VERSION ""

NS_ :

BS_:

BU_: PPIM HCP SGW IDCM EVCU2 BPCM

BO_ 1579 HYBRID_CHARGING_STATUS: 32 EVCU2
 SG_ HVBatteryVoltage_MinCal : 32|9@0+ (1,0) [0|510] "V"  IDCM,BPCM
 SG_ HVBatteryVoltage_MaxCal : 16|9@0+ (1,0) [0|510] "V"  IDCM,BPCM
 SG_ HVBatteryCurrent_MaxCal : 63|8@0+ (0.25,-32) [-32|31.5] "Amp"  IDCM,BPCM
 SG_ ChargeSystemFaultReason : 55|8@0+ (1,0) [0|254] "-"  IDCM
 SG_ ACCurrent_MaxCal : 0|9@0+ (0.25,-31.5) [-31.5|50] "Amp"  IDCM,BPCM
 SG_ ChargingLevel : 4|4@0+ (1,0) [0|14] "-"  IDCM,SGW,BPCM
 SG_ OBCM_PLUG_STS : 23|2@0+ (1,0) [0|3] ""  IDCM
 SG_ VDCM_UDCChrgr : 71|16@0+ (0.1,0) [0|6553.5] "V"  IDCM
 SG_ VDCM_IDCChrgr : 87|16@0+ (0.1,0) [0|6553.5] "A"  IDCM
 SG_ ChargeSystemSts : 7|3@0+ (1,0) [0|6] "-"  EVCU2,IDCM,BPCM
 SG_ ChargeSystemFault : 17|1@0+ (1,0) [0|1] "-"  IDCM
 SG_ CRC_HYBRID_CHARGING_STATUS : 191|8@0+ (1,0) [0|255] "-"  IDCM
 SG_ MessageCounter_HYBRID_CHARGING_S : 179|4@0+ (1,0) [0|15] "-"  IDCM

BO_ 478 HYBRID_CHARGING_COMMAND: 32 EVCU2
 SG_ LVDC_VoltageSetpoint : 111|8@0+ (0.0625,0) [0|15.875] "V"  BPCM
 SG_ LVDC_SystemVoltageAct : 64|9@0+ (0.04,0) [0|20.04] "V"  BPCM
 SG_ LVDC_CurrentSetpoint : 32|9@0+ (1,-255) [-255|255] "Amp"  BPCM
 SG_ HVInverterVoltage_Rational : 16|9@0+ (1,0) [0|510] "V"  BPCM
 SG_ HVDC_VoltageSetpoint : 48|9@0+ (1,0) [0|510] "V"  BPCM
 SG_ HVDC_CurrentSetpoint : 103|8@0+ (1,-125) [-125|129] "Amp"  BPCM
 SG_ EchargeSOCRange_ePT : 118|7@0+ (1,0) [0|100] "%" Vector__XXX
 SG_ CRC_HYBRID_CHARGING_COMMAND : 191|8@0+ (1,0) [0|255] "-"  IDCM,BPCM
 SG_ VoltageRequest : 4|13@0+ (0.1,0) [0|819.1] "Volts"  IDCM
 SG_ OBC_ModeRequest : 23|3@0+ (1,0) [0|6] "-"  IDCM
 SG_ OBC_ControlMethod : 38|2@0+ (1,0) [0|2] "-"  IDCM
 SG_ MainHV_ContactorCommand : 7|3@0+ (1,0) [0|7] "-"  BPCM
 SG_ J1772_CloseS2 : 51|1@0+ (1,0) [0|1] "-"  IDCM
 SG_ HVInverterVoltage_RationalV : 39|1@0+ (1,0) [0|1] "-"  BPCM
 SG_ HVBatCoolantLevelLow : 50|2@0+ (1,0) [0|2] "-"  BPCM
 SG_ DCDC_OperationModeEnable : 20|4@0+ (1,0) [0|14] "-"  BPCM
 SG_ ClearLegislatedDiagInfo : 52|1@0+ (1,0) [0|1] "-"  BPCM
 SG_ OBC_OperativeModeReq : 87|4@0+ (1,0) [0|14] "-"  IDCM
 SG_ HV_Volt_Min_Thrsh : 138|11@0+ (1,0) [0|2047] "V"  IDCM
 SG_ HV_Volt_Max_Thrsh : 133|11@0+ (1,0) [0|2047] "V"  IDCM
 SG_ DC_Curr_Max_Thrsh : 127|10@0+ (1,-511) [-511|512] "A"  IDCM
 SG_ ChargeEnable : 171|2@0+ (1,0) [0|2] "-"  IDCM
 SG_ AC_Curr_Min_Thrsh : 165|10@0+ (1,-511) [-511|512] "A"  IDCM
 SG_ AC_Curr_Max_Thrsh : 159|10@0+ (1,-511) [-511|512] "A"  IDCM
 SG_ CurrentRequest : 81|10@0+ (0.1,-32) [-32|70.3] "A"  IDCM
 SG_ VDCM_StsWldgReq : 83|1@0+ (1,0) [0|1] "-"  IDCM
 SG_ VDCM_SessnStopReq : 82|1@0+ (1,0) [0|1] "-"  IDCM
 SG_ VDCM_StsSWWldgReq : 55|2@0+ (1,0) [0|3] "-" Vector__XXX
 SG_ MessageCounter_HYBRID_CHARGING_C : 179|4@0+ (1,0) [0|15] "-"  IDCM,BPCM
 SG_ MaxCurrentAllwd : 71|6@0+ (1,0) [0|63] "A"  IDCM

BO_ 1578 HV_CHARGER2: 32 IDCM
 SG_ OBC_IdleTimeSec : 71|16@0+ (3,0) [0|196602] "sec"  EVCU2
 SG_ OBC_IdleTimeMin : 87|16@0+ (1,0) [0|65534] "min"  EVCU2
 SG_ OBC_ChargeTimeSec : 39|16@0+ (3,0) [0|196602] "sec"  EVCU2
 SG_ OBC_ChargeTimeMin : 55|16@0+ (1,0) [0|65534] "min"  EVCU2
 SG_ Charging_WHr : 23|16@0+ (1,0) [0|65534] "WHr"  EVCU2
 SG_ OnboardChargerReady : 116|2@0+ (1,0) [0|2] "-"  EVCU2
 SG_ OnboardChargerMode : 114|4@0+ (1,0) [0|15] "-"  EVCU2
 SG_ OBC_WakeReason : 107|4@0+ (1,0) [0|7] "-"  EVCU2
 SG_ OBC_GenericFailSts : 125|1@0+ (1,0) [0|1] "-"  EVCU2
 SG_ OBC_FaultReason : 102|7@0+ (1,0) [0|126] "-"  EVCU2
 SG_ OBC_EVServiceLampOn : 124|1@0+ (1,0) [0|1] "-"  EVCU2
 SG_ OBC_EVServiceLampFlash : 123|1@0+ (1,0) [0|1] "-"  EVCU2
 SG_ OBC_CurrentFailureSts : 121|1@0+ (1,0) [0|1] "-"  EVCU2
 SG_ OBC_ChargingFaultSts : 110|3@0+ (1,0) [0|7] "-"  EVCU2
 SG_ OBC_ChargeFailure : 120|1@0+ (1,0) [0|1] "-"  EVCU2
 SG_ OBC_CaptureEnvironmentData : 119|1@0+ (1,0) [0|1] "-"  EVCU2
 SG_ ACplug_PwrMax : 7|16@0+ (1,-32767) [-32767|32767] "W"  EVCU2
 SG_ OBC_Prox : 159|8@0+ (0.05,0) [0|12.75] "V"  EVCU2
 SG_ OBC_Pilot : 151|8@0+ (0.05,0) [0|12.75] "V"  EVCU2
 SG_ OBCM_PrechargeSts : 167|2@0+ (1,0) [0|3] "-"  EVCU2
 SG_ ChrgFailSts : 165|3@0+ (1,0) [0|7] ""  EVCU2

BO_ 1372 DUALCHARGER_THERMAL: 32 IDCM
 SG_ OBC_Temp4 : 63|8@0+ (1,-40) [-40|214] "°C"  EVCU2
 SG_ OBC_Temp3 : 55|8@0+ (1,-40) [-40|214] "°C"  EVCU2
 SG_ OBC_Temp2 : 47|8@0+ (1,-40) [-40|214] "°C"  EVCU2
 SG_ OBC_Temp1 : 39|8@0+ (1,-40) [-40|214] "°C"  EVCU2

BO_ 2564682064 DIAGNOSTIC_ROE_IDCM: 8 IDCM
 SG_ N_PDU_18DDF150 : 7|64@0+ (1,0) [0|0] ""  SGW

BO_ 2564682059 DIAGNOSTIC_ROE_HCP: 8 HCP
 SG_ N_PDU_18DDF14B : 7|64@0+ (1,0) [0|0] ""  SGW

BO_ 2564682320 DIAGNOSTIC_ROE_FD_IDCM: 64 IDCM
 SG_ N_PDU_18DDF250 : 7|64@0+ (1,0) [0|0] ""  SGW

BO_ 2564682315 DIAGNOSTIC_ROE_FD_HCP: 64 HCP
 SG_ N_PDU_18DDF24B : 7|64@0+ (1,0) [0|0] ""  SGW

BO_ 2564682308 DIAGNOSTIC_ROE_FD_BPCM: 64 BPCM
 SG_ N_PDU_18DDF244 : 7|64@0+ (1,0) [0|0] ""  SGW,HCP

BO_ 2564682052 DIAGNOSTIC_ROE_BPCM: 8 BPCM
 SG_ N_PDU_18DDF144 : 7|64@0+ (1,0) [0|0] ""  SGW

BO_ 2564485712 DIAGNOSTIC_RESPONSE_FD_IDCM: 64 IDCM
 SG_ N_PDU_18DAF250 : 7|64@0+ (1,0) [0|0] ""  SGW

BO_ 2564485707 DIAGNOSTIC_RESPONSE_FD_HCP: 64 HCP
 SG_ N_PDU_18DAF24B : 7|64@0+ (1,0) [0|0] ""  SGW

BO_ 2564485700 DIAGNOSTIC_RESPONSE_FD_BPCM: 64 BPCM
 SG_ N_PDU_18DAF244 : 7|64@0+ (1,0) [0|0] ""  SGW,HCP

BO_ 2564444402 DIAGNOSTIC_REQUEST_FD_IDCM: 64 SGW
 SG_ N_PDU_18DA50F2 : 7|64@0+ (1,0) [0|0] ""  IDCM

BO_ 2564443122 DIAGNOSTIC_REQUEST_FD_HCP: 64 SGW
 SG_ N_PDU_18DA4BF2 : 7|64@0+ (1,0) [0|0] ""  HCP

BO_ 2564441330 DIAGNOSTIC_REQUEST_FD_BPCM: 64 SGW
 SG_ N_PDU_18DA44F2 : 7|64@0+ (1,0) [0|0] ""  BPCM

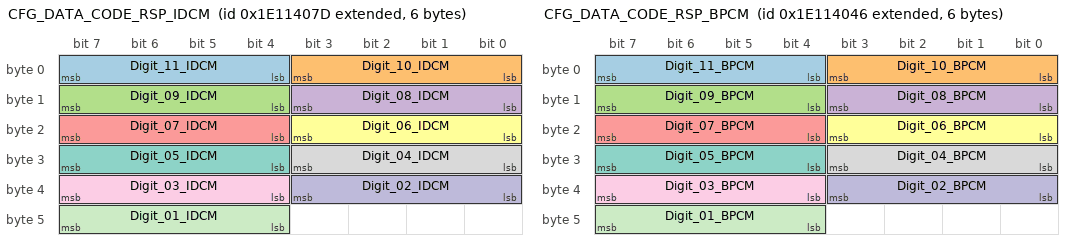
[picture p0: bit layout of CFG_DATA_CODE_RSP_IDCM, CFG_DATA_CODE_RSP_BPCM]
BO_ 2651930749 CFG_DATA_CODE_RSP_IDCM: 6 IDCM
 SG_ Digit_11_IDCM : 7|4@0+ (1,0) [0|15] "-"  EVCU2,SGW
 SG_ Digit_10_IDCM : 3|4@0+ (1,0) [0|15] "-"  EVCU2,SGW
 SG_ Digit_09_IDCM : 15|4@0+ (1,0) [0|15] "-"  EVCU2,SGW
 SG_ Digit_08_IDCM : 11|4@0+ (1,0) [0|15] "-"  EVCU2,SGW
 SG_ Digit_07_IDCM : 23|4@0+ (1,0) [0|15] "-"  EVCU2,SGW
 SG_ Digit_06_IDCM : 19|4@0+ (1,0) [0|15] "-"  EVCU2,SGW
 SG_ Digit_05_IDCM : 31|4@0+ (1,0) [0|15] "-"  EVCU2,SGW
 SG_ Digit_04_IDCM : 27|4@0+ (1,0) [0|15] "-"  EVCU2,SGW
 SG_ Digit_03_IDCM : 39|4@0+ (1,0) [0|15] "-"  EVCU2,SGW
 SG_ Digit_02_IDCM : 35|4@0+ (1,0) [0|15] "-"  EVCU2,SGW
 SG_ Digit_01_IDCM : 47|4@0+ (1,0) [0|15] "-"  EVCU2,SGW

BO_ 2651930694 CFG_DATA_CODE_RSP_BPCM: 6 BPCM
 SG_ Digit_11_BPCM : 7|4@0+ (1,0) [0|15] "-"  EVCU2,HCP
 SG_ Digit_10_BPCM : 3|4@0+ (1,0) [0|15] "-"  EVCU2,HCP
 SG_ Digit_09_BPCM : 15|4@0+ (1,0) [0|15] "-"  EVCU2,HCP
 SG_ Digit_08_BPCM : 11|4@0+ (1,0) [0|15] "-"  EVCU2,HCP
 SG_ Digit_07_BPCM : 23|4@0+ (1,0) [0|15] "-"  EVCU2,HCP
 SG_ Digit_06_BPCM : 19|4@0+ (1,0) [0|15] "-"  EVCU2,HCP
 SG_ Digit_05_BPCM : 31|4@0+ (1,0) [0|15] "-"  EVCU2,HCP
 SG_ Digit_04_BPCM : 27|4@0+ (1,0) [0|15] "-"  EVCU2,HCP
 SG_ Digit_03_BPCM : 39|4@0+ (1,0) [0|15] "-"  EVCU2,HCP
 SG_ Digit_02_BPCM : 35|4@0+ (1,0) [0|15] "-"  EVCU2,HCP
 SG_ Digit_01_BPCM : 47|4@0+ (1,0) [0|15] "-"  EVCU2,HCP

BO_ 2654339170 PDC_INFO_FD_HCP: 12 HCP
 SG_ GenericFailSts_FD03_HCP : 5|1@0+ (1,0) [0|1] ""  SGW
 SG_ EOL_FD03_HCP : 7|1@0+ (1,0) [0|1] "-"  SGW
 SG_ CurrentFailSts_FD03_HCP : 6|1@0+ (1,0) [0|1] ""  SGW
 SG_ WakeupSource_FD03_HCP : 23|8@0+ (1,0) [0|255] ""  SGW
 SG_ PreviousCanNMState_FD03_HCP : 11|4@0+ (1,0) [0|15] ""  SGW
 SG_ DES_FD03_HCP : 4|2@0+ (1,0) [0|3] ""  SGW
 SG_ CurrentCanNMState_FD03_HCP : 15|4@0+ (1,0) [0|15] ""  SGW
 SG_ StayActiveSource_FD03_HCP : 31|64@0+ (1,0) [0|1.84467440737096E+019] ""  SGW

BO_ 1845 HVBATTERY_RM_BATTERYID: 64 BPCM
 SG_ HVBatSerialLength : 199|8@0+ (1,0) [0|254] ""  SGW
 SG_ HVBatSerialNumber : 7|192@0+ (1,0) [0|0] ""  SGW

BO_ 1460 FOTA_MASTER: 32 SGW
 SG_ FOTA_Status : 7|4@0+ (1,0) [0|15] ""  EVCU2,IDCM,BPCM

BO_ 1374 HVBATTERY4: 48 BPCM
 SG_ HVBatPackVoltage_MaxAllowedV : 6|1@0+ (1,0) [0|0] "-"  HCP
 SG_ HVBatCellVoltage_MinAllowedV : 5|1@0+ (1,0) [0|0] "-"  HCP
 SG_ HVBatCellVoltage_MinAllowed : 19|12@0+ (0.001,1.5) [1.5|4.5] "Volts"  HCP
 SG_ HVBatCellVoltage_MaxAllowedV : 4|1@0+ (1,0) [0|0] "-"  HCP
 SG_ HVBatCellVoltage_MaxAllowed : 3|12@0+ (0.001,1.5) [1.5|4.5] "Volts"  HCP
 SG_ HVBatCellVoltage_LowThreshold : 84|13@0+ (0.001,0) [0|5] "Volts"  HCP
 SG_ HVBatCellVoltage_HighThreshold : 68|13@0+ (0.001,0) [0|5] "Volts"  HCP
 SG_ HVBatCapacity_AmpHrV : 22|1@0+ (1,0) [0|0] "-" Vector__XXX
 SG_ HVBatCapacity_AmpHr : 114|11@0+ (0.1,0) [0|200] "Ah" Vector__XXX
 SG_ HVBatRemainingAhCapacity : 186|11@0+ (0.1,0) [0|200] "Ah"  HCP
 SG_ HVBatDischargeAmpHrs : 167|24@0+ (0.1,0) [0|300000] "Ah"  HCP
 SG_ HVBatChargeAmpHrs : 143|24@0+ (0.1,0) [0|300000] "Ah"  HCP
 SG_ BSGPackVoltage_MaxAllowed : 39|7@0+ (1,0) [20|70] "V"  HCP

BO_ 1038 HVBATTERY_STATUS: 32 BPCM
 SG_ Precharge_Closed : 121|1@0+ (1,0) [0|1] ""  HCP
 SG_ Positive_Main_Closed : 122|1@0+ (1,0) [0|1] ""  HCP
 SG_ Negative_Main_Closed : 123|1@0+ (1,0) [0|1] ""  HCP
 SG_ HBCO_TempSensorRationality : 125|1@0+ (1,0) [0|1] ""  HCP
 SG_ HBCO_Sensor_Fault : 126|1@0+ (1,0) [0|1] ""  HCP
 SG_ HBCO_PackUndertemp : 105|1@0+ (1,0) [0|1] ""  HCP
 SG_ HBCO_PackOvertemp : 106|1@0+ (1,0) [0|1] ""  HCP
 SG_ HBCO_OverCurrent : 127|1@0+ (1,0) [0|1] ""  HCP
 SG_ HBCO_Micro_Failure : 112|1@0+ (1,0) [0|1] ""  HCP
 SG_ HBCO_Main_Fuse_Failure : 113|1@0+ (1,0) [0|1] ""  HCP
 SG_ HBCO_Isolation_Fault : 114|1@0+ (1,0) [0|1] ""  HCP
 SG_ HBCO_Internal_CommFault : 117|1@0+ (1,0) [0|1] ""  HCP
 SG_ HBCO_Impact_Detected : 115|1@0+ (1,0) [0|1] ""  HCP
 SG_ HBCO_HVIL_Failure : 116|1@0+ (1,0) [0|1] ""  HCP
 SG_ HBCO_External_CommFault : 118|1@0+ (1,0) [0|1] ""  HCP
 SG_ HBCO_CellUndervoltage : 119|1@0+ (1,0) [0|1] ""  HCP
 SG_ HBCO_CellOvervoltage : 104|1@0+ (1,0) [0|1] ""  HCP
 SG_ HBCO_12V_Low : 107|1@0+ (1,0) [0|1] ""  HCP
 SG_ HBCO_12V_High : 108|1@0+ (1,0) [0|1] ""  HCP
 SG_ HBCNC_TempSensorRationality : 110|1@0+ (1,0) [0|1] ""  HCP
 SG_ HBCNC_SOH_Failure : 111|1@0+ (1,0) [0|1] ""  HCP
 SG_ HBCNC_Sensor_Failure : 96|1@0+ (1,0) [0|1] ""  HCP
 SG_ HBCNC_Precharge_Failure : 97|1@0+ (1,0) [0|1] ""  HCP
 SG_ HBCNC_PackUndervoltage : 98|1@0+ (1,0) [0|1] ""  HCP
 SG_ HBCNC_PackUndertemp : 93|1@0+ (1,0) [0|1] ""  HCP
 SG_ HBCNC_PackOvervoltage : 99|1@0+ (1,0) [0|1] ""  HCP
 SG_ HBCNC_PackOvertemp : 94|1@0+ (1,0) [0|1] ""  HCP
 SG_ HBCNC_Micro_Failure : 100|1@0+ (1,0) [0|1] ""  HCP
 SG_ HBCNC_Main_Fuse_Failure : 101|1@0+ (1,0) [0|1] ""  HCP
 SG_ HBCNC_Isolation_Fault : 102|1@0+ (1,0) [0|1] ""  HCP
 SG_ HBCNC_Internal_CommFault : 89|1@0+ (1,0) [0|1] ""  HCP
 SG_ HBCNC_Impact_Detected : 103|1@0+ (1,0) [0|1] ""  HCP
 SG_ HBCNC_External_CommFault : 90|1@0+ (1,0) [0|1] ""  HCP
 SG_ HBCNC_EEPROM_Fault : 88|1@0+ (1,0) [0|1] ""  HCP
 SG_ HBCNC_Contactors_Welded : 109|1@0+ (1,0) [0|1] ""  HCP
 SG_ HBCNC_CellUndervoltage : 91|1@0+ (1,0) [0|1] ""  HCP
 SG_ HBCNC_CellOvervoltage : 92|1@0+ (1,0) [0|1] ""  HCP
 SG_ HBCNC_12V_Low : 95|1@0+ (1,0) [0|1] ""  HCP
 SG_ HBCNC_12V_High : 38|1@0+ (1,0) [0|1] ""  HCP
 SG_ BPCM_DTC_Status6 : 87|3@0+ (1,0) [0|6] ""  HCP
 SG_ BPCM_DTC_Status5 : 79|3@0+ (1,0) [0|6] ""  HCP
 SG_ BPCM_DTC_Status4 : 71|3@0+ (1,0) [0|6] ""  HCP
 SG_ BPCM_DTC_Status3 : 63|3@0+ (1,0) [0|6] ""  HCP
 SG_ BPCM_DTC_Status2 : 55|3@0+ (1,0) [0|6] ""  HCP
 SG_ BPCM_DTC_Status1 : 47|3@0+ (1,0) [0|6] ""  HCP
 SG_ BPCM_DTC_Index6 : 84|5@0+ (1,0) [0|31] ""  HCP
 SG_ BPCM_DTC_Index5 : 76|5@0+ (1,0) [0|31] ""  HCP
 SG_ BPCM_DTC_Index4 : 68|5@0+ (1,0) [0|31] ""  HCP
 SG_ BPCM_DTC_Index3 : 60|5@0+ (1,0) [0|31] ""  HCP
 SG_ BPCM_DTC_Index2 : 52|5@0+ (1,0) [0|31] ""  HCP
 SG_ BPCM_DTC_Index1 : 44|5@0+ (1,0) [0|31] ""  HCP
 SG_ BPCM_CalibrationVN : 31|8@0+ (1,0) [0|255] ""  HCP
 SG_ BPCM_CalibrationID : 37|6@0+ (1,0) [0|62] ""  HCP
 SG_ BPCM_Odometer : 7|24@0+ (0.1,0) [0|1677720] "km"  HCP

BO_ 1852 HVBATTERY_RM_CELLS8: 64 BPCM
 SG_ HVBatCellVoltage_Cell192 : 36|13@0+ (0.001,0) [0|5] "V" Vector__XXX
 SG_ HVBatCellVoltage_Cell191 : 20|13@0+ (0.001,0) [0|5] "V" Vector__XXX
 SG_ HVBatCellVoltage_Cell190 : 4|13@0+ (0.001,0) [0|5] "V" Vector__XXX
 SG_ HVBatCellVoltage_Cell216 : 420|13@0+ (0.001,0) [0|5] "V"  SGW
 SG_ HVBatCellVoltage_Cell215 : 404|13@0+ (0.001,0) [0|5] "V" Vector__XXX
 SG_ HVBatCellVoltage_Cell214 : 388|13@0+ (0.001,0) [0|5] "V" Vector__XXX
 SG_ HVBatCellVoltage_Cell213 : 372|13@0+ (0.001,0) [0|5] "V" Vector__XXX
 SG_ HVBatCellVoltage_Cell212 : 356|13@0+ (0.001,0) [0|5] "V" Vector__XXX
 SG_ HVBatCellVoltage_Cell211 : 340|13@0+ (0.001,0) [0|5] "V" Vector__XXX
 SG_ HVBatCellVoltage_Cell210 : 324|13@0+ (0.001,0) [0|5] "V" Vector__XXX
 SG_ HVBatCellVoltage_Cell209 : 308|13@0+ (0.001,0) [0|5] "V" Vector__XXX
 SG_ HVBatCellVoltage_Cell208 : 292|13@0+ (0.001,0) [0|5] "V" Vector__XXX
 SG_ HVBatCellVoltage_Cell207 : 276|13@0+ (0.001,0) [0|5] "V" Vector__XXX
 SG_ HVBatCellVoltage_Cell206 : 260|13@0+ (0.001,0) [0|5] "V" Vector__XXX
 SG_ HVBatCellVoltage_Cell205 : 244|13@0+ (0.001,0) [0|5] "V" Vector__XXX
 SG_ HVBatCellVoltage_Cell204 : 228|13@0+ (0.001,0) [0|5] "V" Vector__XXX
 SG_ HVBatCellVoltage_Cell203 : 212|13@0+ (0.001,0) [0|5] "V" Vector__XXX
 SG_ HVBatCellVoltage_Cell202 : 196|13@0+ (0.001,0) [0|5] "V" Vector__XXX
 SG_ HVBatCellVoltage_Cell201 : 180|13@0+ (0.001,0) [0|5] "V" Vector__XXX
 SG_ HVBatCellVoltage_Cell200 : 164|13@0+ (0.001,0) [0|5] "V" Vector__XXX
 SG_ HVBatCellVoltage_Cell198 : 132|13@0+ (0.001,0) [0|5] "V" Vector__XXX
 SG_ HVBatCellVoltage_Cell197 : 116|13@0+ (0.001,0) [0|5] "V" Vector__XXX
 SG_ HVBatCellVoltage_Cell196 : 100|13@0+ (0.001,0) [0|5] "V" Vector__XXX
 SG_ HVBatCellVoltage_Cell195 : 84|13@0+ (0.001,0) [0|5] "V" Vector__XXX
 SG_ HVBatCellVoltage_Cell194 : 68|13@0+ (0.001,0) [0|5] "V" Vector__XXX
 SG_ HVBatCellVoltage_Cell193 : 52|13@0+ (0.001,0) [0|5] "V" Vector__XXX

BO_ 1851 HVBATTERY_RM_CELLS7: 64 BPCM
 SG_ HVBatCellVoltage_Cell189 : 420|13@0+ (0.001,0) [0|5] "V" Vector__XXX
 SG_ HVBatCellVoltage_Cell188 : 404|13@0+ (0.001,0) [0|5] "V" Vector__XXX
 SG_ HVBatCellVoltage_Cell187 : 388|13@0+ (0.001,0) [0|5] "V" Vector__XXX
 SG_ HVBatCellVoltage_Cell186 : 372|13@0+ (0.001,0) [0|5] "V" Vector__XXX
 SG_ HVBatCellVoltage_Cell185 : 356|13@0+ (0.001,0) [0|5] "V" Vector__XXX
 SG_ HVBatCellVoltage_Cell184 : 340|13@0+ (0.001,0) [0|5] "V" Vector__XXX
 SG_ HVBatCellVoltage_Cell183 : 324|13@0+ (0.001,0) [0|5] "V"  SGW
 SG_ HVBatCellVoltage_Cell182 : 308|13@0+ (0.001,0) [0|5] "V"  SGW
 SG_ HVBatCellVoltage_Cell181 : 292|13@0+ (0.001,0) [0|5] "V"  SGW
 SG_ HVBatCellVoltage_Cell180 : 276|13@0+ (0.001,0) [0|5] "V"  SGW
 SG_ HVBatCellVoltage_Cell179 : 260|13@0+ (0.001,0) [0|5] "V"  SGW
 SG_ HVBatCellVoltage_Cell178 : 244|13@0+ (0.001,0) [0|5] "V"  SGW
 SG_ HVBatCellVoltage_Cell177 : 228|13@0+ (0.001,0) [0|5] "V"  SGW
 SG_ HVBatCellVoltage_Cell176 : 212|13@0+ (0.001,0) [0|5] "V"  SGW
 SG_ HVBatCellVoltage_Cell175 : 196|13@0+ (0.001,0) [0|5] "V"  SGW
 SG_ HVBatCellVoltage_Cell174 : 180|13@0+ (0.001,0) [0|5] "V"  SGW
 SG_ HVBatCellVoltage_Cell173 : 164|13@0+ (0.001,0) [0|5] "V"  SGW
 SG_ HVBatCellVoltage_Cell172 : 148|13@0+ (0.001,0) [0|5] "V"  SGW
 SG_ HVBatCellVoltage_Cell171 : 132|13@0+ (0.001,0) [0|5] "V"  SGW
 SG_ HVBatCellVoltage_Cell170 : 116|13@0+ (0.001,0) [0|5] "V"  SGW
 SG_ HVBatCellVoltage_Cell169 : 100|13@0+ (0.001,0) [0|5] "V"  SGW
 SG_ HVBatCellVoltage_Cell168 : 84|13@0+ (0.001,0) [0|5] "V"  SGW
 SG_ HVBatCellVoltage_Cell167 : 68|13@0+ (0.001,0) [0|5] "V"  SGW
 SG_ HVBatCellVoltage_Cell166 : 52|13@0+ (0.001,0) [0|5] "V"  SGW
 SG_ HVBatCellVoltage_Cell165 : 36|13@0+ (0.001,0) [0|5] "V"  SGW
 SG_ HVBatCellVoltage_Cell164 : 20|13@0+ (0.001,0) [0|5] "V"  SGW
 SG_ HVBatCellVoltage_Cell163 : 4|13@0+ (0.001,0) [0|5] "V"  SGW

BO_ 1850 HVBATTERY_RM_CELLS6: 64 BPCM
 SG_ HVBatCellVoltage_Cell162 : 420|13@0+ (0.001,0) [0|5] "V"  SGW
 SG_ HVBatCellVoltage_Cell161 : 404|13@0+ (0.001,0) [0|5] "V"  SGW
 SG_ HVBatCellVoltage_Cell160 : 388|13@0+ (0.001,0) [0|5] "V"  SGW
 SG_ HVBatCellVoltage_Cell159 : 372|13@0+ (0.001,0) [0|5] "V"  SGW
 SG_ HVBatCellVoltage_Cell158 : 356|13@0+ (0.001,0) [0|5] "V"  SGW
 SG_ HVBatCellVoltage_Cell157 : 340|13@0+ (0.001,0) [0|5] "V"  SGW
 SG_ HVBatCellVoltage_Cell156 : 324|13@0+ (0.001,0) [0|5] "V"  SGW
 SG_ HVBatCellVoltage_Cell155 : 308|13@0+ (0.001,0) [0|5] "V"  SGW
 SG_ HVBatCellVoltage_Cell154 : 292|13@0+ (0.001,0) [0|5] "V"  SGW
 SG_ HVBatCellVoltage_Cell153 : 276|13@0+ (0.001,0) [0|5] "V"  SGW
 SG_ HVBatCellVoltage_Cell152 : 260|13@0+ (0.001,0) [0|5] "V"  SGW
 SG_ HVBatCellVoltage_Cell151 : 244|13@0+ (0.001,0) [0|5] "V"  SGW
 SG_ HVBatCellVoltage_Cell150 : 228|13@0+ (0.001,0) [0|5] "V"  SGW
 SG_ HVBatCellVoltage_Cell149 : 212|13@0+ (0.001,0) [0|5] "V"  SGW
 SG_ HVBatCellVoltage_Cell148 : 196|13@0+ (0.001,0) [0|5] "V"  SGW
 SG_ HVBatCellVoltage_Cell147 : 180|13@0+ (0.001,0) [0|5] "V"  SGW
 SG_ HVBatCellVoltage_Cell146 : 164|13@0+ (0.001,0) [0|5] "V"  SGW
 SG_ HVBatCellVoltage_Cell145 : 148|13@0+ (0.001,0) [0|5] "V"  SGW
 SG_ HVBatCellVoltage_Cell144 : 132|13@0+ (0.001,0) [0|5] "V"  SGW
 SG_ HVBatCellVoltage_Cell143 : 116|13@0+ (0.001,0) [0|5] "V"  SGW
 SG_ HVBatCellVoltage_Cell142 : 100|13@0+ (0.001,0) [0|5] "V"  SGW
 SG_ HVBatCellVoltage_Cell141 : 84|13@0+ (0.001,0) [0|5] "V"  SGW
 SG_ HVBatCellVoltage_Cell140 : 68|13@0+ (0.001,0) [0|5] "V"  SGW
 SG_ HVBatCellVoltage_Cell139 : 52|13@0+ (0.001,0) [0|5] "V"  SGW
 SG_ HVBatCellVoltage_Cell138 : 36|13@0+ (0.001,0) [0|5] "V"  SGW
 SG_ HVBatCellVoltage_Cell137 : 20|13@0+ (0.001,0) [0|5] "V"  SGW
 SG_ HVBatCellVoltage_Cell136 : 4|13@0+ (0.001,0) [0|5] "V"  SGW

BO_ 1849 HVBATTERY_RM_CELLS5: 64 BPCM
 SG_ HVBatCellVoltage_Cell135 : 420|13@0+ (0.001,0) [0|5] "V"  SGW
 SG_ HVBatCellVoltage_Cell134 : 404|13@0+ (0.001,0) [0|5] "V"  SGW
 SG_ HVBatCellVoltage_Cell133 : 388|13@0+ (0.001,0) [0|5] "V"  SGW
 SG_ HVBatCellVoltage_Cell132 : 372|13@0+ (0.001,0) [0|5] "V"  SGW
 SG_ HVBatCellVoltage_Cell131 : 356|13@0+ (0.001,0) [0|5] "V"  SGW
 SG_ HVBatCellVoltage_Cell130 : 340|13@0+ (0.001,0) [0|5] "V"  SGW
 SG_ HVBatCellVoltage_Cell129 : 324|13@0+ (0.001,0) [0|5] "V"  SGW
 SG_ HVBatCellVoltage_Cell128 : 308|13@0+ (0.001,0) [0|5] "V"  SGW
 SG_ HVBatCellVoltage_Cell127 : 292|13@0+ (0.001,0) [0|5] "V"  SGW
 SG_ HVBatCellVoltage_Cell126 : 276|13@0+ (0.001,0) [0|5] "V"  SGW
 SG_ HVBatCellVoltage_Cell125 : 260|13@0+ (0.001,0) [0|5] "V"  SGW
 SG_ HVBatCellVoltage_Cell124 : 244|13@0+ (0.001,0) [0|5] "V"  SGW
 SG_ HVBatCellVoltage_Cell123 : 228|13@0+ (0.001,0) [0|5] "V"  SGW
 SG_ HVBatCellVoltage_Cell122 : 212|13@0+ (0.001,0) [0|5] "V"  SGW
 SG_ HVBatCellVoltage_Cell121 : 196|13@0+ (0.001,0) [0|5] "V"  SGW
 SG_ HVBatCellVoltage_Cell120 : 180|13@0+ (0.001,0) [0|5] "V"  SGW
 SG_ HVBatCellVoltage_Cell119 : 164|13@0+ (0.001,0) [0|5] "V"  SGW
 SG_ HVBatCellVoltage_Cell118 : 148|13@0+ (0.001,0) [0|5] "V"  SGW
 SG_ HVBatCellVoltage_Cell117 : 132|13@0+ (0.001,0) [0|5] "V"  SGW
 SG_ HVBatCellVoltage_Cell116 : 116|13@0+ (0.001,0) [0|5] "V"  SGW
 SG_ HVBatCellVoltage_Cell115 : 100|13@0+ (0.001,0) [0|5] "V"  SGW
 SG_ HVBatCellVoltage_Cell114 : 84|13@0+ (0.001,0) [0|5] "V"  SGW
 SG_ HVBatCellVoltage_Cell113 : 68|13@0+ (0.001,0) [0|5] "V"  SGW
 SG_ HVBatCellVoltage_Cell112 : 52|13@0+ (0.001,0) [0|5] "V"  SGW
 SG_ HVBatCellVoltage_Cell111 : 36|13@0+ (0.001,0) [0|5] "V"  SGW
 SG_ HVBatCellVoltage_Cell110 : 20|13@0+ (0.001,0) [0|5] "V"  SGW
 SG_ HVBatCellVoltage_Cell109 : 4|13@0+ (0.001,0) [0|5] "V"  SGW

BO_ 502 VDCM_OBCM: 48 EVCU2
 SG_ VDCM_OBCDischCurrentLim : 265|14@0+ (0.1,-815) [-815|823.3] "A"  IDCM
 SG_ VDCM_BattBulkSOC : 283|10@0+ (0.1,0) [0|100] "%"  IDCM
 SG_ HVCMS_ServiceScope : 87|16@0+ (1,0) [0|65534] ""  IDCM
 SG_ HVCMS_ReadyToChargeState : 271|1@0+ (1,0) [0|1] ""  IDCM
 SG_ HVCMS_Protocol_Entry3 : 39|16@0+ (1,0) [0|65534] ""  IDCM
 SG_ HVCMS_Protocol_Entry2 : 23|16@0+ (1,0) [0|65534] ""  IDCM
 SG_ HVCMS_Protocol_Entry1 : 7|16@0+ (1,0) [0|65534] ""  IDCM
 SG_ HVCMS_EVTargetVoltage : 247|14@0+ (0.1,0) [0|1638.2] "V"  IDCM
 SG_ HVCMS_EVTargetCurrent : 249|10@0+ (1,-500) [-500|522] ""  IDCM
 SG_ HVCMS_EVRESSConditioning : 171|1@0+ (1,0) [0|1] ""  IDCM
 SG_ HVCMS_EVRESS_SOC : 159|12@0+ (0.02442,0) [0|99.97548] "%"  IDCM
 SG_ HVCMS_EVReady : 170|1@0+ (1,0) [0|1] ""  IDCM
 SG_ HVCMS_EVMax_V_Limit : 215|14@0+ (0.1,0) [0|1638.2] "V"  IDCM
 SG_ HVCMS_EVMax_P_Limit : 191|24@0+ (0.1,0) [0|1677721.4] "W"  IDCM
 SG_ HVCMS_EVMax_I_Limit : 169|10@0+ (1,-500) [-500|522] "A"  IDCM
 SG_ HVCMS_EVEnergyCapacity : 217|17@0+ (1,0) [0|131070] "Wh"  IDCM
 SG_ HVCMS_ChargingComplete : 269|1@0+ (1,0) [0|1] ""  IDCM
 SG_ HVCMS_BulkChargingComplete : 270|1@0+ (1,0) [0|1] ""  IDCM
 SG_ VDCM_TypeCNegotiationSts : 378|3@0+ (1,0) [0|7] ""  IDCM
 SG_ VDCM_GenChallenge : 362|16@0+ (1,0) [0|65535] ""  IDCM
 SG_ VDCM_ContractAuthenticationID : 346|16@0+ (1,0) [0|65535] ""  IDCM
 SG_ HVCMS_EVEnergyRequest : 331|17@0+ (1,0) [0|131071] "Wh"  IDCM
 SG_ OBCM_OutVoltageSyncTgt : 289|10@0+ (1,0) [0|1022] "V"  IDCM
 SG_ HVCMS_ServiceCategory : 103|4@0+ (1,0) [0|15] ""  IDCM
 SG_ HVCMS_SelectedServiceId : 135|16@0+ (1,0) [0|65535] ""  IDCM
 SG_ HVCMS_SelectedPaymentOptn : 119|2@0+ (1,0) [0|3] ""  IDCM
 SG_ HVCMS_SelectedEnergyTransferType : 151|4@0+ (1,0) [0|15] ""  IDCM
 SG_ HVCMS_RemaningTimeToFullSOC : 71|16@0+ (1,0) [0|65535] "sec"  IDCM
 SG_ HVCMS_RemaningTimeToBulkSOC : 55|16@0+ (1,0) [0|65534] ""  IDCM
 SG_ HVCMS_EVErrorCode : 163|4@0+ (1,0) [0|15] ""  IDCM

BO_ 242 PIM_F: 64 EVCU2
 SG_ MC_PF1 : 499|4@0+ (1,0) [0|15] "-"  BPCM
 SG_ CRC_PF1 : 511|8@0+ (1,0) [0|255] "-"  BPCM
 SG_ MCPA_DC_Current : 63|15@0+ (0.1,-1638.4) [-1638.4|1638.3] "A"  BPCM

BO_ 498 OBCM_VDCM: 48 IDCM
 SG_ HVCMS_EVSEPresentVoltage : 250|14@0+ (0.1,0) [0|1638.3] "V"  EVCU2
 SG_ HVCMS_EVSEPeakCurrentRipple : 199|10@0+ (1,-500) [-500|523] "A"  EVCU2
 SG_ HVCMS_EVSEMinCurrentLimit : 157|10@0+ (1,-500) [-500|523] "A"  EVCU2
 SG_ HVCMS_EVSEMaxPowerLimit : 205|24@0+ (0.1,0) [0|1677721.5] "W"  EVCU2
 SG_ HVCMS_EVSEMaxCurrentLimit : 151|10@0+ (1,-500) [-500|523] "A"  EVCU2
 SG_ HVCMS_EVSECurrRegulationTol : 244|10@0+ (1,-500) [-500|523] "A"  EVCU2
 SG_ HVCMS_EnergyToBeDelivered : 229|17@0+ (1,0) [0|131071] "Wh"  EVCU2
 SG_ EVSE_IsolationSts : 143|3@0+ (1,0) [0|7] ""  EVCU2
 SG_ EVSE_Accepted_Protocol : 39|16@0+ (1,0) [0|65535] ""  EVCU2
 SG_ DC_TimeOut : 139|1@0+ (1,0) [0|1] ""  EVCU2
 SG_ DC_Isolation_Disable_Cmd : 140|1@0+ (1,0) [0|1] ""  EVCU2
 SG_ OBCM_PLCTypeSts : 337|3@0+ (1,0) [0|6] ""  EVCU2
 SG_ HVCMS_EVSEVoltageLimitAchieved : 286|2@0+ (1,0) [0|3] ""  EVCU2
 SG_ HVCMS_EVSEPowerLimitAchieved : 272|2@0+ (1,0) [0|3] ""  EVCU2
 SG_ HVCMS_EVSEMinimumVoltageLimit : 300|16@0+ (0.1,0) [0|6553.4] "V"  EVCU2
 SG_ HVCMS_EVSEMaximumVoltageLimit : 284|16@0+ (0.1,0) [0|6553.4] "V"  EVCU2
 SG_ HVCMS_EVSECurrentLimitAchieved : 274|2@0+ (1,0) [0|3] ""  EVCU2
 SG_ HVCMS_EVSEPresentCurrent : 350|16@0+ (0.02,0) [0|1310.7] "A"  EVCU2
 SG_ EVSE_OfferedEnergyTransferType : 103|4@0+ (1,0) [0|15] ""  EVCU2
 SG_ HVCMS_TxMessageStat : 7|5@0+ (1,0) [0|31] ""  EVCU2
 SG_ HVCMS_ResponseCode : 23|5@0+ (1,0) [0|31] ""  EVCU2
 SG_ HVCMS_EVSEProcessing : 119|1@0+ (1,0) [0|1] ""  EVCU2
 SG_ EVSE_FreeService : 71|1@0+ (1,0) [0|1] ""  EVCU2
 SG_ TxMessageResponse : 70|5@0+ (1,0) [0|31] ""  EVCU2
 SG_ HVCMS_EVSEStatusCode : 135|4@0+ (1,0) [0|15] ""  EVCU2
 SG_ EVSE_ServiceId : 55|16@0+ (1,0) [0|65535] ""  EVCU2
 SG_ EVSE_OfferedService : 138|3@0+ (1,0) [0|7] ""  EVCU2
 SG_ EVSE_OfferedPaymentOptn : 87|2@0+ (1,0) [0|3] ""  EVCU2
 SG_ MC_OBCM_VDCM : 371|4@0+ (1,0) [0|15] ""  EVCU2
 SG_ EVSE_Supported_ISO1 : 64|1@0+ (1,0) [0|1] ""  EVCU2
 SG_ EVSE_Supported_DIN : 65|1@0+ (1,0) [0|1] "-"  EVCU2
 SG_ CRC_OBCM_VDCM : 383|8@0+ (1,0) [0|255] ""  EVCU2
 SG_ EVSE_Supported_SAE : 31|1@0+ (1,0) [0|1] ""  EVCU2
 SG_ EVSE_Service2_Certificate : 16|1@0+ (1,0) [0|1] "-"  EVCU2
 SG_ EVSE_OfferedPaymentEIM : 18|1@0+ (1,0) [0|1] "-"  EVCU2
 SG_ EVSE_OfferedPaymentContract : 17|1@0+ (1,0) [0|1] "-"  EVCU2
 SG_ EVSE_Notification : 2|2@0+ (1,0) [0|3] ""  EVCU2

BO_ 2564682261 DIAGNOSTIC_ROE_FD_MCPB: 64 EVCU2
 SG_ N_PDU_18DDF215 : 7|64@0+ (1,0) [0|0] ""  SGW

BO_ 2564682260 DIAGNOSTIC_ROE_FD_MCPA: 64 EVCU2
 SG_ N_PDU_18DDF214 : 7|64@0+ (1,0) [0|0] ""  SGW

BO_ 2564485396 DIAGNOSTIC_RESPONSE_MCPA: 8 EVCU2
 SG_ N_PDU_18DAF114 : 7|64@0+ (1,0) [0|0] ""  SGW

BO_ 2564485653 DIAGNOSTIC_RESPONSE_FD_MCPB: 64 EVCU2
 SG_ N_PDU_18DAF215 : 7|64@0+ (1,0) [0|0] ""  SGW

BO_ 2564485652 DIAGNOSTIC_RESPONSE_FD_MCPA: 64 EVCU2
 SG_ N_PDU_18DAF214 : 7|64@0+ (1,0) [0|0] ""  SGW

BO_ 2564429297 DIAGNOSTIC_REQUEST_MCPB: 8 SGW
 SG_ N_PDU_18DA15F1 : 7|64@0+ (1,0) [0|0] ""  EVCU2

BO_ 2564429041 DIAGNOSTIC_REQUEST_MCPA: 8 SGW
 SG_ N_PDU_18DA14F1 : 7|64@0+ (1,0) [0|0] ""  EVCU2

BO_ 2564429298 DIAGNOSTIC_REQUEST_FD_MCPB: 64 SGW
 SG_ N_PDU_18DA15F2 : 7|64@0+ (1,0) [0|0] ""  EVCU2

BO_ 2564429042 DIAGNOSTIC_REQUEST_FD_MCPA: 64 SGW
 SG_ N_PDU_18DA14F2 : 7|64@0+ (1,0) [0|0] ""  EVCU2

BO_ 244 BATTERY_HV: 64 BPCM
 SG_ BMS_HV_InternalVoltage : 278|13@0+ (0.1,90.9) [90.9|910] "V"  SGW
 SG_ BMS_HV_Current : 213|15@0+ (0.1,-1638.4) [-1638.4|1638.2] "A"  SGW
 SG_ BMS_HV_Battery_GFD_Sts : 251|3@0+ (1,0) [0|7] ""  SGW
 SG_ BMS_HV_Temperature_Min : 157|11@0+ (0.1,-40) [-40|164.7] "°C"  SGW
 SG_ BMS_HV_Temperature_Max : 136|11@0+ (0.1,-40) [-40|164.7] "°C"  SGW
 SG_ ImpactHardwireV : 500|1@0+ (1,0) [0|1] ""  EVCU2
 SG_ ImpactHardwire : 501|1@0+ (1,0) [0|1] ""  EVCU2

BO_TX_BU_ 478 : EVCU2,HCP;
CM_ SG_ 1579 HVBatteryVoltage_MinCal "Minimum allowable HV battery voltage";
CM_ SG_ 1579 HVBatteryVoltage_MaxCal "Maximum allowable HV battery voltage";
CM_ SG_ 1579 HVBatteryCurrent_MaxCal "Maximum allowable HV battery current";
CM_ SG_ 1579 ChargeSystemFaultReason "Charge System Fault Reason";
CM_ SG_ 1579 ACCurrent_MaxCal "Maximum allowable AC current";
CM_ SG_ 1579 ChargingLevel "Charging level and type.";
CM_ SG_ 1579 OBCM_PLUG_STS "Plug Status retrieved by the VDCM according to the proximity Sts and pilot Sts and current input available sent by the OBCM";
CM_ SG_ 1579 VDCM_UDCChrgr "For comm with charging station type B";
CM_ SG_ 1579 VDCM_IDCChrgr "For comm with charging station type B";
CM_ SG_ 1579 ChargeSystemSts "Charging System status";
CM_ SG_ 1579 ChargeSystemFault "Charging System Fault status";
CM_ SG_ 1579 CRC_HYBRID_CHARGING_STATUS "CRC according to SAE J1850 standard at each frame transmission.";
CM_ SG_ 1579 MessageCounter_HYBRID_CHARGING_S "This signal is a counter used for safety checks strategies. This counter is incremented of 1 (one) unit at each frame transmission.";
CM_ SG_ 478 LVDC_VoltageSetpoint "Low side voltage Setpoint";
CM_ SG_ 478 LVDC_SystemVoltageAct "System actual voltage";
CM_ SG_ 478 LVDC_CurrentSetpoint "Low side current Setpoint";
CM_ SG_ 478 HVInverterVoltage_Rational "??";
CM_ SG_ 478 HVDC_VoltageSetpoint "High side voltage set point";
CM_ SG_ 478 HVDC_CurrentSetpoint "High  side current Setpoint";
CM_ SG_ 478 EchargeSOCRange_ePT "Target SOC for ECharge";
CM_ SG_ 478 CRC_HYBRID_CHARGING_COMMAND "CRC according to SAE J1850 standard at each frame transmission.";
CM_ SG_ 478 VoltageRequest "High Voltage Battery Voltage";
CM_ SG_ 478 OBC_ModeRequest "Onboard charger mode request";
CM_ SG_ 478 OBC_ControlMethod "Onboard charger commanded control method";
CM_ SG_ 478 MainHV_ContactorCommand "High voltage battery contactor command";
CM_ SG_ 478 J1772_CloseS2 "J 1772 Close command";
CM_ SG_ 478 HVInverterVoltage_RationalV ".";
CM_ SG_ 478 HVBatCoolantLevelLow "Battery coolant level low";
CM_ SG_ 478 DCDC_OperationModeEnable "APM Operation Mode  Enable";
CM_ SG_ 478 ClearLegislatedDiagInfo "Clear Legislated Diagnostic Information";
CM_ SG_ 478 OBC_OperativeModeReq "This signal indicates the Onboard charger mode request";
CM_ SG_ 478 HV_Volt_Min_Thrsh "This signal indicates the Commanded minimum Traction Battery Voltage to On Board Charger.";
CM_ SG_ 478 HV_Volt_Max_Thrsh "This signal indicates the Commanded maximum Traction Battery Voltage to On Board Charger.";
CM_ SG_ 478 DC_Curr_Max_Thrsh "Maximum Threshold for charging DC current.";
CM_ SG_ 478 ChargeEnable "Charge Enable";
CM_ SG_ 478 AC_Curr_Min_Thrsh "Commanded AC current min threshold to On Board Charge";
CM_ SG_ 478 AC_Curr_Max_Thrsh "Commanded AC current max threshold to On Board Charge";
CM_ SG_ 478 CurrentRequest "HCP current request to the on board charger";
CM_ SG_ 478 VDCM_StsWldgReq "This signal indicates the welding check request from VDCM";
CM_ SG_ 478 VDCM_SessnStopReq "This signal indicates the session stop request from VDCM";
CM_ SG_ 478 VDCM_StsSWWldgReq "Software welding check request from VDCM";
CM_ SG_ 478 MessageCounter_HYBRID_CHARGING_C "This signal is a counter used for safety checks strategies. This counter is incremented of 1 (one) unit at each frame transmission.";
CM_ SG_ 478 MaxCurrentAllwd "Charge Enable";
CM_ SG_ 1578 OBC_IdleTimeSec "On board charger idle time";
CM_ SG_ 1578 OBC_IdleTimeMin "On board charger idle time - long";
CM_ SG_ 1578 OBC_ChargeTimeSec "On board charge time";
CM_ SG_ 1578 OBC_ChargeTimeMin "On board charge time - long";
CM_ SG_ 1578 Charging_WHr "Watt-hours of charge";
CM_ SG_ 1578 OnboardChargerReady "OBCM Ready status";
CM_ SG_ 1578 OnboardChargerMode "OBCM operative mode";
CM_ SG_ 1578 OBC_WakeReason "OBCM wakeup status";
CM_ SG_ 1578 OBC_GenericFailSts ".";
CM_ SG_ 1578 OBC_FaultReason "OBCM Fault Reason";
CM_ SG_ 1578 OBC_EVServiceLampOn "Ev service On request from OBCM";
CM_ SG_ 1578 OBC_EVServiceLampFlash "Ev service LIGHT flash from OBCM";
CM_ SG_ 1578 OBC_CurrentFailureSts ".";
CM_ SG_ 1578 OBC_ChargingFaultSts "OBCM charging fault status";
CM_ SG_ 1578 OBC_ChargeFailure "0 = Open, 1 = Off/SNA";
CM_ SG_ 1578 OBC_CaptureEnvironmentData "Capture Environmental Data";
CM_ SG_ 1578 ACplug_PwrMax "Maximum  AC power limit";
CM_ SG_ 1578 OBCM_PrechargeSts "OBCM precharge status feedback";
CM_ SG_ 1578 ChrgFailSts "TxMessageResponse from EVSE.";
CM_ SG_ 1372 OBC_Temp4 "OBCM temperature sensor 3";
CM_ SG_ 1372 OBC_Temp3 "OBCM temperature sensor 4";
CM_ SG_ 1372 OBC_Temp2 "OBCM temperature sensor 2";
CM_ SG_ 1372 OBC_Temp1 "OBCM temperature sensor 1";
CM_ SG_ 2564682064 N_PDU_18DDF150 "This signal is used for diagnostic purposes";
CM_ SG_ 2564682059 N_PDU_18DDF14B "This signal is used for diagnostic purposes";
CM_ SG_ 2564682320 N_PDU_18DDF250 "This signal is used for diagnostic purposes";
CM_ SG_ 2564682315 N_PDU_18DDF24B "This signal is used for diagnostic purposes";
CM_ SG_ 2564682308 N_PDU_18DDF244 "This signal is used for diagnostic purposes";
CM_ SG_ 2564682052 N_PDU_18DDF144 "This signal is used for diagnostic purposes";
CM_ SG_ 2564485712 N_PDU_18DAF250 "This signal is used for diagnostic purposes";
CM_ SG_ 2564485707 N_PDU_18DAF24B "This signal is used for diagnostic purposes";
CM_ SG_ 2564485700 N_PDU_18DAF244 "This signal is used for diagnostic purposes";
CM_ SG_ 2564444402 N_PDU_18DA50F2 "This signal is used for diagnostic purposes";
CM_ SG_ 2564443122 N_PDU_18DA4BF2 "This signal is used for diagnostic purposes";
CM_ SG_ 2564441330 N_PDU_18DA44F2 "This signal is used for diagnostic purposes";
CM_ SG_ 2654339170 GenericFailSts_FD03_HCP "Indicates the presence/absent of at least one DTC in the System Memory";
CM_ SG_ 2654339170 EOL_FD03_HCP "Indicates if the ECU requires configuration data at the assembly plant End Of Line";
CM_ SG_ 2654339170 CurrentFailSts_FD03_HCP "Indicates the presence/absence of at least one DTC with DTCStatus = present in the System Memory";
CM_ SG_ 2654339170 WakeupSource_FD03_HCP "Indicates the reason the ECU was most recently awakened";
CM_ SG_ 2654339170 PreviousCanNMState_FD03_HCP "Indicates the last CanNM state that the ECU existed in";
CM_ SG_ 2654339170 DES_FD03_HCP "Indicates whether the ECU?s CAN cell is in either ErrorActive, or ErrorPassive state OR has just now recovered from a BusOff condition";
CM_ SG_ 2654339170 CurrentCanNMState_FD03_HCP "Indicates that CanNM state the ECU is currently executing";
CM_ SG_ 2654339170 StayActiveSource_FD03_HCP "Indicates the source that requests the ECU to stay active";
CM_ SG_ 1845 HVBatSerialLength "Length of the High Voltage Battery pack's serial number (number of ASCII characters)";
CM_ SG_ 1845 HVBatSerialNumber "High Voltage Battery pack serial number, ASCII 8-bit encoded.";
CM_ SG_ 1460 FOTA_Status "FOTA_Status";
CM_ SG_ 1374 HVBatPackVoltage_MaxAllowedV "Maximum pack voltage allowed valid; Invalid = [1]";
CM_ SG_ 1374 HVBatCellVoltage_MinAllowedV "Minimum cell voltage allowed valid; Invalid = [1]";
CM_ SG_ 1374 HVBatCellVoltage_MinAllowed "Minimum cell voltage allowed";
CM_ SG_ 1374 HVBatCellVoltage_MaxAllowedV "Maximum cell voltage allowed valid; Invalid = [1]";
CM_ SG_ 1374 HVBatCellVoltage_MaxAllowed "Maximum cell voltage allowed";
CM_ SG_ 1374 HVBatCellVoltage_LowThreshold "Cell voltage low threshold";
CM_ SG_ 1374 HVBatCellVoltage_HighThreshold "Cell voltage high threshold";
CM_ SG_ 1374 HVBatCapacity_AmpHrV "Total HV battery amp hour capacity validity; Invalid = [1]";
CM_ SG_ 1374 HVBatCapacity_AmpHr "Total HV Battery Amp Hour Capacity";
CM_ SG_ 1374 HVBatRemainingAhCapacity "High voltage battery pack remaining amp hour capacity.";
CM_ SG_ 1374 HVBatDischargeAmpHrs "High voltage battery pack Amp Hours of discharge.";
CM_ SG_ 1374 HVBatChargeAmpHrs "High voltage battery pack Amp Hours of charge.";
CM_ SG_ 1374 BSGPackVoltage_MaxAllowed "Maximum pack voltage allowed";
CM_ SG_ 1038 Precharge_Closed "Precharge contactor is closed.";
CM_ SG_ 1038 Positive_Main_Closed "Positive main contactor is closed.";
CM_ SG_ 1038 Negative_Main_Closed "Negative main contactor is closed.";
CM_ SG_ 1038 HBCO_TempSensorRationality "Temperature sensor rationality.";
CM_ SG_ 1038 HBCO_Sensor_Fault "Sensor failure detected.";
CM_ SG_ 1038 HBCO_PackUndertemp "Battery undertemperature.";
CM_ SG_ 1038 HBCO_PackOvertemp "Battery overtemperature.";
CM_ SG_ 1038 HBCO_OverCurrent "Overcurrent condition detected.";
CM_ SG_ 1038 HBCO_Micro_Failure "Internal micro failures detected.";
CM_ SG_ 1038 HBCO_Main_Fuse_Failure "Main fuse (SD) is blown.";
CM_ SG_ 1038 HBCO_Isolation_Fault "Loss of isolation detected.";
CM_ SG_ 1038 HBCO_Internal_CommFault "Loss of Comm on the BPCM internal CAN bus.";
CM_ SG_ 1038 HBCO_Impact_Detected "Crash detection.";
CM_ SG_ 1038 HBCO_HVIL_Failure "HVIL Failure.";
CM_ SG_ 1038 HBCO_External_CommFault "Loss of Comm on the vehicle CAN bus.";
CM_ SG_ 1038 HBCO_CellUndervoltage "Cell voltage too low.";
CM_ SG_ 1038 HBCO_CellOvervoltage "Cell voltage too high.";
CM_ SG_ 1038 HBCO_12V_Low "12V too low.";
CM_ SG_ 1038 HBCO_12V_High "12V too high.";
CM_ SG_ 1038 HBCNC_TempSensorRationality "Temperature sensor rationality.";
CM_ SG_ 1038 HBCNC_SOH_Failure "State of Health failure.";
CM_ SG_ 1038 HBCNC_Sensor_Failure "Sensor failure detected.";
CM_ SG_ 1038 HBCNC_Precharge_Failure "Precharge failed.";
CM_ SG_ 1038 HBCNC_PackUndervoltage "Pack voltage too low.";
CM_ SG_ 1038 HBCNC_PackUndertemp "Battery undertemperature.";
CM_ SG_ 1038 HBCNC_PackOvervoltage "Pack voltage too high.";
CM_ SG_ 1038 HBCNC_PackOvertemp "Battery overtemperature.";
CM_ SG_ 1038 HBCNC_Micro_Failure "Internal micro failures detected.";
CM_ SG_ 1038 HBCNC_Main_Fuse_Failure "Main fuse (SD) is blown.";
CM_ SG_ 1038 HBCNC_Isolation_Fault "Loss of isolation detected.";
CM_ SG_ 1038 HBCNC_Internal_CommFault "Loss of Comm on the BPCM internal CAN bus.";
CM_ SG_ 1038 HBCNC_Impact_Detected "Crash detection.";
CM_ SG_ 1038 HBCNC_External_CommFault "Loss of Comm on the vehicle CAN bus.";
CM_ SG_ 1038 HBCNC_EEPROM_Fault "EEPROM fault or invalid signals detected.";
CM_ SG_ 1038 HBCNC_Contactors_Welded "Contactors welded.";
CM_ SG_ 1038 HBCNC_CellUndervoltage "Cell voltage too low.";
CM_ SG_ 1038 HBCNC_CellOvervoltage "Cell voltage too high.";
CM_ SG_ 1038 HBCNC_12V_Low "12V too low.";
CM_ SG_ 1038 HBCNC_12V_High "12V too high.";
CM_ SG_ 1038 BPCM_DTC_Status6 "Diagnostic Trouble Code status 6";
CM_ SG_ 1038 BPCM_DTC_Status5 "Diagnostic Trouble Code status 5";
CM_ SG_ 1038 BPCM_DTC_Status4 "Diagnostic Trouble Code status 4";
CM_ SG_ 1038 BPCM_DTC_Status3 "Diagnostic Trouble Code status 3";
CM_ SG_ 1038 BPCM_DTC_Status2 "Diagnostic Trouble Code status 2";
CM_ SG_ 1038 BPCM_DTC_Status1 "Diagnostic Trouble Code status 1";
CM_ SG_ 1038 BPCM_DTC_Index6 "Battery Pack DTC Index 6";
CM_ SG_ 1038 BPCM_DTC_Index5 "Battery Pack DTC Index 5";
CM_ SG_ 1038 BPCM_DTC_Index4 "Battery Pack DTC Index 4";
CM_ SG_ 1038 BPCM_DTC_Index3 "Battery Pack DTC Index 3";
CM_ SG_ 1038 BPCM_DTC_Index2 "Battery Pack DTC Index 2";
CM_ SG_ 1038 BPCM_DTC_Index1 "Battery Pack DTC Index 1";
CM_ SG_ 1038 BPCM_CalibrationVN "Battery Pack calibration verification number.";
CM_ SG_ 1038 BPCM_CalibrationID "Battery Pack calibration ID index.";
CM_ SG_ 1038 BPCM_Odometer "Battery Pack odometer (kilometers driven).";
CM_ SG_ 1852 HVBatCellVoltage_Cell192 "High voltage battery cell voltage for Cell 192";
CM_ SG_ 1852 HVBatCellVoltage_Cell191 "High voltage battery cell voltage for Cell 191";
CM_ SG_ 1852 HVBatCellVoltage_Cell190 "High voltage battery cell voltage for Cell 190";
CM_ SG_ 1852 HVBatCellVoltage_Cell216 "High voltage battery cell voltage for Cell 216";
CM_ SG_ 1852 HVBatCellVoltage_Cell215 "High voltage battery cell voltage for Cell 215";
CM_ SG_ 1852 HVBatCellVoltage_Cell214 "High voltage battery cell voltage for Cell 214";
CM_ SG_ 1852 HVBatCellVoltage_Cell213 "High voltage battery cell voltage for Cell 213";
CM_ SG_ 1852 HVBatCellVoltage_Cell212 "High voltage battery cell voltage for Cell 212";
CM_ SG_ 1852 HVBatCellVoltage_Cell211 "High voltage battery cell voltage for Cell 211";
CM_ SG_ 1852 HVBatCellVoltage_Cell210 "High voltage battery cell voltage for Cell 210";
CM_ SG_ 1852 HVBatCellVoltage_Cell209 "High voltage battery cell voltage for Cell 209";
CM_ SG_ 1852 HVBatCellVoltage_Cell208 "High voltage battery cell voltage for Cell 208";
CM_ SG_ 1852 HVBatCellVoltage_Cell207 "High voltage battery cell voltage for Cell 207";
CM_ SG_ 1852 HVBatCellVoltage_Cell206 "High voltage battery cell voltage for Cell 206";
CM_ SG_ 1852 HVBatCellVoltage_Cell205 "High voltage battery cell voltage for Cell 205";
CM_ SG_ 1852 HVBatCellVoltage_Cell204 "High voltage battery cell voltage for Cell 204";
CM_ SG_ 1852 HVBatCellVoltage_Cell203 "High voltage battery cell voltage for Cell 203";
CM_ SG_ 1852 HVBatCellVoltage_Cell202 "High voltage battery cell voltage for Cell 202";
CM_ SG_ 1852 HVBatCellVoltage_Cell201 "High voltage battery cell voltage for Cell 201";
CM_ SG_ 1852 HVBatCellVoltage_Cell200 "High voltage battery cell voltage for Cell 200";
CM_ SG_ 1852 HVBatCellVoltage_Cell198 "High voltage battery cell voltage for Cell 198";
CM_ SG_ 1852 HVBatCellVoltage_Cell197 "High voltage battery cell voltage for Cell 197";
CM_ SG_ 1852 HVBatCellVoltage_Cell196 "High voltage battery cell voltage for Cell 196";
CM_ SG_ 1852 HVBatCellVoltage_Cell195 "High voltage battery cell voltage for Cell 195";
CM_ SG_ 1852 HVBatCellVoltage_Cell194 "High voltage battery cell voltage for Cell 194";
CM_ SG_ 1852 HVBatCellVoltage_Cell193 "High voltage battery cell voltage for Cell 193";
CM_ SG_ 1851 HVBatCellVoltage_Cell189 "High voltage battery cell voltage for Cell 189";
CM_ SG_ 1851 HVBatCellVoltage_Cell188 "High voltage battery cell voltage for Cell 188";
CM_ SG_ 1851 HVBatCellVoltage_Cell187 "High voltage battery cell voltage for Cell 187";
CM_ SG_ 1851 HVBatCellVoltage_Cell186 "High voltage battery cell voltage for Cell 186";
CM_ SG_ 1851 HVBatCellVoltage_Cell185 "High voltage battery cell voltage for Cell 185";
CM_ SG_ 1851 HVBatCellVoltage_Cell184 "High voltage battery cell voltage for Cell 184";
CM_ SG_ 1851 HVBatCellVoltage_Cell183 "High voltage battery cell voltage for Cell 183";
CM_ SG_ 1851 HVBatCellVoltage_Cell182 "High voltage battery cell voltage for Cell 182";
CM_ SG_ 1851 HVBatCellVoltage_Cell181 "High voltage battery cell voltage for Cell 181";
CM_ SG_ 1851 HVBatCellVoltage_Cell180 "High voltage battery cell voltage for Cell 180";
CM_ SG_ 1851 HVBatCellVoltage_Cell179 "High voltage battery cell voltage for Cell 179";
CM_ SG_ 1851 HVBatCellVoltage_Cell178 "High voltage battery cell voltage for Cell 178";
CM_ SG_ 1851 HVBatCellVoltage_Cell177 "High voltage battery cell voltage for Cell 177";
CM_ SG_ 1851 HVBatCellVoltage_Cell176 "High voltage battery cell voltage for Cell 176";
CM_ SG_ 1851 HVBatCellVoltage_Cell175 "High voltage battery cell voltage for Cell 175";
CM_ SG_ 1851 HVBatCellVoltage_Cell174 "High voltage battery cell voltage for Cell 174";
CM_ SG_ 1851 HVBatCellVoltage_Cell173 "High voltage battery cell voltage for Cell 173";
CM_ SG_ 1851 HVBatCellVoltage_Cell172 "High voltage battery cell voltage for Cell 172";
CM_ SG_ 1851 HVBatCellVoltage_Cell171 "High voltage battery cell voltage for Cell 171";
CM_ SG_ 1851 HVBatCellVoltage_Cell170 "High voltage battery cell voltage for Cell 170";
CM_ SG_ 1851 HVBatCellVoltage_Cell169 "High voltage battery cell voltage for Cell 169";
CM_ SG_ 1851 HVBatCellVoltage_Cell168 "High voltage battery cell voltage for Cell 168";
CM_ SG_ 1851 HVBatCellVoltage_Cell167 "High voltage battery cell voltage for Cell 167";
CM_ SG_ 1851 HVBatCellVoltage_Cell166 "High voltage battery cell voltage for Cell 166";
CM_ SG_ 1851 HVBatCellVoltage_Cell165 "High voltage battery cell voltage for Cell 165";
CM_ SG_ 1851 HVBatCellVoltage_Cell164 "High voltage battery cell voltage for Cell 164";
CM_ SG_ 1851 HVBatCellVoltage_Cell163 "High voltage battery cell voltage for Cell 163";
CM_ SG_ 1850 HVBatCellVoltage_Cell162 "High voltage battery cell voltage for Cell 162";
CM_ SG_ 1850 HVBatCellVoltage_Cell161 "High voltage battery cell voltage for Cell 161";
CM_ SG_ 1850 HVBatCellVoltage_Cell160 "High voltage battery cell voltage for Cell 160";
CM_ SG_ 1850 HVBatCellVoltage_Cell159 "High voltage battery cell voltage for Cell 159";
CM_ SG_ 1850 HVBatCellVoltage_Cell158 "High voltage battery cell voltage for Cell 158";
CM_ SG_ 1850 HVBatCellVoltage_Cell157 "High voltage battery cell voltage for Cell 157";
CM_ SG_ 1850 HVBatCellVoltage_Cell156 "High voltage battery cell voltage for Cell 156";
CM_ SG_ 1850 HVBatCellVoltage_Cell155 "High voltage battery cell voltage for Cell 155";
CM_ SG_ 1850 HVBatCellVoltage_Cell154 "High voltage battery cell voltage for Cell 154";
CM_ SG_ 1850 HVBatCellVoltage_Cell153 "High voltage battery cell voltage for Cell 153";
CM_ SG_ 1850 HVBatCellVoltage_Cell152 "High voltage battery cell voltage for Cell 152";
CM_ SG_ 1850 HVBatCellVoltage_Cell151 "High voltage battery cell voltage for Cell 151";
CM_ SG_ 1850 HVBatCellVoltage_Cell150 "High voltage battery cell voltage for Cell 150";
CM_ SG_ 1850 HVBatCellVoltage_Cell149 "High voltage battery cell voltage for Cell 149";
CM_ SG_ 1850 HVBatCellVoltage_Cell148 "High voltage battery cell voltage for Cell 148";
CM_ SG_ 1850 HVBatCellVoltage_Cell147 "High voltage battery cell voltage for Cell 147";
CM_ SG_ 1850 HVBatCellVoltage_Cell146 "High voltage battery cell voltage for Cell 146";
CM_ SG_ 1850 HVBatCellVoltage_Cell145 "High voltage battery cell voltage for Cell 145";
CM_ SG_ 1850 HVBatCellVoltage_Cell144 "High voltage battery cell voltage for Cell 144";
CM_ SG_ 1850 HVBatCellVoltage_Cell143 "High voltage battery cell voltage for Cell 143";
CM_ SG_ 1850 HVBatCellVoltage_Cell142 "High voltage battery cell voltage for Cell 142";
CM_ SG_ 1850 HVBatCellVoltage_Cell141 "High voltage battery cell voltage for Cell 141";
CM_ SG_ 1850 HVBatCellVoltage_Cell140 "High voltage battery cell voltage for Cell 140";
CM_ SG_ 1850 HVBatCellVoltage_Cell139 "High voltage battery cell voltage for Cell 139";
CM_ SG_ 1850 HVBatCellVoltage_Cell138 "High voltage battery cell voltage for Cell 138";
CM_ SG_ 1850 HVBatCellVoltage_Cell137 "High voltage battery cell voltage for Cell 137";
CM_ SG_ 1850 HVBatCellVoltage_Cell136 "High voltage battery cell voltage for Cell 136";
CM_ SG_ 1849 HVBatCellVoltage_Cell135 "High voltage battery cell voltage for Cell 135";
CM_ SG_ 1849 HVBatCellVoltage_Cell134 "High voltage battery cell voltage for Cell 134";
CM_ SG_ 1849 HVBatCellVoltage_Cell133 "High voltage battery cell voltage for Cell 133";
CM_ SG_ 1849 HVBatCellVoltage_Cell132 "High voltage battery cell voltage for Cell 132";
CM_ SG_ 1849 HVBatCellVoltage_Cell131 "High voltage battery cell voltage for Cell 131";
CM_ SG_ 1849 HVBatCellVoltage_Cell130 "High voltage battery cell voltage for Cell 130";
CM_ SG_ 1849 HVBatCellVoltage_Cell129 "High voltage battery cell voltage for Cell 129";
CM_ SG_ 1849 HVBatCellVoltage_Cell128 "High voltage battery cell voltage for Cell 128";
CM_ SG_ 1849 HVBatCellVoltage_Cell127 "High voltage battery cell voltage for Cell 127";
CM_ SG_ 1849 HVBatCellVoltage_Cell126 "High voltage battery cell voltage for Cell 126";
CM_ SG_ 1849 HVBatCellVoltage_Cell125 "High voltage battery cell voltage for Cell 125";
CM_ SG_ 1849 HVBatCellVoltage_Cell124 "High voltage battery cell voltage for Cell 124";
CM_ SG_ 1849 HVBatCellVoltage_Cell123 "High voltage battery cell voltage for Cell 123";
CM_ SG_ 1849 HVBatCellVoltage_Cell122 "High voltage battery cell voltage for Cell 122";
CM_ SG_ 1849 HVBatCellVoltage_Cell121 "High voltage battery cell voltage for Cell 121";
CM_ SG_ 1849 HVBatCellVoltage_Cell120 "High voltage battery cell voltage for Cell 120";
CM_ SG_ 1849 HVBatCellVoltage_Cell119 "High voltage battery cell voltage for Cell 119";
CM_ SG_ 1849 HVBatCellVoltage_Cell118 "High voltage battery cell voltage for Cell 118";
CM_ SG_ 1849 HVBatCellVoltage_Cell117 "High voltage battery cell voltage for Cell 117";
CM_ SG_ 1849 HVBatCellVoltage_Cell116 "High voltage battery cell voltage for Cell 116";
CM_ SG_ 1849 HVBatCellVoltage_Cell115 "High voltage battery cell voltage for Cell 115";
CM_ SG_ 1849 HVBatCellVoltage_Cell114 "High voltage battery cell voltage for Cell 114";
CM_ SG_ 1849 HVBatCellVoltage_Cell113 "High voltage battery cell voltage for Cell 113";
CM_ SG_ 1849 HVBatCellVoltage_Cell112 "High voltage battery cell voltage for Cell 112";
CM_ SG_ 1849 HVBatCellVoltage_Cell111 "High voltage battery cell voltage for Cell 111";
CM_ SG_ 1849 HVBatCellVoltage_Cell110 "High voltage battery cell voltage for Cell 110";
CM_ SG_ 1849 HVBatCellVoltage_Cell109 "High voltage battery cell voltage for Cell 109";
CM_ SG_ 502 VDCM_OBCDischCurrentLim "This signal indicates the Limit of discharge current.";
CM_ SG_ 502 VDCM_BattBulkSOC "This signal indicates the SOC at which the battery is considered as full.";
CM_ SG_ 502 HVCMS_ServiceScope "This signal indicates the HVCMS Service Scope.";
CM_ SG_ 502 HVCMS_ReadyToChargeState "This signal indicates the HVCMS_ReadyToChargeState.";
CM_ SG_ 502 HVCMS_Protocol_Entry3 "HVCMS Protocol";
CM_ SG_ 502 HVCMS_Protocol_Entry2 "HVCMS Protocol";
CM_ SG_ 502 HVCMS_Protocol_Entry1 "HVCMS Protocol";
CM_ SG_ 502 HVCMS_EVTargetVoltage "This signal indicates the HVCMS EV Target Voltage.";
CM_ SG_ 502 HVCMS_EVTargetCurrent "This signal indicates the HVCMS_EVTargetCurrent.";
CM_ SG_ 502 HVCMS_EVRESSConditioning "This signal indicates the HVCMS EV RESS Conditioning.";
CM_ SG_ 502 HVCMS_EVRESS_SOC "This signal indicates the HVCMS EV RESS State Of Charge.";
CM_ SG_ 502 HVCMS_EVReady "This signal indicates the HVCMS EV Ready.";
CM_ SG_ 502 HVCMS_EVMax_V_Limit "This signal indicates the HVCMS EV Max Voltage Limit.";
CM_ SG_ 502 HVCMS_EVMax_P_Limit "This signal indicates the HVCMS EV Max Power Limit.";
CM_ SG_ 502 HVCMS_EVMax_I_Limit "This signal indicates the HVCMS EV Max Current Limit.";
CM_ SG_ 502 HVCMS_EVEnergyCapacity "This signal indicates the HVCMS EV Energy Capacity.";
CM_ SG_ 502 HVCMS_ChargingComplete "This signal indicates the HVCMS Charging Complete.";
CM_ SG_ 502 HVCMS_BulkChargingComplete "This signal indicates the HVCMS Bulk Charging Complete.";
CM_ SG_ 502 VDCM_TypeCNegotiationSts "This signal indicates the Status of Negotiation in case of Type C EVSE";
CM_ SG_ 502 VDCM_GenChallenge "This signal indicates the Contract Authentication request gen challenge.";
CM_ SG_ 502 VDCM_ContractAuthenticationID "This signal indicates the Contract Authentication ID.";
CM_ SG_ 502 HVCMS_EVEnergyRequest "This signal indicates the HVCMS EV Energy Request.";
CM_ SG_ 502 OBCM_OutVoltageSyncTgt "This signal indicates the OBCM Precharge Voltage Level";
CM_ SG_ 502 HVCMS_ServiceCategory "This signal indicates the HVCMS Service Category.";
CM_ SG_ 502 HVCMS_SelectedServiceId "This signal indicates the HVCMS Selected Service Identifier.";
CM_ SG_ 502 HVCMS_SelectedPaymentOptn "This signal indicates the HVCMS Selected Payment Option.";
CM_ SG_ 502 HVCMS_SelectedEnergyTransferType "This signal indicates the HVCMS Selected Energy Transfer Type.";
CM_ SG_ 502 HVCMS_RemaningTimeToFullSOC "This signal indicates the HVCM Remaning Time To Full SOC.";
CM_ SG_ 502 HVCMS_RemaningTimeToBulkSOC "This signal indicates the HVCM Remaning Time To Bulk SOC.";
CM_ SG_ 502 HVCMS_EVErrorCode "This signal indicates the HVCMS EV Error Code.";
CM_ SG_ 242 MC_PF1 "Message counter according to SAE J1850 standard that has to be calculated from bit 63 to bit 8 at each frame transmission.";
CM_ SG_ 242 CRC_PF1 "CRC according to SAE J1850 standard that has to be calculated from bit 63 to bit 8 at each frame transmission.";
CM_ SG_ 242 MCPA_DC_Current "Motor A DC Current";
CM_ SG_ 498 HVCMS_EVSEPeakCurrentRipple "Peak-to-peak magnitude of the current ripple of the EVSE.";
CM_ SG_ 498 HVCMS_EVSEMaxPowerLimit "Maximum power the EVSE can deliver.";
CM_ SG_ 498 HVCMS_EVSECurrRegulationTol "Absolute magnitude of the regulation tolerance of the EVSE.";
CM_ SG_ 498 HVCMS_EnergyToBeDelivered "Amount of energy to be delivered by the EVSE.";
CM_ SG_ 498 DC_TimeOut "DC Charging session time out";
CM_ SG_ 498 DC_Isolation_Disable_Cmd "Isolation Disabling command for DC charging";
CM_ SG_ 498 OBCM_PLCTypeSts "Power Line communication";
CM_ SG_ 498 HVCMS_EVSEMinimumVoltageLimit "For communication with charging station type A,B,C";
CM_ SG_ 498 HVCMS_EVSEMaximumVoltageLimit "For communication with charging station type A,B,C";
CM_ SG_ 498 HVCMS_TxMessageStat "Response code from the Charging Station";
CM_ SG_ 498 HVCMS_ResponseCode "Response code from the Charging Station";
CM_ SG_ 498 TxMessageResponse "This signal indicates the HVCMS Service Category.";
CM_ SG_ 498 EVSE_ServiceId "EVSE Service ID";
CM_ SG_ 498 EVSE_OfferedPaymentOptn "List of payment options offered.";
CM_ SG_ 498 EVSE_Supported_ISO1 "Used to report if ISO15118_2 protocol is offered or not.";
CM_ SG_ 498 EVSE_Supported_DIN "Used to report if DIN protocol is offered or not.";
CM_ SG_ 498 EVSE_Supported_SAE "Used to report if SAE protocol is offered or not.";
CM_ SG_ 498 EVSE_Service2_Certificate "Used to report the availability of Contract Certificate services.";
CM_ SG_ 498 EVSE_OfferedPaymentEIM "Used to report if EIM is offered as a method of paymet by EVSE.";
CM_ SG_ 498 EVSE_OfferedPaymentContract "Used to report if Contract is offered as a method of paymet by EVSE.";
CM_ SG_ 498 EVSE_Notification "This signal contains an action that the SECC wants the EVCC to perform.";
CM_ SG_ 2564682261 N_PDU_18DDF215 "This signal is used for diagnostic purposes";
CM_ SG_ 2564682260 N_PDU_18DDF214 "This signal is used for diagnostic purposes";
CM_ SG_ 2564485396 N_PDU_18DAF114 "This signal is used for diagnostic purposes";
CM_ SG_ 2564485653 N_PDU_18DAF215 "This signal is used for diagnostic purposes";
CM_ SG_ 2564485652 N_PDU_18DAF214 "This signal is used for diagnostic purposes";
CM_ SG_ 2564429297 N_PDU_18DA15F1 "This signal is used for diagnostic purposes";
CM_ SG_ 2564429041 N_PDU_18DA14F1 "This signal is used for diagnostic purposes";
CM_ SG_ 2564429298 N_PDU_18DA15F2 "This signal is used for diagnostic purposes";
CM_ SG_ 2564429042 N_PDU_18DA14F2 "This signal is used for diagnostic purposes";
CM_ SG_ 244 BMS_HV_InternalVoltage "Battery internal voltage";
CM_ SG_ 244 BMS_HV_Current "Battery Current";
CM_ SG_ 244 BMS_HV_Battery_GFD_Sts "HV Battery ground fault detection(Isolation)";
CM_ SG_ 244 BMS_HV_Temperature_Min "Battery Minimum Temperature";
CM_ SG_ 244 BMS_HV_Temperature_Max "Battery Maximum Temperature";
CM_ SG_ 244 ImpactHardwireV "This signal is used to indicate a Valid serial line comunication";
CM_ SG_ 244 ImpactHardwire "This signal is used to indicate that a crash happened";
BA_DEF_ SG_  "GenSigTimeoutTime_HCP" INT 0 65535;
BA_DEF_ SG_  "GenSigTimeoutTime_PPIM" INT 0 65535;
BA_DEF_ SG_  "GenSigStartValue" INT 0 2147483647;
BA_DEF_ SG_  "GenSigInactiveValue" INT 0 2147483647;
BA_DEF_ SG_  "GenSigSendType" ENUM  "NotUsed","OnWrite","OnWriteWithRepetition","OnChange","OnChangeWithRepetition","IfActive","IfActiveWithRepetition","NoSigSendType";
BA_DEF_ SG_  "GenSigTimeoutTime_BPCM" INT 0 65535;
BA_DEF_ SG_  "GenSigTimeoutTime_EVCU2" INT 0 65535;
BA_DEF_ SG_  "GenSigTimeoutTime_IDCM" INT 0 65535;
BA_DEF_ SG_  "GenSigTimeoutTime_SGW" INT 0 65535;
BA_DEF_ BO_  "DiagRequest" ENUM  "No","Yes";
BA_DEF_ BO_  "Type" ENUM  "P","C","PE","COC","PE_Cntrl","E","E_Cntrl","OC","S","BAF","DC","EM","MM","ISO-TP","-";
BA_DEF_ BO_  "DiagResponse" ENUM  "No","Yes";
BA_DEF_ BO_  "NmMessage" ENUM  "No","Yes";
BA_DEF_ BO_  "GenMsgSendType" ENUM  "Cyclic","NotUsed","NotUsed","NotUsed","NotUsed","NotUsed","NotUsed","NotUsed","NoMsgSendType";
BA_DEF_ BO_  "GenMsgNrOfRepetition" INT 0 255;
BA_DEF_ BO_  "GenMsgILSupport" ENUM  "No","Yes";
BA_DEF_ BO_  "GenMsgStartDelayTime" INT 0 65535;
BA_DEF_ BO_  "GenMsgCycleTimeFast" INT 0 65535;
BA_DEF_ BO_  "GenMsgCycleTime" INT 0 65535;
BA_DEF_ BO_  "GenMsgDelayTime" INT 0 65535;
BA_DEF_ BO_  "NmAsrMessage" ENUM  "No","Yes";
BA_DEF_ BO_  "DiagState" ENUM  "No","Yes";
BA_DEF_ BO_  "DiagConnection" HEX 0 65535;
BA_DEF_ BO_  "CanTpFcFrameId" HEX 0 2147483647;
BA_DEF_ BO_  "VFrameFormat" ENUM  "StandardCAN","ExtendedCAN","reserved","reserved","reserved","reserved","reserved","reserved","reserved","reserved","reserved","reserved","reserved","reserved","StandardCAN_FD","ExtendedCAN_FD";
BA_DEF_ BO_  "CANFD_BRS" ENUM  "0","1";
BA_DEF_ SG_  "SystemSignalLongSymbol" STRING ;
BA_DEF_DEF_  "GenSigTimeoutTime_HCP" 2500;
BA_DEF_DEF_  "GenSigTimeoutTime_PPIM" 2500;
BA_DEF_DEF_  "GenSigStartValue" 0;
BA_DEF_DEF_  "GenSigInactiveValue" 0;
BA_DEF_DEF_  "GenSigSendType" "NoSigSendType";
BA_DEF_DEF_  "GenSigTimeoutTime_BPCM" 2500;
BA_DEF_DEF_  "GenSigTimeoutTime_EVCU2" 2500;
BA_DEF_DEF_  "GenSigTimeoutTime_IDCM" 2500;
BA_DEF_DEF_  "GenSigTimeoutTime_SGW" 2500;
BA_DEF_DEF_  "DiagRequest" "No";
BA_DEF_DEF_  "Type" "-";
BA_DEF_DEF_  "DiagResponse" "No";
BA_DEF_DEF_  "NmMessage" "No";
BA_DEF_DEF_  "GenMsgSendType" "NoMsgSendType";
BA_DEF_DEF_  "GenMsgNrOfRepetition" 0;
BA_DEF_DEF_  "GenMsgILSupport" "No";
BA_DEF_DEF_  "GenMsgStartDelayTime" 0;
BA_DEF_DEF_  "GenMsgCycleTimeFast" 0;
BA_DEF_DEF_  "GenMsgCycleTime" 0;
BA_DEF_DEF_  "GenMsgDelayTime" 0;
BA_DEF_DEF_  "NmAsrMessage" "No";
BA_DEF_DEF_  "DiagState" "No";
BA_DEF_DEF_  "DiagConnection" 0;
BA_DEF_DEF_  "CanTpFcFrameId" 2147483647;
BA_DEF_DEF_  "VFrameFormat" "StandardCAN_FD";
BA_DEF_DEF_  "CANFD_BRS" "0";
BA_DEF_DEF_  "SystemSignalLongSymbol" "";
BA_ "CANFD_BRS" BO_ 1579 1;
BA_ "GenMsgCycleTime" BO_ 1579 500;
BA_ "GenMsgILSupport" BO_ 1579 1;
BA_ "GenMsgSendType" BO_ 1579 0;
BA_ "Type" BO_ 1579 1;
BA_ "CANFD_BRS" BO_ 478 1;
BA_ "GenMsgCycleTime" BO_ 478 20;
BA_ "GenMsgILSupport" BO_ 478 1;
BA_ "GenMsgSendType" BO_ 478 0;
BA_ "Type" BO_ 478 1;
BA_ "CANFD_BRS" BO_ 1578 1;
BA_ "GenMsgCycleTime" BO_ 1578 500;
BA_ "GenMsgCycleTimeFast" BO_ 1578 10;
BA_ "GenMsgILSupport" BO_ 1578 1;
BA_ "GenMsgNrOfRepetition" BO_ 1578 3;
BA_ "GenMsgSendType" BO_ 1578 0;
BA_ "Type" BO_ 1578 3;
BA_ "CANFD_BRS" BO_ 1372 1;
BA_ "GenMsgCycleTime" BO_ 1372 250;
BA_ "GenMsgILSupport" BO_ 1372 1;
BA_ "GenMsgSendType" BO_ 1372 0;
BA_ "Type" BO_ 1372 1;
BA_ "VFrameFormat" BO_ 2564682064 1;
BA_ "DiagConnection" BO_ 2564682064 61776;
BA_ "DiagResponse" BO_ 2564682064 1;
BA_ "Type" BO_ 2564682064 8;
BA_ "VFrameFormat" BO_ 2564682059 1;
BA_ "DiagConnection" BO_ 2564682059 61771;
BA_ "DiagResponse" BO_ 2564682059 1;
BA_ "Type" BO_ 2564682059 8;
BA_ "CANFD_BRS" BO_ 2564682320 1;
BA_ "DiagConnection" BO_ 2564682320 62032;
BA_ "DiagResponse" BO_ 2564682320 1;
BA_ "Type" BO_ 2564682320 8;
BA_ "VFrameFormat" BO_ 2564682320 15;
BA_ "CANFD_BRS" BO_ 2564682315 1;
BA_ "DiagConnection" BO_ 2564682315 62027;
BA_ "DiagResponse" BO_ 2564682315 1;
BA_ "Type" BO_ 2564682315 8;
BA_ "VFrameFormat" BO_ 2564682315 15;
BA_ "CANFD_BRS" BO_ 2564682308 1;
BA_ "DiagConnection" BO_ 2564682308 62020;
BA_ "DiagResponse" BO_ 2564682308 1;
BA_ "Type" BO_ 2564682308 8;
BA_ "VFrameFormat" BO_ 2564682308 15;
BA_ "VFrameFormat" BO_ 2564682052 1;
BA_ "DiagConnection" BO_ 2564682052 61764;
BA_ "DiagResponse" BO_ 2564682052 1;
BA_ "Type" BO_ 2564682052 8;
BA_ "CANFD_BRS" BO_ 2564485712 1;
BA_ "DiagConnection" BO_ 2564485712 62032;
BA_ "DiagResponse" BO_ 2564485712 1;
BA_ "Type" BO_ 2564485712 8;
BA_ "VFrameFormat" BO_ 2564485712 15;
BA_ "CANFD_BRS" BO_ 2564485707 1;
BA_ "DiagConnection" BO_ 2564485707 62027;
BA_ "DiagResponse" BO_ 2564485707 1;
BA_ "Type" BO_ 2564485707 8;
BA_ "VFrameFormat" BO_ 2564485707 15;
BA_ "CANFD_BRS" BO_ 2564485700 1;
BA_ "DiagConnection" BO_ 2564485700 62020;
BA_ "DiagResponse" BO_ 2564485700 1;
BA_ "Type" BO_ 2564485700 8;
BA_ "VFrameFormat" BO_ 2564485700 15;
BA_ "CANFD_BRS" BO_ 2564444402 1;
BA_ "DiagConnection" BO_ 2564444402 62032;
BA_ "Type" BO_ 2564444402 8;
BA_ "DiagRequest" BO_ 2564444402 1;
BA_ "VFrameFormat" BO_ 2564444402 15;
BA_ "CANFD_BRS" BO_ 2564443122 1;
BA_ "DiagConnection" BO_ 2564443122 62027;
BA_ "Type" BO_ 2564443122 8;
BA_ "DiagRequest" BO_ 2564443122 1;
BA_ "VFrameFormat" BO_ 2564443122 15;
BA_ "CANFD_BRS" BO_ 2564441330 1;
BA_ "DiagConnection" BO_ 2564441330 62020;
BA_ "Type" BO_ 2564441330 8;
BA_ "DiagRequest" BO_ 2564441330 1;
BA_ "VFrameFormat" BO_ 2564441330 15;
BA_ "CANFD_BRS" BO_ 2651930749 1;
BA_ "GenMsgILSupport" BO_ 2651930749 1;
BA_ "Type" BO_ 2651930749 11;
BA_ "VFrameFormat" BO_ 2651930749 15;
BA_ "CANFD_BRS" BO_ 2651930694 1;
BA_ "GenMsgILSupport" BO_ 2651930694 1;
BA_ "Type" BO_ 2651930694 11;
BA_ "VFrameFormat" BO_ 2651930694 15;
BA_ "CANFD_BRS" BO_ 2654339170 1;
BA_ "GenMsgCycleTime" BO_ 2654339170 1000;
BA_ "GenMsgILSupport" BO_ 2654339170 1;
BA_ "GenMsgSendType" BO_ 2654339170 0;
BA_ "Type" BO_ 2654339170 1;
BA_ "VFrameFormat" BO_ 2654339170 15;
BA_ "CANFD_BRS" BO_ 1845 1;
BA_ "GenMsgCycleTime" BO_ 1845 1000;
BA_ "GenMsgILSupport" BO_ 1845 1;
BA_ "GenMsgSendType" BO_ 1845 0;
BA_ "Type" BO_ 1845 1;
BA_ "CANFD_BRS" BO_ 1460 1;
BA_ "GenMsgDelayTime" BO_ 1460 20;
BA_ "GenMsgCycleTime" BO_ 1460 1000;
BA_ "GenMsgILSupport" BO_ 1460 1;
BA_ "GenMsgSendType" BO_ 1460 0;
BA_ "Type" BO_ 1460 3;
BA_ "CANFD_BRS" BO_ 1374 1;
BA_ "GenMsgCycleTime" BO_ 1374 250;
BA_ "GenMsgILSupport" BO_ 1374 1;
BA_ "GenMsgSendType" BO_ 1374 0;
BA_ "Type" BO_ 1374 1;
BA_ "CANFD_BRS" BO_ 1038 1;
BA_ "GenMsgCycleTime" BO_ 1038 100;
BA_ "GenMsgILSupport" BO_ 1038 1;
BA_ "GenMsgSendType" BO_ 1038 0;
BA_ "Type" BO_ 1038 1;
BA_ "CANFD_BRS" BO_ 1852 1;
BA_ "GenMsgCycleTime" BO_ 1852 1000;
BA_ "GenMsgILSupport" BO_ 1852 1;
BA_ "GenMsgSendType" BO_ 1852 0;
BA_ "Type" BO_ 1852 1;
BA_ "CANFD_BRS" BO_ 1851 1;
BA_ "GenMsgCycleTime" BO_ 1851 1000;
BA_ "GenMsgILSupport" BO_ 1851 1;
BA_ "GenMsgSendType" BO_ 1851 0;
BA_ "Type" BO_ 1851 1;
BA_ "CANFD_BRS" BO_ 1850 1;
BA_ "GenMsgCycleTime" BO_ 1850 1000;
BA_ "GenMsgILSupport" BO_ 1850 1;
BA_ "GenMsgSendType" BO_ 1850 0;
BA_ "Type" BO_ 1850 1;
BA_ "CANFD_BRS" BO_ 1849 1;
BA_ "GenMsgCycleTime" BO_ 1849 1000;
BA_ "GenMsgILSupport" BO_ 1849 1;
BA_ "GenMsgSendType" BO_ 1849 0;
BA_ "Type" BO_ 1849 1;
BA_ "CANFD_BRS" BO_ 502 1;
BA_ "GenMsgCycleTime" BO_ 502 20;
BA_ "GenMsgILSupport" BO_ 502 1;
BA_ "GenMsgSendType" BO_ 502 0;
BA_ "Type" BO_ 502 1;
BA_ "CANFD_BRS" BO_ 242 1;
BA_ "GenMsgCycleTime" BO_ 242 10;
BA_ "GenMsgILSupport" BO_ 242 1;
BA_ "GenMsgSendType" BO_ 242 0;
BA_ "Type" BO_ 242 1;
BA_ "CANFD_BRS" BO_ 498 1;
BA_ "GenMsgCycleTime" BO_ 498 20;
BA_ "GenMsgILSupport" BO_ 498 1;
BA_ "GenMsgSendType" BO_ 498 0;
BA_ "Type" BO_ 498 1;
BA_ "CANFD_BRS" BO_ 2564682261 1;
BA_ "DiagConnection" BO_ 2564682261 61973;
BA_ "DiagResponse" BO_ 2564682261 1;
BA_ "Type" BO_ 2564682261 8;
BA_ "VFrameFormat" BO_ 2564682261 15;
BA_ "CANFD_BRS" BO_ 2564682260 1;
BA_ "DiagConnection" BO_ 2564682260 61972;
BA_ "DiagResponse" BO_ 2564682260 1;
BA_ "Type" BO_ 2564682260 8;
BA_ "VFrameFormat" BO_ 2564682260 15;
BA_ "VFrameFormat" BO_ 2564485396 1;
BA_ "DiagConnection" BO_ 2564485396 61716;
BA_ "DiagResponse" BO_ 2564485396 1;
BA_ "Type" BO_ 2564485396 8;
BA_ "CANFD_BRS" BO_ 2564485653 1;
BA_ "DiagConnection" BO_ 2564485653 61973;
BA_ "DiagResponse" BO_ 2564485653 1;
BA_ "Type" BO_ 2564485653 8;
BA_ "VFrameFormat" BO_ 2564485653 15;
BA_ "CANFD_BRS" BO_ 2564485652 1;
BA_ "DiagConnection" BO_ 2564485652 61972;
BA_ "DiagResponse" BO_ 2564485652 1;
BA_ "Type" BO_ 2564485652 8;
BA_ "VFrameFormat" BO_ 2564485652 15;
BA_ "VFrameFormat" BO_ 2564429297 1;
BA_ "DiagConnection" BO_ 2564429297 61717;
BA_ "Type" BO_ 2564429297 8;
BA_ "DiagRequest" BO_ 2564429297 1;
BA_ "VFrameFormat" BO_ 2564429041 1;
BA_ "DiagConnection" BO_ 2564429041 61716;
BA_ "Type" BO_ 2564429041 8;
BA_ "DiagRequest" BO_ 2564429041 1;
BA_ "CANFD_BRS" BO_ 2564429298 1;
BA_ "DiagConnection" BO_ 2564429298 61973;
BA_ "Type" BO_ 2564429298 8;
BA_ "DiagRequest" BO_ 2564429298 1;
BA_ "VFrameFormat" BO_ 2564429298 15;
BA_ "CANFD_BRS" BO_ 2564429042 1;
BA_ "DiagConnection" BO_ 2564429042 61972;
BA_ "Type" BO_ 2564429042 8;
BA_ "DiagRequest" BO_ 2564429042 1;
BA_ "VFrameFormat" BO_ 2564429042 15;
BA_ "CANFD_BRS" BO_ 244 1;
BA_ "GenMsgCycleTime" BO_ 244 10;
BA_ "GenMsgILSupport" BO_ 244 1;
BA_ "GenMsgSendType" BO_ 244 0;
BA_ "Type" BO_ 244 1;
BA_ "GenSigTimeoutTime_SGW" SG_ 1579 HVBatteryVoltage_MinCal 0;
BA_ "GenSigTimeoutTime_EVCU2" SG_ 1579 HVBatteryVoltage_MinCal 0;
BA_ "GenSigTimeoutTime_PPIM" SG_ 1579 HVBatteryVoltage_MinCal 0;
BA_ "GenSigTimeoutTime_HCP" SG_ 1579 HVBatteryVoltage_MinCal 0;
BA_ "GenSigTimeoutTime_SGW" SG_ 1579 HVBatteryVoltage_MaxCal 0;
BA_ "GenSigTimeoutTime_EVCU2" SG_ 1579 HVBatteryVoltage_MaxCal 0;
BA_ "GenSigTimeoutTime_PPIM" SG_ 1579 HVBatteryVoltage_MaxCal 0;
BA_ "GenSigTimeoutTime_HCP" SG_ 1579 HVBatteryVoltage_MaxCal 0;
BA_ "GenSigTimeoutTime_SGW" SG_ 1579 HVBatteryCurrent_MaxCal 0;
BA_ "GenSigTimeoutTime_EVCU2" SG_ 1579 HVBatteryCurrent_MaxCal 0;
BA_ "GenSigTimeoutTime_PPIM" SG_ 1579 HVBatteryCurrent_MaxCal 0;
BA_ "GenSigTimeoutTime_HCP" SG_ 1579 HVBatteryCurrent_MaxCal 0;
BA_ "GenSigTimeoutTime_SGW" SG_ 1579 ChargeSystemFaultReason 0;
BA_ "GenSigTimeoutTime_EVCU2" SG_ 1579 ChargeSystemFaultReason 0;
BA_ "GenSigTimeoutTime_BPCM" SG_ 1579 ChargeSystemFaultReason 0;
BA_ "GenSigTimeoutTime_PPIM" SG_ 1579 ChargeSystemFaultReason 0;
BA_ "GenSigTimeoutTime_HCP" SG_ 1579 ChargeSystemFaultReason 0;
BA_ "GenSigTimeoutTime_SGW" SG_ 1579 ACCurrent_MaxCal 0;
BA_ "GenSigTimeoutTime_EVCU2" SG_ 1579 ACCurrent_MaxCal 0;
BA_ "GenSigTimeoutTime_PPIM" SG_ 1579 ACCurrent_MaxCal 0;
BA_ "GenSigTimeoutTime_HCP" SG_ 1579 ACCurrent_MaxCal 0;
BA_ "GenSigTimeoutTime_SGW" SG_ 1579 ChargingLevel 0;
BA_ "GenSigTimeoutTime_EVCU2" SG_ 1579 ChargingLevel 0;
BA_ "GenSigTimeoutTime_PPIM" SG_ 1579 ChargingLevel 0;
BA_ "GenSigTimeoutTime_HCP" SG_ 1579 ChargingLevel 0;
BA_ "GenSigTimeoutTime_SGW" SG_ 1579 OBCM_PLUG_STS 0;
BA_ "GenSigTimeoutTime_EVCU2" SG_ 1579 OBCM_PLUG_STS 0;
BA_ "GenSigTimeoutTime_BPCM" SG_ 1579 OBCM_PLUG_STS 0;
BA_ "GenSigTimeoutTime_PPIM" SG_ 1579 OBCM_PLUG_STS 0;
BA_ "GenSigTimeoutTime_HCP" SG_ 1579 OBCM_PLUG_STS 0;
BA_ "GenSigTimeoutTime_SGW" SG_ 1579 VDCM_UDCChrgr 0;
BA_ "GenSigTimeoutTime_EVCU2" SG_ 1579 VDCM_UDCChrgr 0;
BA_ "GenSigTimeoutTime_BPCM" SG_ 1579 VDCM_UDCChrgr 0;
BA_ "GenSigTimeoutTime_PPIM" SG_ 1579 VDCM_UDCChrgr 0;
BA_ "GenSigTimeoutTime_HCP" SG_ 1579 VDCM_UDCChrgr 0;
BA_ "GenSigTimeoutTime_SGW" SG_ 1579 VDCM_IDCChrgr 0;
BA_ "GenSigTimeoutTime_EVCU2" SG_ 1579 VDCM_IDCChrgr 0;
BA_ "GenSigTimeoutTime_BPCM" SG_ 1579 VDCM_IDCChrgr 0;
BA_ "GenSigTimeoutTime_PPIM" SG_ 1579 VDCM_IDCChrgr 0;
BA_ "GenSigTimeoutTime_HCP" SG_ 1579 VDCM_IDCChrgr 0;
BA_ "GenSigTimeoutTime_SGW" SG_ 1579 ChargeSystemSts 0;
BA_ "GenSigTimeoutTime_EVCU2" SG_ 1579 ChargeSystemSts 0;
BA_ "GenSigTimeoutTime_PPIM" SG_ 1579 ChargeSystemSts 0;
BA_ "GenSigTimeoutTime_HCP" SG_ 1579 ChargeSystemSts 0;
BA_ "GenSigTimeoutTime_SGW" SG_ 1579 ChargeSystemFault 0;
BA_ "GenSigTimeoutTime_EVCU2" SG_ 1579 ChargeSystemFault 0;
BA_ "GenSigTimeoutTime_BPCM" SG_ 1579 ChargeSystemFault 0;
BA_ "GenSigTimeoutTime_PPIM" SG_ 1579 ChargeSystemFault 0;
BA_ "GenSigTimeoutTime_HCP" SG_ 1579 ChargeSystemFault 0;
BA_ "GenSigTimeoutTime_SGW" SG_ 1579 CRC_HYBRID_CHARGING_STATUS 0;
BA_ "GenSigTimeoutTime_EVCU2" SG_ 1579 CRC_HYBRID_CHARGING_STATUS 0;
BA_ "GenSigTimeoutTime_BPCM" SG_ 1579 CRC_HYBRID_CHARGING_STATUS 0;
BA_ "GenSigTimeoutTime_PPIM" SG_ 1579 CRC_HYBRID_CHARGING_STATUS 0;
BA_ "GenSigTimeoutTime_HCP" SG_ 1579 CRC_HYBRID_CHARGING_STATUS 0;
BA_ "GenSigTimeoutTime_SGW" SG_ 1579 MessageCounter_HYBRID_CHARGING_S 0;
BA_ "GenSigTimeoutTime_EVCU2" SG_ 1579 MessageCounter_HYBRID_CHARGING_S 0;
BA_ "GenSigTimeoutTime_BPCM" SG_ 1579 MessageCounter_HYBRID_CHARGING_S 0;
BA_ "GenSigTimeoutTime_PPIM" SG_ 1579 MessageCounter_HYBRID_CHARGING_S 0;
BA_ "GenSigTimeoutTime_HCP" SG_ 1579 MessageCounter_HYBRID_CHARGING_S 0;
BA_ "SystemSignalLongSymbol" SG_ 1579 MessageCounter_HYBRID_CHARGING_S "MessageCounter_HYBRID_CHARGING_STATUS";
BA_ "GenSigTimeoutTime_SGW" SG_ 478 LVDC_VoltageSetpoint 0;
BA_ "GenSigTimeoutTime_IDCM" SG_ 478 LVDC_VoltageSetpoint 0;
BA_ "GenSigTimeoutTime_EVCU2" SG_ 478 LVDC_VoltageSetpoint 0;
BA_ "GenSigStartValue" SG_ 478 LVDC_VoltageSetpoint 221;
BA_ "GenSigTimeoutTime_PPIM" SG_ 478 LVDC_VoltageSetpoint 0;
BA_ "GenSigTimeoutTime_HCP" SG_ 478 LVDC_VoltageSetpoint 0;
BA_ "GenSigTimeoutTime_SGW" SG_ 478 LVDC_SystemVoltageAct 0;
BA_ "GenSigTimeoutTime_IDCM" SG_ 478 LVDC_SystemVoltageAct 0;
BA_ "GenSigTimeoutTime_EVCU2" SG_ 478 LVDC_SystemVoltageAct 0;
BA_ "GenSigTimeoutTime_PPIM" SG_ 478 LVDC_SystemVoltageAct 0;
BA_ "GenSigTimeoutTime_HCP" SG_ 478 LVDC_SystemVoltageAct 0;
BA_ "GenSigTimeoutTime_SGW" SG_ 478 LVDC_CurrentSetpoint 0;
BA_ "GenSigTimeoutTime_IDCM" SG_ 478 LVDC_CurrentSetpoint 0;
BA_ "GenSigTimeoutTime_EVCU2" SG_ 478 LVDC_CurrentSetpoint 0;
BA_ "GenSigStartValue" SG_ 478 LVDC_CurrentSetpoint 255;
BA_ "GenSigTimeoutTime_PPIM" SG_ 478 LVDC_CurrentSetpoint 0;
BA_ "GenSigTimeoutTime_HCP" SG_ 478 LVDC_CurrentSetpoint 0;
BA_ "GenSigTimeoutTime_SGW" SG_ 478 HVInverterVoltage_Rational 0;
BA_ "GenSigTimeoutTime_IDCM" SG_ 478 HVInverterVoltage_Rational 0;
BA_ "GenSigTimeoutTime_EVCU2" SG_ 478 HVInverterVoltage_Rational 0;
BA_ "GenSigTimeoutTime_PPIM" SG_ 478 HVInverterVoltage_Rational 0;
BA_ "GenSigTimeoutTime_HCP" SG_ 478 HVInverterVoltage_Rational 0;
BA_ "GenSigTimeoutTime_SGW" SG_ 478 HVDC_VoltageSetpoint 0;
BA_ "GenSigTimeoutTime_IDCM" SG_ 478 HVDC_VoltageSetpoint 0;
BA_ "GenSigTimeoutTime_EVCU2" SG_ 478 HVDC_VoltageSetpoint 0;
BA_ "GenSigTimeoutTime_PPIM" SG_ 478 HVDC_VoltageSetpoint 0;
BA_ "GenSigTimeoutTime_HCP" SG_ 478 HVDC_VoltageSetpoint 0;
BA_ "GenSigTimeoutTime_SGW" SG_ 478 HVDC_CurrentSetpoint 0;
BA_ "GenSigTimeoutTime_IDCM" SG_ 478 HVDC_CurrentSetpoint 0;
BA_ "GenSigTimeoutTime_EVCU2" SG_ 478 HVDC_CurrentSetpoint 0;
BA_ "GenSigStartValue" SG_ 478 HVDC_CurrentSetpoint 229;
BA_ "GenSigTimeoutTime_PPIM" SG_ 478 HVDC_CurrentSetpoint 0;
BA_ "GenSigTimeoutTime_HCP" SG_ 478 HVDC_CurrentSetpoint 0;
BA_ "GenSigTimeoutTime_PPIM" SG_ 478 EchargeSOCRange_ePT 0;
BA_ "GenSigTimeoutTime_HCP" SG_ 478 EchargeSOCRange_ePT 0;
BA_ "GenSigTimeoutTime_SGW" SG_ 478 EchargeSOCRange_ePT 0;
BA_ "GenSigTimeoutTime_IDCM" SG_ 478 EchargeSOCRange_ePT 0;
BA_ "GenSigTimeoutTime_EVCU2" SG_ 478 EchargeSOCRange_ePT 0;
BA_ "GenSigTimeoutTime_BPCM" SG_ 478 EchargeSOCRange_ePT 0;
BA_ "GenSigTimeoutTime_PPIM" SG_ 478 CRC_HYBRID_CHARGING_COMMAND 0;
BA_ "GenSigTimeoutTime_HCP" SG_ 478 CRC_HYBRID_CHARGING_COMMAND 0;
BA_ "GenSigTimeoutTime_SGW" SG_ 478 CRC_HYBRID_CHARGING_COMMAND 0;
BA_ "GenSigTimeoutTime_EVCU2" SG_ 478 CRC_HYBRID_CHARGING_COMMAND 0;
BA_ "GenSigTimeoutTime_BPCM" SG_ 478 CRC_HYBRID_CHARGING_COMMAND 0;
BA_ "GenSigTimeoutTime_PPIM" SG_ 478 VoltageRequest 0;
BA_ "GenSigTimeoutTime_HCP" SG_ 478 VoltageRequest 0;
BA_ "GenSigTimeoutTime_SGW" SG_ 478 VoltageRequest 0;
BA_ "GenSigTimeoutTime_EVCU2" SG_ 478 VoltageRequest 0;
BA_ "GenSigTimeoutTime_BPCM" SG_ 478 VoltageRequest 0;
BA_ "GenSigTimeoutTime_PPIM" SG_ 478 OBC_ModeRequest 0;
BA_ "GenSigTimeoutTime_HCP" SG_ 478 OBC_ModeRequest 0;
BA_ "GenSigTimeoutTime_SGW" SG_ 478 OBC_ModeRequest 0;
BA_ "GenSigTimeoutTime_EVCU2" SG_ 478 OBC_ModeRequest 0;
BA_ "GenSigTimeoutTime_BPCM" SG_ 478 OBC_ModeRequest 0;
BA_ "GenSigStartValue" SG_ 478 OBC_ModeRequest 7;
BA_ "GenSigTimeoutTime_PPIM" SG_ 478 OBC_ControlMethod 0;
BA_ "GenSigTimeoutTime_HCP" SG_ 478 OBC_ControlMethod 0;
BA_ "GenSigTimeoutTime_SGW" SG_ 478 OBC_ControlMethod 0;
BA_ "GenSigTimeoutTime_EVCU2" SG_ 478 OBC_ControlMethod 0;
BA_ "GenSigTimeoutTime_BPCM" SG_ 478 OBC_ControlMethod 0;
BA_ "GenSigTimeoutTime_SGW" SG_ 478 MainHV_ContactorCommand 0;
BA_ "GenSigTimeoutTime_IDCM" SG_ 478 MainHV_ContactorCommand 0;
BA_ "GenSigTimeoutTime_EVCU2" SG_ 478 MainHV_ContactorCommand 0;
BA_ "GenSigTimeoutTime_PPIM" SG_ 478 MainHV_ContactorCommand 0;
BA_ "GenSigTimeoutTime_HCP" SG_ 478 MainHV_ContactorCommand 0;
BA_ "GenSigTimeoutTime_SGW" SG_ 478 J1772_CloseS2 0;
BA_ "GenSigTimeoutTime_EVCU2" SG_ 478 J1772_CloseS2 0;
BA_ "GenSigTimeoutTime_BPCM" SG_ 478 J1772_CloseS2 0;
BA_ "GenSigTimeoutTime_PPIM" SG_ 478 J1772_CloseS2 0;
BA_ "GenSigTimeoutTime_HCP" SG_ 478 J1772_CloseS2 0;
BA_ "GenSigTimeoutTime_SGW" SG_ 478 HVInverterVoltage_RationalV 0;
BA_ "GenSigTimeoutTime_IDCM" SG_ 478 HVInverterVoltage_RationalV 0;
BA_ "GenSigTimeoutTime_EVCU2" SG_ 478 HVInverterVoltage_RationalV 0;
BA_ "GenSigTimeoutTime_PPIM" SG_ 478 HVInverterVoltage_RationalV 0;
BA_ "GenSigTimeoutTime_HCP" SG_ 478 HVInverterVoltage_RationalV 0;
BA_ "GenSigTimeoutTime_SGW" SG_ 478 HVBatCoolantLevelLow 0;
BA_ "GenSigTimeoutTime_IDCM" SG_ 478 HVBatCoolantLevelLow 0;
BA_ "GenSigTimeoutTime_EVCU2" SG_ 478 HVBatCoolantLevelLow 0;
BA_ "GenSigStartValue" SG_ 478 HVBatCoolantLevelLow 3;
BA_ "GenSigTimeoutTime_SGW" SG_ 478 DCDC_OperationModeEnable 0;
BA_ "GenSigTimeoutTime_IDCM" SG_ 478 DCDC_OperationModeEnable 0;
BA_ "GenSigTimeoutTime_EVCU2" SG_ 478 DCDC_OperationModeEnable 0;
BA_ "GenSigTimeoutTime_PPIM" SG_ 478 DCDC_OperationModeEnable 0;
BA_ "GenSigTimeoutTime_HCP" SG_ 478 DCDC_OperationModeEnable 0;
BA_ "GenSigTimeoutTime_SGW" SG_ 478 ClearLegislatedDiagInfo 0;
BA_ "GenSigTimeoutTime_IDCM" SG_ 478 ClearLegislatedDiagInfo 0;
BA_ "GenSigTimeoutTime_EVCU2" SG_ 478 ClearLegislatedDiagInfo 0;
BA_ "GenSigTimeoutTime_PPIM" SG_ 478 ClearLegislatedDiagInfo 0;
BA_ "GenSigTimeoutTime_HCP" SG_ 478 ClearLegislatedDiagInfo 0;
BA_ "GenSigTimeoutTime_SGW" SG_ 478 OBC_OperativeModeReq 0;
BA_ "GenSigTimeoutTime_EVCU2" SG_ 478 OBC_OperativeModeReq 0;
BA_ "GenSigTimeoutTime_BPCM" SG_ 478 OBC_OperativeModeReq 0;
BA_ "GenSigStartValue" SG_ 478 OBC_OperativeModeReq 15;
BA_ "GenSigTimeoutTime_PPIM" SG_ 478 OBC_OperativeModeReq 0;
BA_ "GenSigTimeoutTime_HCP" SG_ 478 OBC_OperativeModeReq 0;
BA_ "GenSigTimeoutTime_SGW" SG_ 478 HV_Volt_Min_Thrsh 0;
BA_ "GenSigTimeoutTime_EVCU2" SG_ 478 HV_Volt_Min_Thrsh 0;
BA_ "GenSigTimeoutTime_BPCM" SG_ 478 HV_Volt_Min_Thrsh 0;
BA_ "GenSigTimeoutTime_PPIM" SG_ 478 HV_Volt_Min_Thrsh 0;
BA_ "GenSigTimeoutTime_HCP" SG_ 478 HV_Volt_Min_Thrsh 0;
BA_ "GenSigTimeoutTime_SGW" SG_ 478 HV_Volt_Max_Thrsh 0;
BA_ "GenSigTimeoutTime_EVCU2" SG_ 478 HV_Volt_Max_Thrsh 0;
BA_ "GenSigTimeoutTime_BPCM" SG_ 478 HV_Volt_Max_Thrsh 0;
BA_ "GenSigTimeoutTime_PPIM" SG_ 478 HV_Volt_Max_Thrsh 0;
BA_ "GenSigTimeoutTime_HCP" SG_ 478 HV_Volt_Max_Thrsh 0;
BA_ "GenSigTimeoutTime_SGW" SG_ 478 DC_Curr_Max_Thrsh 0;
BA_ "GenSigTimeoutTime_EVCU2" SG_ 478 DC_Curr_Max_Thrsh 0;
BA_ "GenSigTimeoutTime_BPCM" SG_ 478 DC_Curr_Max_Thrsh 0;
BA_ "GenSigStartValue" SG_ 478 DC_Curr_Max_Thrsh 511;
BA_ "GenSigTimeoutTime_PPIM" SG_ 478 DC_Curr_Max_Thrsh 0;
BA_ "GenSigTimeoutTime_HCP" SG_ 478 DC_Curr_Max_Thrsh 0;
BA_ "GenSigTimeoutTime_SGW" SG_ 478 ChargeEnable 0;
BA_ "GenSigTimeoutTime_EVCU2" SG_ 478 ChargeEnable 0;
BA_ "GenSigTimeoutTime_BPCM" SG_ 478 ChargeEnable 0;
BA_ "GenSigTimeoutTime_PPIM" SG_ 478 ChargeEnable 0;
BA_ "GenSigTimeoutTime_HCP" SG_ 478 ChargeEnable 0;
BA_ "GenSigTimeoutTime_BPCM" SG_ 478 AC_Curr_Min_Thrsh 0;
BA_ "GenSigTimeoutTime_PPIM" SG_ 478 AC_Curr_Min_Thrsh 0;
BA_ "GenSigTimeoutTime_HCP" SG_ 478 AC_Curr_Min_Thrsh 0;
BA_ "GenSigTimeoutTime_SGW" SG_ 478 AC_Curr_Min_Thrsh 0;
BA_ "GenSigTimeoutTime_EVCU2" SG_ 478 AC_Curr_Min_Thrsh 0;
BA_ "GenSigTimeoutTime_SGW" SG_ 478 AC_Curr_Max_Thrsh 0;
BA_ "GenSigTimeoutTime_EVCU2" SG_ 478 AC_Curr_Max_Thrsh 0;
BA_ "GenSigTimeoutTime_BPCM" SG_ 478 AC_Curr_Max_Thrsh 0;
BA_ "GenSigTimeoutTime_PPIM" SG_ 478 AC_Curr_Max_Thrsh 0;
BA_ "GenSigTimeoutTime_HCP" SG_ 478 AC_Curr_Max_Thrsh 0;
BA_ "GenSigTimeoutTime_SGW" SG_ 478 CurrentRequest 0;
BA_ "GenSigTimeoutTime_EVCU2" SG_ 478 CurrentRequest 0;
BA_ "GenSigTimeoutTime_BPCM" SG_ 478 CurrentRequest 0;
BA_ "GenSigTimeoutTime_PPIM" SG_ 478 CurrentRequest 0;
BA_ "GenSigTimeoutTime_HCP" SG_ 478 CurrentRequest 0;
BA_ "GenSigTimeoutTime_SGW" SG_ 478 VDCM_StsWldgReq 0;
BA_ "GenSigTimeoutTime_EVCU2" SG_ 478 VDCM_StsWldgReq 0;
BA_ "GenSigTimeoutTime_BPCM" SG_ 478 VDCM_StsWldgReq 0;
BA_ "GenSigTimeoutTime_PPIM" SG_ 478 VDCM_StsWldgReq 0;
BA_ "GenSigTimeoutTime_HCP" SG_ 478 VDCM_StsWldgReq 0;
BA_ "GenSigTimeoutTime_PPIM" SG_ 478 VDCM_SessnStopReq 0;
BA_ "GenSigTimeoutTime_HCP" SG_ 478 VDCM_SessnStopReq 0;
BA_ "GenSigTimeoutTime_SGW" SG_ 478 VDCM_SessnStopReq 0;
BA_ "GenSigTimeoutTime_EVCU2" SG_ 478 VDCM_SessnStopReq 0;
BA_ "GenSigTimeoutTime_BPCM" SG_ 478 VDCM_SessnStopReq 0;
BA_ "GenSigTimeoutTime_SGW" SG_ 478 VDCM_StsSWWldgReq 0;
BA_ "GenSigTimeoutTime_IDCM" SG_ 478 VDCM_StsSWWldgReq 0;
BA_ "GenSigTimeoutTime_EVCU2" SG_ 478 VDCM_StsSWWldgReq 0;
BA_ "GenSigTimeoutTime_BPCM" SG_ 478 VDCM_StsSWWldgReq 0;
BA_ "GenSigTimeoutTime_PPIM" SG_ 478 VDCM_StsSWWldgReq 0;
BA_ "GenSigTimeoutTime_HCP" SG_ 478 VDCM_StsSWWldgReq 0;
BA_ "GenSigTimeoutTime_SGW" SG_ 478 MessageCounter_HYBRID_CHARGING_C 0;
BA_ "GenSigTimeoutTime_EVCU2" SG_ 478 MessageCounter_HYBRID_CHARGING_C 0;
BA_ "GenSigTimeoutTime_BPCM" SG_ 478 MessageCounter_HYBRID_CHARGING_C 0;
BA_ "GenSigTimeoutTime_PPIM" SG_ 478 MessageCounter_HYBRID_CHARGING_C 0;
BA_ "GenSigTimeoutTime_HCP" SG_ 478 MessageCounter_HYBRID_CHARGING_C 0;
BA_ "SystemSignalLongSymbol" SG_ 478 MessageCounter_HYBRID_CHARGING_C "MessageCounter_HYBRID_CHARGING_COMMAND";
BA_ "GenSigTimeoutTime_SGW" SG_ 478 MaxCurrentAllwd 0;
BA_ "GenSigTimeoutTime_EVCU2" SG_ 478 MaxCurrentAllwd 0;
BA_ "GenSigTimeoutTime_BPCM" SG_ 478 MaxCurrentAllwd 0;
BA_ "GenSigTimeoutTime_PPIM" SG_ 478 MaxCurrentAllwd 0;
BA_ "GenSigTimeoutTime_HCP" SG_ 478 MaxCurrentAllwd 0;
BA_ "GenSigTimeoutTime_SGW" SG_ 1578 OBC_IdleTimeSec 0;
BA_ "GenSigTimeoutTime_IDCM" SG_ 1578 OBC_IdleTimeSec 0;
BA_ "GenSigTimeoutTime_BPCM" SG_ 1578 OBC_IdleTimeSec 0;
BA_ "GenSigTimeoutTime_PPIM" SG_ 1578 OBC_IdleTimeSec 0;
BA_ "GenSigTimeoutTime_HCP" SG_ 1578 OBC_IdleTimeSec 0;
BA_ "GenSigTimeoutTime_SGW" SG_ 1578 OBC_IdleTimeMin 0;
BA_ "GenSigTimeoutTime_IDCM" SG_ 1578 OBC_IdleTimeMin 0;
BA_ "GenSigTimeoutTime_BPCM" SG_ 1578 OBC_IdleTimeMin 0;
BA_ "GenSigTimeoutTime_PPIM" SG_ 1578 OBC_IdleTimeMin 0;
BA_ "GenSigTimeoutTime_HCP" SG_ 1578 OBC_IdleTimeMin 0;
BA_ "GenSigTimeoutTime_SGW" SG_ 1578 OBC_ChargeTimeSec 0;
BA_ "GenSigTimeoutTime_IDCM" SG_ 1578 OBC_ChargeTimeSec 0;
BA_ "GenSigTimeoutTime_BPCM" SG_ 1578 OBC_ChargeTimeSec 0;
BA_ "GenSigTimeoutTime_PPIM" SG_ 1578 OBC_ChargeTimeSec 0;
BA_ "GenSigTimeoutTime_HCP" SG_ 1578 OBC_ChargeTimeSec 0;
BA_ "GenSigTimeoutTime_SGW" SG_ 1578 OBC_ChargeTimeMin 0;
BA_ "GenSigTimeoutTime_IDCM" SG_ 1578 OBC_ChargeTimeMin 0;
BA_ "GenSigTimeoutTime_BPCM" SG_ 1578 OBC_ChargeTimeMin 0;
BA_ "GenSigTimeoutTime_PPIM" SG_ 1578 OBC_ChargeTimeMin 0;
BA_ "GenSigTimeoutTime_HCP" SG_ 1578 OBC_ChargeTimeMin 0;
BA_ "GenSigTimeoutTime_SGW" SG_ 1578 Charging_WHr 0;
BA_ "GenSigTimeoutTime_IDCM" SG_ 1578 Charging_WHr 0;
BA_ "GenSigTimeoutTime_BPCM" SG_ 1578 Charging_WHr 0;
BA_ "GenSigTimeoutTime_PPIM" SG_ 1578 Charging_WHr 0;
BA_ "GenSigTimeoutTime_HCP" SG_ 1578 Charging_WHr 0;
BA_ "GenSigTimeoutTime_SGW" SG_ 1578 OnboardChargerReady 0;
BA_ "GenSigTimeoutTime_IDCM" SG_ 1578 OnboardChargerReady 0;
BA_ "GenSigTimeoutTime_BPCM" SG_ 1578 OnboardChargerReady 0;
BA_ "GenSigStartValue" SG_ 1578 OnboardChargerReady 1;
BA_ "GenSigTimeoutTime_PPIM" SG_ 1578 OnboardChargerReady 0;
BA_ "GenSigTimeoutTime_HCP" SG_ 1578 OnboardChargerReady 0;
BA_ "GenSigTimeoutTime_SGW" SG_ 1578 OnboardChargerMode 0;
BA_ "GenSigTimeoutTime_IDCM" SG_ 1578 OnboardChargerMode 0;
BA_ "GenSigTimeoutTime_BPCM" SG_ 1578 OnboardChargerMode 0;
BA_ "GenSigSendType" SG_ 1578 OnboardChargerMode 4;
BA_ "GenSigTimeoutTime_PPIM" SG_ 1578 OnboardChargerMode 0;
BA_ "GenSigTimeoutTime_HCP" SG_ 1578 OnboardChargerMode 0;
BA_ "GenSigTimeoutTime_SGW" SG_ 1578 OBC_WakeReason 0;
BA_ "GenSigTimeoutTime_IDCM" SG_ 1578 OBC_WakeReason 0;
BA_ "GenSigTimeoutTime_BPCM" SG_ 1578 OBC_WakeReason 0;
BA_ "GenSigTimeoutTime_PPIM" SG_ 1578 OBC_WakeReason 0;
BA_ "GenSigTimeoutTime_HCP" SG_ 1578 OBC_WakeReason 0;
BA_ "GenSigTimeoutTime_SGW" SG_ 1578 OBC_GenericFailSts 0;
BA_ "GenSigTimeoutTime_IDCM" SG_ 1578 OBC_GenericFailSts 0;
BA_ "GenSigTimeoutTime_BPCM" SG_ 1578 OBC_GenericFailSts 0;
BA_ "GenSigTimeoutTime_PPIM" SG_ 1578 OBC_GenericFailSts 0;
BA_ "GenSigTimeoutTime_HCP" SG_ 1578 OBC_GenericFailSts 0;
BA_ "GenSigTimeoutTime_SGW" SG_ 1578 OBC_FaultReason 0;
BA_ "GenSigTimeoutTime_IDCM" SG_ 1578 OBC_FaultReason 0;
BA_ "GenSigTimeoutTime_BPCM" SG_ 1578 OBC_FaultReason 0;
BA_ "GenSigTimeoutTime_PPIM" SG_ 1578 OBC_FaultReason 0;
BA_ "GenSigTimeoutTime_HCP" SG_ 1578 OBC_FaultReason 0;
BA_ "GenSigTimeoutTime_SGW" SG_ 1578 OBC_EVServiceLampOn 0;
BA_ "GenSigTimeoutTime_IDCM" SG_ 1578 OBC_EVServiceLampOn 0;
BA_ "GenSigTimeoutTime_BPCM" SG_ 1578 OBC_EVServiceLampOn 0;
BA_ "GenSigTimeoutTime_PPIM" SG_ 1578 OBC_EVServiceLampOn 0;
BA_ "GenSigTimeoutTime_HCP" SG_ 1578 OBC_EVServiceLampOn 0;
BA_ "GenSigTimeoutTime_SGW" SG_ 1578 OBC_EVServiceLampFlash 0;
BA_ "GenSigTimeoutTime_IDCM" SG_ 1578 OBC_EVServiceLampFlash 0;
BA_ "GenSigTimeoutTime_BPCM" SG_ 1578 OBC_EVServiceLampFlash 0;
BA_ "GenSigTimeoutTime_PPIM" SG_ 1578 OBC_EVServiceLampFlash 0;
BA_ "GenSigTimeoutTime_HCP" SG_ 1578 OBC_EVServiceLampFlash 0;
BA_ "GenSigTimeoutTime_SGW" SG_ 1578 OBC_CurrentFailureSts 0;
BA_ "GenSigTimeoutTime_IDCM" SG_ 1578 OBC_CurrentFailureSts 0;
BA_ "GenSigTimeoutTime_BPCM" SG_ 1578 OBC_CurrentFailureSts 0;
BA_ "GenSigTimeoutTime_PPIM" SG_ 1578 OBC_CurrentFailureSts 0;
BA_ "GenSigTimeoutTime_HCP" SG_ 1578 OBC_CurrentFailureSts 0;
BA_ "GenSigTimeoutTime_SGW" SG_ 1578 OBC_ChargingFaultSts 0;
BA_ "GenSigTimeoutTime_IDCM" SG_ 1578 OBC_ChargingFaultSts 0;
BA_ "GenSigTimeoutTime_BPCM" SG_ 1578 OBC_ChargingFaultSts 0;
BA_ "GenSigTimeoutTime_PPIM" SG_ 1578 OBC_ChargingFaultSts 0;
BA_ "GenSigTimeoutTime_HCP" SG_ 1578 OBC_ChargingFaultSts 0;
BA_ "GenSigTimeoutTime_SGW" SG_ 1578 OBC_ChargeFailure 0;
BA_ "GenSigTimeoutTime_IDCM" SG_ 1578 OBC_ChargeFailure 0;
BA_ "GenSigTimeoutTime_BPCM" SG_ 1578 OBC_ChargeFailure 0;
BA_ "GenSigTimeoutTime_PPIM" SG_ 1578 OBC_ChargeFailure 0;
BA_ "GenSigTimeoutTime_HCP" SG_ 1578 OBC_ChargeFailure 0;
BA_ "GenSigTimeoutTime_SGW" SG_ 1578 OBC_CaptureEnvironmentData 0;
BA_ "GenSigTimeoutTime_IDCM" SG_ 1578 OBC_CaptureEnvironmentData 0;
BA_ "GenSigTimeoutTime_BPCM" SG_ 1578 OBC_CaptureEnvironmentData 0;
BA_ "GenSigTimeoutTime_PPIM" SG_ 1578 OBC_CaptureEnvironmentData 0;
BA_ "GenSigTimeoutTime_HCP" SG_ 1578 OBC_CaptureEnvironmentData 0;
BA_ "GenSigTimeoutTime_SGW" SG_ 1578 ACplug_PwrMax 0;
BA_ "GenSigTimeoutTime_IDCM" SG_ 1578 ACplug_PwrMax 0;
BA_ "GenSigTimeoutTime_BPCM" SG_ 1578 ACplug_PwrMax 0;
BA_ "GenSigTimeoutTime_PPIM" SG_ 1578 ACplug_PwrMax 0;
BA_ "GenSigTimeoutTime_HCP" SG_ 1578 ACplug_PwrMax 0;
BA_ "GenSigTimeoutTime_SGW" SG_ 1578 OBC_Prox 0;
BA_ "GenSigTimeoutTime_IDCM" SG_ 1578 OBC_Prox 0;
BA_ "GenSigTimeoutTime_BPCM" SG_ 1578 OBC_Prox 0;
BA_ "GenSigTimeoutTime_PPIM" SG_ 1578 OBC_Prox 0;
BA_ "GenSigTimeoutTime_HCP" SG_ 1578 OBC_Prox 0;
BA_ "GenSigTimeoutTime_SGW" SG_ 1578 OBC_Pilot 0;
BA_ "GenSigTimeoutTime_IDCM" SG_ 1578 OBC_Pilot 0;
BA_ "GenSigTimeoutTime_BPCM" SG_ 1578 OBC_Pilot 0;
BA_ "GenSigTimeoutTime_PPIM" SG_ 1578 OBC_Pilot 0;
BA_ "GenSigTimeoutTime_HCP" SG_ 1578 OBC_Pilot 0;
BA_ "GenSigTimeoutTime_SGW" SG_ 1578 OBCM_PrechargeSts 0;
BA_ "GenSigTimeoutTime_IDCM" SG_ 1578 OBCM_PrechargeSts 0;
BA_ "GenSigTimeoutTime_BPCM" SG_ 1578 OBCM_PrechargeSts 0;
BA_ "GenSigTimeoutTime_PPIM" SG_ 1578 OBCM_PrechargeSts 0;
BA_ "GenSigTimeoutTime_HCP" SG_ 1578 OBCM_PrechargeSts 0;
BA_ "GenSigTimeoutTime_SGW" SG_ 1578 ChrgFailSts 0;
BA_ "GenSigTimeoutTime_IDCM" SG_ 1578 ChrgFailSts 0;
BA_ "GenSigTimeoutTime_BPCM" SG_ 1578 ChrgFailSts 0;
BA_ "GenSigTimeoutTime_PPIM" SG_ 1578 ChrgFailSts 0;
BA_ "GenSigTimeoutTime_HCP" SG_ 1578 ChrgFailSts 0;
BA_ "GenSigTimeoutTime_SGW" SG_ 1372 OBC_Temp4 0;
BA_ "GenSigTimeoutTime_IDCM" SG_ 1372 OBC_Temp4 0;
BA_ "GenSigTimeoutTime_BPCM" SG_ 1372 OBC_Temp4 0;
BA_ "GenSigTimeoutTime_PPIM" SG_ 1372 OBC_Temp4 0;
BA_ "GenSigTimeoutTime_HCP" SG_ 1372 OBC_Temp4 0;
BA_ "GenSigTimeoutTime_HCP" SG_ 1372 OBC_Temp3 0;
BA_ "GenSigTimeoutTime_SGW" SG_ 1372 OBC_Temp3 0;
BA_ "GenSigTimeoutTime_IDCM" SG_ 1372 OBC_Temp3 0;
BA_ "GenSigTimeoutTime_BPCM" SG_ 1372 OBC_Temp3 0;
BA_ "GenSigTimeoutTime_PPIM" SG_ 1372 OBC_Temp3 0;
BA_ "GenSigTimeoutTime_PPIM" SG_ 1372 OBC_Temp2 0;
BA_ "GenSigTimeoutTime_HCP" SG_ 1372 OBC_Temp2 0;
BA_ "GenSigTimeoutTime_SGW" SG_ 1372 OBC_Temp2 0;
BA_ "GenSigTimeoutTime_IDCM" SG_ 1372 OBC_Temp2 0;
BA_ "GenSigTimeoutTime_BPCM" SG_ 1372 OBC_Temp2 0;
BA_ "GenSigTimeoutTime_PPIM" SG_ 1372 OBC_Temp1 0;
BA_ "GenSigTimeoutTime_HCP" SG_ 1372 OBC_Temp1 0;
BA_ "GenSigTimeoutTime_SGW" SG_ 1372 OBC_Temp1 0;
BA_ "GenSigTimeoutTime_IDCM" SG_ 1372 OBC_Temp1 0;
BA_ "GenSigTimeoutTime_BPCM" SG_ 1372 OBC_Temp1 0;
BA_ "GenSigTimeoutTime_SGW" SG_ 2564682064 N_PDU_18DDF150 0;
BA_ "GenSigTimeoutTime_IDCM" SG_ 2564682064 N_PDU_18DDF150 0;
BA_ "GenSigTimeoutTime_EVCU2" SG_ 2564682064 N_PDU_18DDF150 0;
BA_ "GenSigTimeoutTime_BPCM" SG_ 2564682064 N_PDU_18DDF150 0;
BA_ "GenSigTimeoutTime_PPIM" SG_ 2564682064 N_PDU_18DDF150 0;
BA_ "GenSigTimeoutTime_HCP" SG_ 2564682064 N_PDU_18DDF150 0;
BA_ "GenSigTimeoutTime_SGW" SG_ 2564682059 N_PDU_18DDF14B 0;
BA_ "GenSigTimeoutTime_IDCM" SG_ 2564682059 N_PDU_18DDF14B 0;
BA_ "GenSigTimeoutTime_EVCU2" SG_ 2564682059 N_PDU_18DDF14B 0;
BA_ "GenSigTimeoutTime_BPCM" SG_ 2564682059 N_PDU_18DDF14B 0;
BA_ "GenSigTimeoutTime_PPIM" SG_ 2564682059 N_PDU_18DDF14B 0;
BA_ "GenSigTimeoutTime_HCP" SG_ 2564682059 N_PDU_18DDF14B 0;
BA_ "GenSigTimeoutTime_SGW" SG_ 2564682320 N_PDU_18DDF250 0;
BA_ "GenSigTimeoutTime_IDCM" SG_ 2564682320 N_PDU_18DDF250 0;
BA_ "GenSigTimeoutTime_EVCU2" SG_ 2564682320 N_PDU_18DDF250 0;
BA_ "GenSigTimeoutTime_BPCM" SG_ 2564682320 N_PDU_18DDF250 0;
BA_ "GenSigTimeoutTime_PPIM" SG_ 2564682320 N_PDU_18DDF250 0;
BA_ "GenSigTimeoutTime_HCP" SG_ 2564682320 N_PDU_18DDF250 0;
BA_ "GenSigTimeoutTime_SGW" SG_ 2564682315 N_PDU_18DDF24B 0;
BA_ "GenSigTimeoutTime_IDCM" SG_ 2564682315 N_PDU_18DDF24B 0;
BA_ "GenSigTimeoutTime_EVCU2" SG_ 2564682315 N_PDU_18DDF24B 0;
BA_ "GenSigTimeoutTime_BPCM" SG_ 2564682315 N_PDU_18DDF24B 0;
BA_ "GenSigTimeoutTime_PPIM" SG_ 2564682315 N_PDU_18DDF24B 0;
BA_ "GenSigTimeoutTime_HCP" SG_ 2564682315 N_PDU_18DDF24B 0;
BA_ "GenSigTimeoutTime_SGW" SG_ 2564682308 N_PDU_18DDF244 0;
BA_ "GenSigTimeoutTime_IDCM" SG_ 2564682308 N_PDU_18DDF244 0;
BA_ "GenSigTimeoutTime_EVCU2" SG_ 2564682308 N_PDU_18DDF244 0;
BA_ "GenSigTimeoutTime_BPCM" SG_ 2564682308 N_PDU_18DDF244 0;
BA_ "GenSigTimeoutTime_PPIM" SG_ 2564682308 N_PDU_18DDF244 0;
BA_ "GenSigTimeoutTime_HCP" SG_ 2564682308 N_PDU_18DDF244 0;
BA_ "GenSigTimeoutTime_SGW" SG_ 2564682052 N_PDU_18DDF144 0;
BA_ "GenSigTimeoutTime_IDCM" SG_ 2564682052 N_PDU_18DDF144 0;
BA_ "GenSigTimeoutTime_EVCU2" SG_ 2564682052 N_PDU_18DDF144 0;
BA_ "GenSigTimeoutTime_BPCM" SG_ 2564682052 N_PDU_18DDF144 0;
BA_ "GenSigTimeoutTime_PPIM" SG_ 2564682052 N_PDU_18DDF144 0;
BA_ "GenSigTimeoutTime_HCP" SG_ 2564682052 N_PDU_18DDF144 0;
BA_ "GenSigTimeoutTime_SGW" SG_ 2564485712 N_PDU_18DAF250 0;
BA_ "GenSigTimeoutTime_IDCM" SG_ 2564485712 N_PDU_18DAF250 0;
BA_ "GenSigTimeoutTime_EVCU2" SG_ 2564485712 N_PDU_18DAF250 0;
BA_ "GenSigTimeoutTime_BPCM" SG_ 2564485712 N_PDU_18DAF250 0;
BA_ "GenSigTimeoutTime_PPIM" SG_ 2564485712 N_PDU_18DAF250 0;
BA_ "GenSigTimeoutTime_HCP" SG_ 2564485712 N_PDU_18DAF250 0;
BA_ "GenSigTimeoutTime_SGW" SG_ 2564485707 N_PDU_18DAF24B 0;
BA_ "GenSigTimeoutTime_IDCM" SG_ 2564485707 N_PDU_18DAF24B 0;
BA_ "GenSigTimeoutTime_EVCU2" SG_ 2564485707 N_PDU_18DAF24B 0;
BA_ "GenSigTimeoutTime_BPCM" SG_ 2564485707 N_PDU_18DAF24B 0;
BA_ "GenSigTimeoutTime_PPIM" SG_ 2564485707 N_PDU_18DAF24B 0;
BA_ "GenSigTimeoutTime_HCP" SG_ 2564485707 N_PDU_18DAF24B 0;
BA_ "GenSigTimeoutTime_SGW" SG_ 2564485700 N_PDU_18DAF244 0;
BA_ "GenSigTimeoutTime_IDCM" SG_ 2564485700 N_PDU_18DAF244 0;
BA_ "GenSigTimeoutTime_EVCU2" SG_ 2564485700 N_PDU_18DAF244 0;
BA_ "GenSigTimeoutTime_BPCM" SG_ 2564485700 N_PDU_18DAF244 0;
BA_ "GenSigTimeoutTime_PPIM" SG_ 2564485700 N_PDU_18DAF244 0;
BA_ "GenSigTimeoutTime_HCP" SG_ 2564485700 N_PDU_18DAF244 0;
BA_ "GenSigTimeoutTime_SGW" SG_ 2564444402 N_PDU_18DA50F2 0;
BA_ "GenSigTimeoutTime_IDCM" SG_ 2564444402 N_PDU_18DA50F2 0;
BA_ "GenSigTimeoutTime_EVCU2" SG_ 2564444402 N_PDU_18DA50F2 0;
BA_ "GenSigTimeoutTime_BPCM" SG_ 2564444402 N_PDU_18DA50F2 0;
BA_ "GenSigTimeoutTime_PPIM" SG_ 2564444402 N_PDU_18DA50F2 0;
BA_ "GenSigTimeoutTime_HCP" SG_ 2564444402 N_PDU_18DA50F2 0;
BA_ "GenSigTimeoutTime_SGW" SG_ 2564443122 N_PDU_18DA4BF2 0;
BA_ "GenSigTimeoutTime_IDCM" SG_ 2564443122 N_PDU_18DA4BF2 0;
BA_ "GenSigTimeoutTime_EVCU2" SG_ 2564443122 N_PDU_18DA4BF2 0;
BA_ "GenSigTimeoutTime_BPCM" SG_ 2564443122 N_PDU_18DA4BF2 0;
BA_ "GenSigTimeoutTime_PPIM" SG_ 2564443122 N_PDU_18DA4BF2 0;
BA_ "GenSigTimeoutTime_HCP" SG_ 2564443122 N_PDU_18DA4BF2 0;
BA_ "GenSigTimeoutTime_SGW" SG_ 2564441330 N_PDU_18DA44F2 0;
BA_ "GenSigTimeoutTime_IDCM" SG_ 2564441330 N_PDU_18DA44F2 0;
BA_ "GenSigTimeoutTime_EVCU2" SG_ 2564441330 N_PDU_18DA44F2 0;
BA_ "GenSigTimeoutTime_BPCM" SG_ 2564441330 N_PDU_18DA44F2 0;
BA_ "GenSigTimeoutTime_PPIM" SG_ 2564441330 N_PDU_18DA44F2 0;
BA_ "GenSigTimeoutTime_HCP" SG_ 2564441330 N_PDU_18DA44F2 0;
BA_ "GenSigTimeoutTime_SGW" SG_ 2651930749 Digit_11_IDCM 0;
BA_ "GenSigTimeoutTime_IDCM" SG_ 2651930749 Digit_11_IDCM 0;
BA_ "GenSigTimeoutTime_BPCM" SG_ 2651930749 Digit_11_IDCM 0;
BA_ "GenSigTimeoutTime_EVCU2" SG_ 2651930749 Digit_11_IDCM 0;
BA_ "GenSigTimeoutTime_PPIM" SG_ 2651930749 Digit_11_IDCM 0;
BA_ "GenSigTimeoutTime_HCP" SG_ 2651930749 Digit_11_IDCM 0;
BA_ "GenSigTimeoutTime_SGW" SG_ 2651930749 Digit_10_IDCM 0;
BA_ "GenSigTimeoutTime_IDCM" SG_ 2651930749 Digit_10_IDCM 0;
BA_ "GenSigTimeoutTime_BPCM" SG_ 2651930749 Digit_10_IDCM 0;
BA_ "GenSigTimeoutTime_EVCU2" SG_ 2651930749 Digit_10_IDCM 0;
BA_ "GenSigTimeoutTime_PPIM" SG_ 2651930749 Digit_10_IDCM 0;
BA_ "GenSigTimeoutTime_HCP" SG_ 2651930749 Digit_10_IDCM 0;
BA_ "GenSigTimeoutTime_SGW" SG_ 2651930749 Digit_09_IDCM 0;
BA_ "GenSigTimeoutTime_IDCM" SG_ 2651930749 Digit_09_IDCM 0;
BA_ "GenSigTimeoutTime_BPCM" SG_ 2651930749 Digit_09_IDCM 0;
BA_ "GenSigTimeoutTime_EVCU2" SG_ 2651930749 Digit_09_IDCM 0;
BA_ "GenSigTimeoutTime_PPIM" SG_ 2651930749 Digit_09_IDCM 0;
BA_ "GenSigTimeoutTime_HCP" SG_ 2651930749 Digit_09_IDCM 0;
BA_ "GenSigTimeoutTime_SGW" SG_ 2651930749 Digit_08_IDCM 0;
BA_ "GenSigTimeoutTime_IDCM" SG_ 2651930749 Digit_08_IDCM 0;
BA_ "GenSigTimeoutTime_BPCM" SG_ 2651930749 Digit_08_IDCM 0;
BA_ "GenSigTimeoutTime_EVCU2" SG_ 2651930749 Digit_08_IDCM 0;
BA_ "GenSigTimeoutTime_PPIM" SG_ 2651930749 Digit_08_IDCM 0;
BA_ "GenSigTimeoutTime_HCP" SG_ 2651930749 Digit_08_IDCM 0;
BA_ "GenSigTimeoutTime_SGW" SG_ 2651930749 Digit_07_IDCM 0;
BA_ "GenSigTimeoutTime_IDCM" SG_ 2651930749 Digit_07_IDCM 0;
BA_ "GenSigTimeoutTime_BPCM" SG_ 2651930749 Digit_07_IDCM 0;
BA_ "GenSigTimeoutTime_EVCU2" SG_ 2651930749 Digit_07_IDCM 0;
BA_ "GenSigTimeoutTime_PPIM" SG_ 2651930749 Digit_07_IDCM 0;
BA_ "GenSigTimeoutTime_HCP" SG_ 2651930749 Digit_07_IDCM 0;
BA_ "GenSigTimeoutTime_SGW" SG_ 2651930749 Digit_06_IDCM 0;
BA_ "GenSigTimeoutTime_IDCM" SG_ 2651930749 Digit_06_IDCM 0;
BA_ "GenSigTimeoutTime_BPCM" SG_ 2651930749 Digit_06_IDCM 0;
BA_ "GenSigTimeoutTime_EVCU2" SG_ 2651930749 Digit_06_IDCM 0;
BA_ "GenSigTimeoutTime_PPIM" SG_ 2651930749 Digit_06_IDCM 0;
BA_ "GenSigTimeoutTime_HCP" SG_ 2651930749 Digit_06_IDCM 0;
BA_ "GenSigTimeoutTime_SGW" SG_ 2651930749 Digit_05_IDCM 0;
BA_ "GenSigTimeoutTime_IDCM" SG_ 2651930749 Digit_05_IDCM 0;
BA_ "GenSigTimeoutTime_BPCM" SG_ 2651930749 Digit_05_IDCM 0;
BA_ "GenSigTimeoutTime_EVCU2" SG_ 2651930749 Digit_05_IDCM 0;
BA_ "GenSigTimeoutTime_PPIM" SG_ 2651930749 Digit_05_IDCM 0;
BA_ "GenSigTimeoutTime_HCP" SG_ 2651930749 Digit_05_IDCM 0;
BA_ "GenSigTimeoutTime_SGW" SG_ 2651930749 Digit_04_IDCM 0;
BA_ "GenSigTimeoutTime_IDCM" SG_ 2651930749 Digit_04_IDCM 0;
BA_ "GenSigTimeoutTime_BPCM" SG_ 2651930749 Digit_04_IDCM 0;
BA_ "GenSigTimeoutTime_EVCU2" SG_ 2651930749 Digit_04_IDCM 0;
BA_ "GenSigTimeoutTime_PPIM" SG_ 2651930749 Digit_04_IDCM 0;
BA_ "GenSigTimeoutTime_HCP" SG_ 2651930749 Digit_04_IDCM 0;
BA_ "GenSigTimeoutTime_SGW" SG_ 2651930749 Digit_03_IDCM 0;
BA_ "GenSigTimeoutTime_IDCM" SG_ 2651930749 Digit_03_IDCM 0;
BA_ "GenSigTimeoutTime_BPCM" SG_ 2651930749 Digit_03_IDCM 0;
BA_ "GenSigTimeoutTime_EVCU2" SG_ 2651930749 Digit_03_IDCM 0;
BA_ "GenSigTimeoutTime_PPIM" SG_ 2651930749 Digit_03_IDCM 0;
BA_ "GenSigTimeoutTime_HCP" SG_ 2651930749 Digit_03_IDCM 0;
BA_ "GenSigTimeoutTime_SGW" SG_ 2651930749 Digit_02_IDCM 0;
BA_ "GenSigTimeoutTime_IDCM" SG_ 2651930749 Digit_02_IDCM 0;
BA_ "GenSigTimeoutTime_BPCM" SG_ 2651930749 Digit_02_IDCM 0;
BA_ "GenSigTimeoutTime_EVCU2" SG_ 2651930749 Digit_02_IDCM 0;
BA_ "GenSigTimeoutTime_PPIM" SG_ 2651930749 Digit_02_IDCM 0;
BA_ "GenSigTimeoutTime_HCP" SG_ 2651930749 Digit_02_IDCM 0;
BA_ "GenSigTimeoutTime_SGW" SG_ 2651930749 Digit_01_IDCM 0;
BA_ "GenSigTimeoutTime_IDCM" SG_ 2651930749 Digit_01_IDCM 0;
BA_ "GenSigTimeoutTime_BPCM" SG_ 2651930749 Digit_01_IDCM 0;
BA_ "GenSigSendType" SG_ 2651930749 Digit_01_IDCM 1;
BA_ "GenSigTimeoutTime_EVCU2" SG_ 2651930749 Digit_01_IDCM 0;
BA_ "GenSigTimeoutTime_PPIM" SG_ 2651930749 Digit_01_IDCM 0;
BA_ "GenSigTimeoutTime_HCP" SG_ 2651930749 Digit_01_IDCM 0;
BA_ "GenSigTimeoutTime_SGW" SG_ 2651930694 Digit_11_BPCM 0;
BA_ "GenSigTimeoutTime_IDCM" SG_ 2651930694 Digit_11_BPCM 0;
BA_ "GenSigTimeoutTime_BPCM" SG_ 2651930694 Digit_11_BPCM 0;
BA_ "GenSigTimeoutTime_PPIM" SG_ 2651930694 Digit_11_BPCM 0;
BA_ "GenSigTimeoutTime_SGW" SG_ 2651930694 Digit_10_BPCM 0;
BA_ "GenSigTimeoutTime_IDCM" SG_ 2651930694 Digit_10_BPCM 0;
BA_ "GenSigTimeoutTime_BPCM" SG_ 2651930694 Digit_10_BPCM 0;
BA_ "GenSigTimeoutTime_PPIM" SG_ 2651930694 Digit_10_BPCM 0;
BA_ "GenSigTimeoutTime_SGW" SG_ 2651930694 Digit_09_BPCM 0;
BA_ "GenSigTimeoutTime_IDCM" SG_ 2651930694 Digit_09_BPCM 0;
BA_ "GenSigTimeoutTime_BPCM" SG_ 2651930694 Digit_09_BPCM 0;
BA_ "GenSigTimeoutTime_PPIM" SG_ 2651930694 Digit_09_BPCM 0;
BA_ "GenSigTimeoutTime_SGW" SG_ 2651930694 Digit_08_BPCM 0;
BA_ "GenSigTimeoutTime_IDCM" SG_ 2651930694 Digit_08_BPCM 0;
BA_ "GenSigTimeoutTime_BPCM" SG_ 2651930694 Digit_08_BPCM 0;
BA_ "GenSigTimeoutTime_PPIM" SG_ 2651930694 Digit_08_BPCM 0;
BA_ "GenSigTimeoutTime_SGW" SG_ 2651930694 Digit_07_BPCM 0;
BA_ "GenSigTimeoutTime_IDCM" SG_ 2651930694 Digit_07_BPCM 0;
BA_ "GenSigTimeoutTime_BPCM" SG_ 2651930694 Digit_07_BPCM 0;
BA_ "GenSigTimeoutTime_PPIM" SG_ 2651930694 Digit_07_BPCM 0;
BA_ "GenSigTimeoutTime_SGW" SG_ 2651930694 Digit_06_BPCM 0;
BA_ "GenSigTimeoutTime_IDCM" SG_ 2651930694 Digit_06_BPCM 0;
BA_ "GenSigTimeoutTime_BPCM" SG_ 2651930694 Digit_06_BPCM 0;
BA_ "GenSigTimeoutTime_PPIM" SG_ 2651930694 Digit_06_BPCM 0;
BA_ "GenSigTimeoutTime_SGW" SG_ 2651930694 Digit_05_BPCM 0;
BA_ "GenSigTimeoutTime_IDCM" SG_ 2651930694 Digit_05_BPCM 0;
BA_ "GenSigTimeoutTime_BPCM" SG_ 2651930694 Digit_05_BPCM 0;
BA_ "GenSigTimeoutTime_PPIM" SG_ 2651930694 Digit_05_BPCM 0;
BA_ "GenSigTimeoutTime_SGW" SG_ 2651930694 Digit_04_BPCM 0;
BA_ "GenSigTimeoutTime_IDCM" SG_ 2651930694 Digit_04_BPCM 0;
BA_ "GenSigTimeoutTime_BPCM" SG_ 2651930694 Digit_04_BPCM 0;
BA_ "GenSigTimeoutTime_PPIM" SG_ 2651930694 Digit_04_BPCM 0;
BA_ "GenSigTimeoutTime_SGW" SG_ 2651930694 Digit_03_BPCM 0;
BA_ "GenSigTimeoutTime_IDCM" SG_ 2651930694 Digit_03_BPCM 0;
BA_ "GenSigTimeoutTime_BPCM" SG_ 2651930694 Digit_03_BPCM 0;
BA_ "GenSigTimeoutTime_PPIM" SG_ 2651930694 Digit_03_BPCM 0;
BA_ "GenSigTimeoutTime_PPIM" SG_ 2651930694 Digit_02_BPCM 0;
BA_ "GenSigTimeoutTime_SGW" SG_ 2651930694 Digit_02_BPCM 0;
BA_ "GenSigTimeoutTime_IDCM" SG_ 2651930694 Digit_02_BPCM 0;
BA_ "GenSigTimeoutTime_BPCM" SG_ 2651930694 Digit_02_BPCM 0;
BA_ "GenSigTimeoutTime_PPIM" SG_ 2651930694 Digit_01_BPCM 0;
BA_ "GenSigTimeoutTime_SGW" SG_ 2651930694 Digit_01_BPCM 0;
BA_ "GenSigTimeoutTime_IDCM" SG_ 2651930694 Digit_01_BPCM 0;
BA_ "GenSigTimeoutTime_BPCM" SG_ 2651930694 Digit_01_BPCM 0;
BA_ "GenSigSendType" SG_ 2651930694 Digit_01_BPCM 1;
BA_ "GenSigTimeoutTime_IDCM" SG_ 2654339170 GenericFailSts_FD03_HCP 0;
BA_ "GenSigTimeoutTime_EVCU2" SG_ 2654339170 GenericFailSts_FD03_HCP 0;
BA_ "GenSigTimeoutTime_BPCM" SG_ 2654339170 GenericFailSts_FD03_HCP 0;
BA_ "GenSigTimeoutTime_PPIM" SG_ 2654339170 GenericFailSts_FD03_HCP 0;
BA_ "GenSigTimeoutTime_HCP" SG_ 2654339170 GenericFailSts_FD03_HCP 0;
BA_ "GenSigTimeoutTime_IDCM" SG_ 2654339170 EOL_FD03_HCP 0;
BA_ "GenSigTimeoutTime_EVCU2" SG_ 2654339170 EOL_FD03_HCP 0;
BA_ "GenSigTimeoutTime_BPCM" SG_ 2654339170 EOL_FD03_HCP 0;
BA_ "GenSigTimeoutTime_PPIM" SG_ 2654339170 EOL_FD03_HCP 0;
BA_ "GenSigTimeoutTime_HCP" SG_ 2654339170 EOL_FD03_HCP 0;
BA_ "GenSigTimeoutTime_IDCM" SG_ 2654339170 CurrentFailSts_FD03_HCP 0;
BA_ "GenSigTimeoutTime_EVCU2" SG_ 2654339170 CurrentFailSts_FD03_HCP 0;
BA_ "GenSigTimeoutTime_BPCM" SG_ 2654339170 CurrentFailSts_FD03_HCP 0;
BA_ "GenSigTimeoutTime_PPIM" SG_ 2654339170 CurrentFailSts_FD03_HCP 0;
BA_ "GenSigTimeoutTime_HCP" SG_ 2654339170 CurrentFailSts_FD03_HCP 0;
BA_ "GenSigTimeoutTime_IDCM" SG_ 2654339170 WakeupSource_FD03_HCP 0;
BA_ "GenSigTimeoutTime_EVCU2" SG_ 2654339170 WakeupSource_FD03_HCP 0;
BA_ "GenSigTimeoutTime_BPCM" SG_ 2654339170 WakeupSource_FD03_HCP 0;
BA_ "GenSigTimeoutTime_PPIM" SG_ 2654339170 WakeupSource_FD03_HCP 0;
BA_ "GenSigTimeoutTime_HCP" SG_ 2654339170 WakeupSource_FD03_HCP 0;
BA_ "GenSigTimeoutTime_IDCM" SG_ 2654339170 PreviousCanNMState_FD03_HCP 0;
BA_ "GenSigTimeoutTime_EVCU2" SG_ 2654339170 PreviousCanNMState_FD03_HCP 0;
BA_ "GenSigTimeoutTime_BPCM" SG_ 2654339170 PreviousCanNMState_FD03_HCP 0;
BA_ "GenSigTimeoutTime_PPIM" SG_ 2654339170 PreviousCanNMState_FD03_HCP 0;
BA_ "GenSigTimeoutTime_HCP" SG_ 2654339170 PreviousCanNMState_FD03_HCP 0;
BA_ "GenSigTimeoutTime_IDCM" SG_ 2654339170 DES_FD03_HCP 0;
BA_ "GenSigTimeoutTime_EVCU2" SG_ 2654339170 DES_FD03_HCP 0;
BA_ "GenSigTimeoutTime_BPCM" SG_ 2654339170 DES_FD03_HCP 0;
BA_ "GenSigTimeoutTime_PPIM" SG_ 2654339170 DES_FD03_HCP 0;
BA_ "GenSigTimeoutTime_HCP" SG_ 2654339170 DES_FD03_HCP 0;
BA_ "GenSigTimeoutTime_IDCM" SG_ 2654339170 CurrentCanNMState_FD03_HCP 0;
BA_ "GenSigTimeoutTime_EVCU2" SG_ 2654339170 CurrentCanNMState_FD03_HCP 0;
BA_ "GenSigTimeoutTime_BPCM" SG_ 2654339170 CurrentCanNMState_FD03_HCP 0;
BA_ "GenSigTimeoutTime_PPIM" SG_ 2654339170 CurrentCanNMState_FD03_HCP 0;
BA_ "GenSigTimeoutTime_HCP" SG_ 2654339170 CurrentCanNMState_FD03_HCP 0;
BA_ "GenSigTimeoutTime_IDCM" SG_ 2654339170 StayActiveSource_FD03_HCP 0;
BA_ "GenSigTimeoutTime_EVCU2" SG_ 2654339170 StayActiveSource_FD03_HCP 0;
BA_ "GenSigTimeoutTime_BPCM" SG_ 2654339170 StayActiveSource_FD03_HCP 0;
BA_ "GenSigTimeoutTime_PPIM" SG_ 2654339170 StayActiveSource_FD03_HCP 0;
BA_ "GenSigTimeoutTime_HCP" SG_ 2654339170 StayActiveSource_FD03_HCP 0;
BA_ "GenSigTimeoutTime_IDCM" SG_ 1845 HVBatSerialLength 0;
BA_ "GenSigTimeoutTime_EVCU2" SG_ 1845 HVBatSerialLength 0;
BA_ "GenSigTimeoutTime_BPCM" SG_ 1845 HVBatSerialLength 0;
BA_ "GenSigTimeoutTime_IDCM" SG_ 1845 HVBatSerialNumber 0;
BA_ "GenSigTimeoutTime_EVCU2" SG_ 1845 HVBatSerialNumber 0;
BA_ "GenSigTimeoutTime_BPCM" SG_ 1845 HVBatSerialNumber 0;
BA_ "GenSigTimeoutTime_SGW" SG_ 1460 FOTA_Status 0;
BA_ "GenSigSendType" SG_ 1460 FOTA_Status 3;
BA_ "GenSigTimeoutTime_PPIM" SG_ 1460 FOTA_Status 0;
BA_ "GenSigTimeoutTime_HCP" SG_ 1460 FOTA_Status 0;
BA_ "GenSigTimeoutTime_SGW" SG_ 1374 HVBatPackVoltage_MaxAllowedV 0;
BA_ "GenSigTimeoutTime_IDCM" SG_ 1374 HVBatPackVoltage_MaxAllowedV 0;
BA_ "GenSigTimeoutTime_EVCU2" SG_ 1374 HVBatPackVoltage_MaxAllowedV 0;
BA_ "GenSigTimeoutTime_BPCM" SG_ 1374 HVBatPackVoltage_MaxAllowedV 0;
BA_ "GenSigTimeoutTime_PPIM" SG_ 1374 HVBatPackVoltage_MaxAllowedV 0;
BA_ "GenSigTimeoutTime_SGW" SG_ 1374 HVBatCellVoltage_MinAllowedV 0;
BA_ "GenSigTimeoutTime_IDCM" SG_ 1374 HVBatCellVoltage_MinAllowedV 0;
BA_ "GenSigTimeoutTime_EVCU2" SG_ 1374 HVBatCellVoltage_MinAllowedV 0;
BA_ "GenSigTimeoutTime_BPCM" SG_ 1374 HVBatCellVoltage_MinAllowedV 0;
BA_ "GenSigTimeoutTime_PPIM" SG_ 1374 HVBatCellVoltage_MinAllowedV 0;
BA_ "GenSigTimeoutTime_SGW" SG_ 1374 HVBatCellVoltage_MinAllowed 0;
BA_ "GenSigTimeoutTime_IDCM" SG_ 1374 HVBatCellVoltage_MinAllowed 0;
BA_ "GenSigTimeoutTime_EVCU2" SG_ 1374 HVBatCellVoltage_MinAllowed 0;
BA_ "GenSigTimeoutTime_BPCM" SG_ 1374 HVBatCellVoltage_MinAllowed 0;
BA_ "GenSigTimeoutTime_PPIM" SG_ 1374 HVBatCellVoltage_MinAllowed 0;
BA_ "GenSigTimeoutTime_SGW" SG_ 1374 HVBatCellVoltage_MaxAllowedV 0;
BA_ "GenSigTimeoutTime_IDCM" SG_ 1374 HVBatCellVoltage_MaxAllowedV 0;
BA_ "GenSigTimeoutTime_EVCU2" SG_ 1374 HVBatCellVoltage_MaxAllowedV 0;
BA_ "GenSigTimeoutTime_BPCM" SG_ 1374 HVBatCellVoltage_MaxAllowedV 0;
BA_ "GenSigTimeoutTime_PPIM" SG_ 1374 HVBatCellVoltage_MaxAllowedV 0;
BA_ "GenSigTimeoutTime_SGW" SG_ 1374 HVBatCellVoltage_MaxAllowed 0;
BA_ "GenSigTimeoutTime_IDCM" SG_ 1374 HVBatCellVoltage_MaxAllowed 0;
BA_ "GenSigTimeoutTime_EVCU2" SG_ 1374 HVBatCellVoltage_MaxAllowed 0;
BA_ "GenSigTimeoutTime_BPCM" SG_ 1374 HVBatCellVoltage_MaxAllowed 0;
BA_ "GenSigTimeoutTime_PPIM" SG_ 1374 HVBatCellVoltage_MaxAllowed 0;
BA_ "GenSigTimeoutTime_SGW" SG_ 1374 HVBatCellVoltage_LowThreshold 0;
BA_ "GenSigTimeoutTime_IDCM" SG_ 1374 HVBatCellVoltage_LowThreshold 0;
BA_ "GenSigTimeoutTime_EVCU2" SG_ 1374 HVBatCellVoltage_LowThreshold 0;
BA_ "GenSigTimeoutTime_BPCM" SG_ 1374 HVBatCellVoltage_LowThreshold 0;
BA_ "GenSigTimeoutTime_PPIM" SG_ 1374 HVBatCellVoltage_LowThreshold 0;
BA_ "GenSigTimeoutTime_SGW" SG_ 1374 HVBatCellVoltage_HighThreshold 0;
BA_ "GenSigTimeoutTime_IDCM" SG_ 1374 HVBatCellVoltage_HighThreshold 0;
BA_ "GenSigTimeoutTime_EVCU2" SG_ 1374 HVBatCellVoltage_HighThreshold 0;
BA_ "GenSigTimeoutTime_BPCM" SG_ 1374 HVBatCellVoltage_HighThreshold 0;
BA_ "GenSigTimeoutTime_PPIM" SG_ 1374 HVBatCellVoltage_HighThreshold 0;
BA_ "GenSigTimeoutTime_SGW" SG_ 1374 HVBatCapacity_AmpHrV 0;
BA_ "GenSigTimeoutTime_IDCM" SG_ 1374 HVBatCapacity_AmpHrV 0;
BA_ "GenSigTimeoutTime_EVCU2" SG_ 1374 HVBatCapacity_AmpHrV 0;
BA_ "GenSigTimeoutTime_BPCM" SG_ 1374 HVBatCapacity_AmpHrV 0;
BA_ "GenSigTimeoutTime_PPIM" SG_ 1374 HVBatCapacity_AmpHrV 0;
BA_ "GenSigTimeoutTime_HCP" SG_ 1374 HVBatCapacity_AmpHrV 0;
BA_ "GenSigTimeoutTime_SGW" SG_ 1374 HVBatCapacity_AmpHr 0;
BA_ "GenSigTimeoutTime_IDCM" SG_ 1374 HVBatCapacity_AmpHr 0;
BA_ "GenSigTimeoutTime_EVCU2" SG_ 1374 HVBatCapacity_AmpHr 0;
BA_ "GenSigTimeoutTime_BPCM" SG_ 1374 HVBatCapacity_AmpHr 0;
BA_ "GenSigTimeoutTime_PPIM" SG_ 1374 HVBatCapacity_AmpHr 0;
BA_ "GenSigTimeoutTime_HCP" SG_ 1374 HVBatCapacity_AmpHr 0;
BA_ "GenSigTimeoutTime_SGW" SG_ 1374 HVBatRemainingAhCapacity 0;
BA_ "GenSigTimeoutTime_IDCM" SG_ 1374 HVBatRemainingAhCapacity 0;
BA_ "GenSigTimeoutTime_EVCU2" SG_ 1374 HVBatRemainingAhCapacity 0;
BA_ "GenSigTimeoutTime_BPCM" SG_ 1374 HVBatRemainingAhCapacity 0;
BA_ "GenSigTimeoutTime_PPIM" SG_ 1374 HVBatRemainingAhCapacity 0;
BA_ "GenSigTimeoutTime_SGW" SG_ 1374 HVBatDischargeAmpHrs 0;
BA_ "GenSigTimeoutTime_IDCM" SG_ 1374 HVBatDischargeAmpHrs 0;
BA_ "GenSigTimeoutTime_EVCU2" SG_ 1374 HVBatDischargeAmpHrs 0;
BA_ "GenSigTimeoutTime_BPCM" SG_ 1374 HVBatDischargeAmpHrs 0;
BA_ "GenSigTimeoutTime_PPIM" SG_ 1374 HVBatDischargeAmpHrs 0;
BA_ "GenSigTimeoutTime_SGW" SG_ 1374 HVBatChargeAmpHrs 0;
BA_ "GenSigTimeoutTime_IDCM" SG_ 1374 HVBatChargeAmpHrs 0;
BA_ "GenSigTimeoutTime_EVCU2" SG_ 1374 HVBatChargeAmpHrs 0;
BA_ "GenSigTimeoutTime_BPCM" SG_ 1374 HVBatChargeAmpHrs 0;
BA_ "GenSigTimeoutTime_PPIM" SG_ 1374 HVBatChargeAmpHrs 0;
BA_ "GenSigTimeoutTime_SGW" SG_ 1374 BSGPackVoltage_MaxAllowed 0;
BA_ "GenSigTimeoutTime_IDCM" SG_ 1374 BSGPackVoltage_MaxAllowed 0;
BA_ "GenSigTimeoutTime_EVCU2" SG_ 1374 BSGPackVoltage_MaxAllowed 0;
BA_ "GenSigTimeoutTime_BPCM" SG_ 1374 BSGPackVoltage_MaxAllowed 0;
BA_ "GenSigStartValue" SG_ 1374 BSGPackVoltage_MaxAllowed 36;
BA_ "GenSigTimeoutTime_PPIM" SG_ 1374 BSGPackVoltage_MaxAllowed 0;
BA_ "GenSigTimeoutTime_SGW" SG_ 1038 Precharge_Closed 0;
BA_ "GenSigTimeoutTime_IDCM" SG_ 1038 Precharge_Closed 0;
BA_ "GenSigTimeoutTime_EVCU2" SG_ 1038 Precharge_Closed 0;
BA_ "GenSigTimeoutTime_BPCM" SG_ 1038 Precharge_Closed 0;
BA_ "GenSigTimeoutTime_PPIM" SG_ 1038 Precharge_Closed 0;
BA_ "GenSigTimeoutTime_SGW" SG_ 1038 Positive_Main_Closed 0;
BA_ "GenSigTimeoutTime_IDCM" SG_ 1038 Positive_Main_Closed 0;
BA_ "GenSigTimeoutTime_EVCU2" SG_ 1038 Positive_Main_Closed 0;
BA_ "GenSigTimeoutTime_BPCM" SG_ 1038 Positive_Main_Closed 0;
BA_ "GenSigTimeoutTime_PPIM" SG_ 1038 Positive_Main_Closed 0;
BA_ "GenSigTimeoutTime_SGW" SG_ 1038 Negative_Main_Closed 0;
BA_ "GenSigTimeoutTime_IDCM" SG_ 1038 Negative_Main_Closed 0;
BA_ "GenSigTimeoutTime_EVCU2" SG_ 1038 Negative_Main_Closed 0;
BA_ "GenSigTimeoutTime_BPCM" SG_ 1038 Negative_Main_Closed 0;
BA_ "GenSigTimeoutTime_PPIM" SG_ 1038 Negative_Main_Closed 0;
BA_ "GenSigTimeoutTime_PPIM" SG_ 1038 HBCO_TempSensorRationality 0;
BA_ "GenSigTimeoutTime_SGW" SG_ 1038 HBCO_TempSensorRationality 0;
BA_ "GenSigTimeoutTime_IDCM" SG_ 1038 HBCO_TempSensorRationality 0;
BA_ "GenSigTimeoutTime_EVCU2" SG_ 1038 HBCO_TempSensorRationality 0;
BA_ "GenSigTimeoutTime_BPCM" SG_ 1038 HBCO_TempSensorRationality 0;
BA_ "GenSigTimeoutTime_SGW" SG_ 1038 HBCO_Sensor_Fault 0;
BA_ "GenSigTimeoutTime_IDCM" SG_ 1038 HBCO_Sensor_Fault 0;
BA_ "GenSigTimeoutTime_EVCU2" SG_ 1038 HBCO_Sensor_Fault 0;
BA_ "GenSigTimeoutTime_BPCM" SG_ 1038 HBCO_Sensor_Fault 0;
BA_ "GenSigTimeoutTime_PPIM" SG_ 1038 HBCO_Sensor_Fault 0;
BA_ "GenSigTimeoutTime_SGW" SG_ 1038 HBCO_PackUndertemp 0;
BA_ "GenSigTimeoutTime_IDCM" SG_ 1038 HBCO_PackUndertemp 0;
BA_ "GenSigTimeoutTime_EVCU2" SG_ 1038 HBCO_PackUndertemp 0;
BA_ "GenSigTimeoutTime_BPCM" SG_ 1038 HBCO_PackUndertemp 0;
BA_ "GenSigTimeoutTime_PPIM" SG_ 1038 HBCO_PackUndertemp 0;
BA_ "GenSigTimeoutTime_SGW" SG_ 1038 HBCO_PackOvertemp 0;
BA_ "GenSigTimeoutTime_IDCM" SG_ 1038 HBCO_PackOvertemp 0;
BA_ "GenSigTimeoutTime_EVCU2" SG_ 1038 HBCO_PackOvertemp 0;
BA_ "GenSigTimeoutTime_BPCM" SG_ 1038 HBCO_PackOvertemp 0;
BA_ "GenSigTimeoutTime_PPIM" SG_ 1038 HBCO_PackOvertemp 0;
BA_ "GenSigTimeoutTime_SGW" SG_ 1038 HBCO_OverCurrent 0;
BA_ "GenSigTimeoutTime_IDCM" SG_ 1038 HBCO_OverCurrent 0;
BA_ "GenSigTimeoutTime_EVCU2" SG_ 1038 HBCO_OverCurrent 0;
BA_ "GenSigTimeoutTime_BPCM" SG_ 1038 HBCO_OverCurrent 0;
BA_ "GenSigTimeoutTime_PPIM" SG_ 1038 HBCO_OverCurrent 0;
BA_ "GenSigTimeoutTime_SGW" SG_ 1038 HBCO_Micro_Failure 0;
BA_ "GenSigTimeoutTime_IDCM" SG_ 1038 HBCO_Micro_Failure 0;
BA_ "GenSigTimeoutTime_EVCU2" SG_ 1038 HBCO_Micro_Failure 0;
BA_ "GenSigTimeoutTime_BPCM" SG_ 1038 HBCO_Micro_Failure 0;
BA_ "GenSigTimeoutTime_PPIM" SG_ 1038 HBCO_Micro_Failure 0;
BA_ "GenSigTimeoutTime_SGW" SG_ 1038 HBCO_Main_Fuse_Failure 0;
BA_ "GenSigTimeoutTime_IDCM" SG_ 1038 HBCO_Main_Fuse_Failure 0;
BA_ "GenSigTimeoutTime_EVCU2" SG_ 1038 HBCO_Main_Fuse_Failure 0;
BA_ "GenSigTimeoutTime_BPCM" SG_ 1038 HBCO_Main_Fuse_Failure 0;
BA_ "GenSigTimeoutTime_PPIM" SG_ 1038 HBCO_Main_Fuse_Failure 0;
BA_ "GenSigTimeoutTime_SGW" SG_ 1038 HBCO_Isolation_Fault 0;
BA_ "GenSigTimeoutTime_IDCM" SG_ 1038 HBCO_Isolation_Fault 0;
BA_ "GenSigTimeoutTime_EVCU2" SG_ 1038 HBCO_Isolation_Fault 0;
BA_ "GenSigTimeoutTime_BPCM" SG_ 1038 HBCO_Isolation_Fault 0;
BA_ "GenSigTimeoutTime_PPIM" SG_ 1038 HBCO_Isolation_Fault 0;
BA_ "GenSigTimeoutTime_SGW" SG_ 1038 HBCO_Internal_CommFault 0;
BA_ "GenSigTimeoutTime_IDCM" SG_ 1038 HBCO_Internal_CommFault 0;
BA_ "GenSigTimeoutTime_EVCU2" SG_ 1038 HBCO_Internal_CommFault 0;
BA_ "GenSigTimeoutTime_BPCM" SG_ 1038 HBCO_Internal_CommFault 0;
BA_ "GenSigTimeoutTime_PPIM" SG_ 1038 HBCO_Internal_CommFault 0;
BA_ "GenSigTimeoutTime_SGW" SG_ 1038 HBCO_Impact_Detected 0;
BA_ "GenSigTimeoutTime_IDCM" SG_ 1038 HBCO_Impact_Detected 0;
BA_ "GenSigTimeoutTime_EVCU2" SG_ 1038 HBCO_Impact_Detected 0;
BA_ "GenSigTimeoutTime_BPCM" SG_ 1038 HBCO_Impact_Detected 0;
BA_ "GenSigTimeoutTime_PPIM" SG_ 1038 HBCO_Impact_Detected 0;
BA_ "GenSigTimeoutTime_SGW" SG_ 1038 HBCO_HVIL_Failure 0;
BA_ "GenSigTimeoutTime_IDCM" SG_ 1038 HBCO_HVIL_Failure 0;
BA_ "GenSigTimeoutTime_EVCU2" SG_ 1038 HBCO_HVIL_Failure 0;
BA_ "GenSigTimeoutTime_BPCM" SG_ 1038 HBCO_HVIL_Failure 0;
BA_ "GenSigTimeoutTime_PPIM" SG_ 1038 HBCO_HVIL_Failure 0;
BA_ "GenSigTimeoutTime_SGW" SG_ 1038 HBCO_External_CommFault 0;
BA_ "GenSigTimeoutTime_IDCM" SG_ 1038 HBCO_External_CommFault 0;
BA_ "GenSigTimeoutTime_EVCU2" SG_ 1038 HBCO_External_CommFault 0;
BA_ "GenSigTimeoutTime_BPCM" SG_ 1038 HBCO_External_CommFault 0;
BA_ "GenSigTimeoutTime_PPIM" SG_ 1038 HBCO_External_CommFault 0;
BA_ "GenSigTimeoutTime_SGW" SG_ 1038 HBCO_CellUndervoltage 0;
BA_ "GenSigTimeoutTime_IDCM" SG_ 1038 HBCO_CellUndervoltage 0;
BA_ "GenSigTimeoutTime_EVCU2" SG_ 1038 HBCO_CellUndervoltage 0;
BA_ "GenSigTimeoutTime_BPCM" SG_ 1038 HBCO_CellUndervoltage 0;
BA_ "GenSigTimeoutTime_PPIM" SG_ 1038 HBCO_CellUndervoltage 0;
BA_ "GenSigTimeoutTime_SGW" SG_ 1038 HBCO_CellOvervoltage 0;
BA_ "GenSigTimeoutTime_IDCM" SG_ 1038 HBCO_CellOvervoltage 0;
BA_ "GenSigTimeoutTime_EVCU2" SG_ 1038 HBCO_CellOvervoltage 0;
BA_ "GenSigTimeoutTime_BPCM" SG_ 1038 HBCO_CellOvervoltage 0;
BA_ "GenSigTimeoutTime_PPIM" SG_ 1038 HBCO_CellOvervoltage 0;
BA_ "GenSigTimeoutTime_SGW" SG_ 1038 HBCO_12V_Low 0;
BA_ "GenSigTimeoutTime_IDCM" SG_ 1038 HBCO_12V_Low 0;
BA_ "GenSigTimeoutTime_EVCU2" SG_ 1038 HBCO_12V_Low 0;
BA_ "GenSigTimeoutTime_BPCM" SG_ 1038 HBCO_12V_Low 0;
BA_ "GenSigTimeoutTime_PPIM" SG_ 1038 HBCO_12V_Low 0;
BA_ "GenSigTimeoutTime_SGW" SG_ 1038 HBCO_12V_High 0;
BA_ "GenSigTimeoutTime_IDCM" SG_ 1038 HBCO_12V_High 0;
BA_ "GenSigTimeoutTime_EVCU2" SG_ 1038 HBCO_12V_High 0;
BA_ "GenSigTimeoutTime_BPCM" SG_ 1038 HBCO_12V_High 0;
BA_ "GenSigTimeoutTime_PPIM" SG_ 1038 HBCO_12V_High 0;
BA_ "GenSigTimeoutTime_SGW" SG_ 1038 HBCNC_TempSensorRationality 0;
BA_ "GenSigTimeoutTime_IDCM" SG_ 1038 HBCNC_TempSensorRationality 0;
BA_ "GenSigTimeoutTime_EVCU2" SG_ 1038 HBCNC_TempSensorRationality 0;
BA_ "GenSigTimeoutTime_BPCM" SG_ 1038 HBCNC_TempSensorRationality 0;
BA_ "GenSigTimeoutTime_PPIM" SG_ 1038 HBCNC_TempSensorRationality 0;
BA_ "GenSigTimeoutTime_SGW" SG_ 1038 HBCNC_SOH_Failure 0;
BA_ "GenSigTimeoutTime_IDCM" SG_ 1038 HBCNC_SOH_Failure 0;
BA_ "GenSigTimeoutTime_EVCU2" SG_ 1038 HBCNC_SOH_Failure 0;
BA_ "GenSigTimeoutTime_BPCM" SG_ 1038 HBCNC_SOH_Failure 0;
BA_ "GenSigTimeoutTime_PPIM" SG_ 1038 HBCNC_SOH_Failure 0;
BA_ "GenSigTimeoutTime_SGW" SG_ 1038 HBCNC_Sensor_Failure 0;
BA_ "GenSigTimeoutTime_IDCM" SG_ 1038 HBCNC_Sensor_Failure 0;
BA_ "GenSigTimeoutTime_EVCU2" SG_ 1038 HBCNC_Sensor_Failure 0;
BA_ "GenSigTimeoutTime_BPCM" SG_ 1038 HBCNC_Sensor_Failure 0;
BA_ "GenSigTimeoutTime_PPIM" SG_ 1038 HBCNC_Sensor_Failure 0;
BA_ "GenSigTimeoutTime_SGW" SG_ 1038 HBCNC_Precharge_Failure 0;
BA_ "GenSigTimeoutTime_IDCM" SG_ 1038 HBCNC_Precharge_Failure 0;
BA_ "GenSigTimeoutTime_EVCU2" SG_ 1038 HBCNC_Precharge_Failure 0;
BA_ "GenSigTimeoutTime_BPCM" SG_ 1038 HBCNC_Precharge_Failure 0;
BA_ "GenSigTimeoutTime_PPIM" SG_ 1038 HBCNC_Precharge_Failure 0;
BA_ "GenSigTimeoutTime_SGW" SG_ 1038 HBCNC_PackUndervoltage 0;
BA_ "GenSigTimeoutTime_IDCM" SG_ 1038 HBCNC_PackUndervoltage 0;
BA_ "GenSigTimeoutTime_EVCU2" SG_ 1038 HBCNC_PackUndervoltage 0;
BA_ "GenSigTimeoutTime_BPCM" SG_ 1038 HBCNC_PackUndervoltage 0;
BA_ "GenSigTimeoutTime_PPIM" SG_ 1038 HBCNC_PackUndervoltage 0;
BA_ "GenSigTimeoutTime_SGW" SG_ 1038 HBCNC_PackUndertemp 0;
BA_ "GenSigTimeoutTime_IDCM" SG_ 1038 HBCNC_PackUndertemp 0;
BA_ "GenSigTimeoutTime_EVCU2" SG_ 1038 HBCNC_PackUndertemp 0;
BA_ "GenSigTimeoutTime_BPCM" SG_ 1038 HBCNC_PackUndertemp 0;
BA_ "GenSigTimeoutTime_PPIM" SG_ 1038 HBCNC_PackUndertemp 0;
BA_ "GenSigTimeoutTime_SGW" SG_ 1038 HBCNC_PackOvervoltage 0;
BA_ "GenSigTimeoutTime_IDCM" SG_ 1038 HBCNC_PackOvervoltage 0;
BA_ "GenSigTimeoutTime_EVCU2" SG_ 1038 HBCNC_PackOvervoltage 0;
BA_ "GenSigTimeoutTime_BPCM" SG_ 1038 HBCNC_PackOvervoltage 0;
BA_ "GenSigTimeoutTime_PPIM" SG_ 1038 HBCNC_PackOvervoltage 0;
BA_ "GenSigTimeoutTime_SGW" SG_ 1038 HBCNC_PackOvertemp 0;
BA_ "GenSigTimeoutTime_IDCM" SG_ 1038 HBCNC_PackOvertemp 0;
BA_ "GenSigTimeoutTime_EVCU2" SG_ 1038 HBCNC_PackOvertemp 0;
BA_ "GenSigTimeoutTime_BPCM" SG_ 1038 HBCNC_PackOvertemp 0;
BA_ "GenSigTimeoutTime_PPIM" SG_ 1038 HBCNC_PackOvertemp 0;
BA_ "GenSigTimeoutTime_SGW" SG_ 1038 HBCNC_Micro_Failure 0;
BA_ "GenSigTimeoutTime_IDCM" SG_ 1038 HBCNC_Micro_Failure 0;
BA_ "GenSigTimeoutTime_EVCU2" SG_ 1038 HBCNC_Micro_Failure 0;
BA_ "GenSigTimeoutTime_BPCM" SG_ 1038 HBCNC_Micro_Failure 0;
BA_ "GenSigTimeoutTime_PPIM" SG_ 1038 HBCNC_Micro_Failure 0;
BA_ "GenSigTimeoutTime_SGW" SG_ 1038 HBCNC_Main_Fuse_Failure 0;
BA_ "GenSigTimeoutTime_IDCM" SG_ 1038 HBCNC_Main_Fuse_Failure 0;
BA_ "GenSigTimeoutTime_EVCU2" SG_ 1038 HBCNC_Main_Fuse_Failure 0;
BA_ "GenSigTimeoutTime_BPCM" SG_ 1038 HBCNC_Main_Fuse_Failure 0;
BA_ "GenSigTimeoutTime_PPIM" SG_ 1038 HBCNC_Main_Fuse_Failure 0;
BA_ "GenSigTimeoutTime_SGW" SG_ 1038 HBCNC_Isolation_Fault 0;
BA_ "GenSigTimeoutTime_IDCM" SG_ 1038 HBCNC_Isolation_Fault 0;
BA_ "GenSigTimeoutTime_EVCU2" SG_ 1038 HBCNC_Isolation_Fault 0;
BA_ "GenSigTimeoutTime_BPCM" SG_ 1038 HBCNC_Isolation_Fault 0;
BA_ "GenSigTimeoutTime_PPIM" SG_ 1038 HBCNC_Isolation_Fault 0;
BA_ "GenSigTimeoutTime_SGW" SG_ 1038 HBCNC_Internal_CommFault 0;
BA_ "GenSigTimeoutTime_IDCM" SG_ 1038 HBCNC_Internal_CommFault 0;
BA_ "GenSigTimeoutTime_EVCU2" SG_ 1038 HBCNC_Internal_CommFault 0;
BA_ "GenSigTimeoutTime_BPCM" SG_ 1038 HBCNC_Internal_CommFault 0;
BA_ "GenSigTimeoutTime_PPIM" SG_ 1038 HBCNC_Internal_CommFault 0;
BA_ "GenSigTimeoutTime_SGW" SG_ 1038 HBCNC_Impact_Detected 0;
BA_ "GenSigTimeoutTime_IDCM" SG_ 1038 HBCNC_Impact_Detected 0;
BA_ "GenSigTimeoutTime_EVCU2" SG_ 1038 HBCNC_Impact_Detected 0;
BA_ "GenSigTimeoutTime_BPCM" SG_ 1038 HBCNC_Impact_Detected 0;
BA_ "GenSigTimeoutTime_PPIM" SG_ 1038 HBCNC_Impact_Detected 0;
BA_ "GenSigTimeoutTime_SGW" SG_ 1038 HBCNC_External_CommFault 0;
BA_ "GenSigTimeoutTime_IDCM" SG_ 1038 HBCNC_External_CommFault 0;
BA_ "GenSigTimeoutTime_EVCU2" SG_ 1038 HBCNC_External_CommFault 0;
BA_ "GenSigTimeoutTime_BPCM" SG_ 1038 HBCNC_External_CommFault 0;
BA_ "GenSigTimeoutTime_PPIM" SG_ 1038 HBCNC_External_CommFault 0;
BA_ "GenSigTimeoutTime_SGW" SG_ 1038 HBCNC_EEPROM_Fault 0;
BA_ "GenSigTimeoutTime_IDCM" SG_ 1038 HBCNC_EEPROM_Fault 0;
BA_ "GenSigTimeoutTime_EVCU2" SG_ 1038 HBCNC_EEPROM_Fault 0;
BA_ "GenSigTimeoutTime_BPCM" SG_ 1038 HBCNC_EEPROM_Fault 0;
BA_ "GenSigTimeoutTime_PPIM" SG_ 1038 HBCNC_EEPROM_Fault 0;
BA_ "GenSigTimeoutTime_SGW" SG_ 1038 HBCNC_Contactors_Welded 0;
BA_ "GenSigTimeoutTime_IDCM" SG_ 1038 HBCNC_Contactors_Welded 0;
BA_ "GenSigTimeoutTime_EVCU2" SG_ 1038 HBCNC_Contactors_Welded 0;
BA_ "GenSigTimeoutTime_BPCM" SG_ 1038 HBCNC_Contactors_Welded 0;
BA_ "GenSigTimeoutTime_PPIM" SG_ 1038 HBCNC_Contactors_Welded 0;
BA_ "GenSigTimeoutTime_SGW" SG_ 1038 HBCNC_CellUndervoltage 0;
BA_ "GenSigTimeoutTime_IDCM" SG_ 1038 HBCNC_CellUndervoltage 0;
BA_ "GenSigTimeoutTime_EVCU2" SG_ 1038 HBCNC_CellUndervoltage 0;
BA_ "GenSigTimeoutTime_BPCM" SG_ 1038 HBCNC_CellUndervoltage 0;
BA_ "GenSigTimeoutTime_PPIM" SG_ 1038 HBCNC_CellUndervoltage 0;
BA_ "GenSigTimeoutTime_SGW" SG_ 1038 HBCNC_CellOvervoltage 0;
BA_ "GenSigTimeoutTime_IDCM" SG_ 1038 HBCNC_CellOvervoltage 0;
BA_ "GenSigTimeoutTime_EVCU2" SG_ 1038 HBCNC_CellOvervoltage 0;
BA_ "GenSigTimeoutTime_BPCM" SG_ 1038 HBCNC_CellOvervoltage 0;
BA_ "GenSigTimeoutTime_PPIM" SG_ 1038 HBCNC_CellOvervoltage 0;
BA_ "GenSigTimeoutTime_SGW" SG_ 1038 HBCNC_12V_Low 0;
BA_ "GenSigTimeoutTime_IDCM" SG_ 1038 HBCNC_12V_Low 0;
BA_ "GenSigTimeoutTime_EVCU2" SG_ 1038 HBCNC_12V_Low 0;
BA_ "GenSigTimeoutTime_BPCM" SG_ 1038 HBCNC_12V_Low 0;
BA_ "GenSigTimeoutTime_PPIM" SG_ 1038 HBCNC_12V_Low 0;
BA_ "GenSigTimeoutTime_SGW" SG_ 1038 HBCNC_12V_High 0;
BA_ "GenSigTimeoutTime_IDCM" SG_ 1038 HBCNC_12V_High 0;
BA_ "GenSigTimeoutTime_EVCU2" SG_ 1038 HBCNC_12V_High 0;
BA_ "GenSigTimeoutTime_BPCM" SG_ 1038 HBCNC_12V_High 0;
BA_ "GenSigTimeoutTime_PPIM" SG_ 1038 HBCNC_12V_High 0;
BA_ "GenSigTimeoutTime_SGW" SG_ 1038 BPCM_DTC_Status6 0;
BA_ "GenSigTimeoutTime_IDCM" SG_ 1038 BPCM_DTC_Status6 0;
BA_ "GenSigTimeoutTime_EVCU2" SG_ 1038 BPCM_DTC_Status6 0;
BA_ "GenSigTimeoutTime_BPCM" SG_ 1038 BPCM_DTC_Status6 0;
BA_ "GenSigTimeoutTime_PPIM" SG_ 1038 BPCM_DTC_Status6 0;
BA_ "GenSigTimeoutTime_SGW" SG_ 1038 BPCM_DTC_Status5 0;
BA_ "GenSigTimeoutTime_IDCM" SG_ 1038 BPCM_DTC_Status5 0;
BA_ "GenSigTimeoutTime_EVCU2" SG_ 1038 BPCM_DTC_Status5 0;
BA_ "GenSigTimeoutTime_BPCM" SG_ 1038 BPCM_DTC_Status5 0;
BA_ "GenSigTimeoutTime_PPIM" SG_ 1038 BPCM_DTC_Status5 0;
BA_ "GenSigTimeoutTime_SGW" SG_ 1038 BPCM_DTC_Status4 0;
BA_ "GenSigTimeoutTime_IDCM" SG_ 1038 BPCM_DTC_Status4 0;
BA_ "GenSigTimeoutTime_EVCU2" SG_ 1038 BPCM_DTC_Status4 0;
BA_ "GenSigTimeoutTime_BPCM" SG_ 1038 BPCM_DTC_Status4 0;
BA_ "GenSigTimeoutTime_PPIM" SG_ 1038 BPCM_DTC_Status4 0;
BA_ "GenSigTimeoutTime_SGW" SG_ 1038 BPCM_DTC_Status3 0;
BA_ "GenSigTimeoutTime_IDCM" SG_ 1038 BPCM_DTC_Status3 0;
BA_ "GenSigTimeoutTime_EVCU2" SG_ 1038 BPCM_DTC_Status3 0;
BA_ "GenSigTimeoutTime_BPCM" SG_ 1038 BPCM_DTC_Status3 0;
BA_ "GenSigTimeoutTime_PPIM" SG_ 1038 BPCM_DTC_Status3 0;
BA_ "GenSigTimeoutTime_SGW" SG_ 1038 BPCM_DTC_Status2 0;
BA_ "GenSigTimeoutTime_IDCM" SG_ 1038 BPCM_DTC_Status2 0;
BA_ "GenSigTimeoutTime_EVCU2" SG_ 1038 BPCM_DTC_Status2 0;
BA_ "GenSigTimeoutTime_BPCM" SG_ 1038 BPCM_DTC_Status2 0;
BA_ "GenSigTimeoutTime_PPIM" SG_ 1038 BPCM_DTC_Status2 0;
BA_ "GenSigTimeoutTime_SGW" SG_ 1038 BPCM_DTC_Status1 0;
BA_ "GenSigTimeoutTime_IDCM" SG_ 1038 BPCM_DTC_Status1 0;
BA_ "GenSigTimeoutTime_EVCU2" SG_ 1038 BPCM_DTC_Status1 0;
BA_ "GenSigTimeoutTime_BPCM" SG_ 1038 BPCM_DTC_Status1 0;
BA_ "GenSigTimeoutTime_PPIM" SG_ 1038 BPCM_DTC_Status1 0;
BA_ "GenSigTimeoutTime_SGW" SG_ 1038 BPCM_DTC_Index6 0;
BA_ "GenSigTimeoutTime_IDCM" SG_ 1038 BPCM_DTC_Index6 0;
BA_ "GenSigTimeoutTime_EVCU2" SG_ 1038 BPCM_DTC_Index6 0;
BA_ "GenSigTimeoutTime_BPCM" SG_ 1038 BPCM_DTC_Index6 0;
BA_ "GenSigTimeoutTime_PPIM" SG_ 1038 BPCM_DTC_Index6 0;
BA_ "GenSigTimeoutTime_SGW" SG_ 1038 BPCM_DTC_Index5 0;
BA_ "GenSigTimeoutTime_IDCM" SG_ 1038 BPCM_DTC_Index5 0;
BA_ "GenSigTimeoutTime_EVCU2" SG_ 1038 BPCM_DTC_Index5 0;
BA_ "GenSigTimeoutTime_BPCM" SG_ 1038 BPCM_DTC_Index5 0;
BA_ "GenSigTimeoutTime_PPIM" SG_ 1038 BPCM_DTC_Index5 0;
BA_ "GenSigTimeoutTime_SGW" SG_ 1038 BPCM_DTC_Index4 0;
BA_ "GenSigTimeoutTime_IDCM" SG_ 1038 BPCM_DTC_Index4 0;
BA_ "GenSigTimeoutTime_EVCU2" SG_ 1038 BPCM_DTC_Index4 0;
BA_ "GenSigTimeoutTime_BPCM" SG_ 1038 BPCM_DTC_Index4 0;
BA_ "GenSigTimeoutTime_PPIM" SG_ 1038 BPCM_DTC_Index4 0;
BA_ "GenSigTimeoutTime_SGW" SG_ 1038 BPCM_DTC_Index3 0;
BA_ "GenSigTimeoutTime_IDCM" SG_ 1038 BPCM_DTC_Index3 0;
BA_ "GenSigTimeoutTime_EVCU2" SG_ 1038 BPCM_DTC_Index3 0;
BA_ "GenSigTimeoutTime_BPCM" SG_ 1038 BPCM_DTC_Index3 0;
BA_ "GenSigTimeoutTime_PPIM" SG_ 1038 BPCM_DTC_Index3 0;
BA_ "GenSigTimeoutTime_SGW" SG_ 1038 BPCM_DTC_Index2 0;
BA_ "GenSigTimeoutTime_IDCM" SG_ 1038 BPCM_DTC_Index2 0;
BA_ "GenSigTimeoutTime_EVCU2" SG_ 1038 BPCM_DTC_Index2 0;
BA_ "GenSigTimeoutTime_BPCM" SG_ 1038 BPCM_DTC_Index2 0;
BA_ "GenSigTimeoutTime_PPIM" SG_ 1038 BPCM_DTC_Index2 0;
BA_ "GenSigTimeoutTime_SGW" SG_ 1038 BPCM_DTC_Index1 0;
BA_ "GenSigTimeoutTime_IDCM" SG_ 1038 BPCM_DTC_Index1 0;
BA_ "GenSigTimeoutTime_EVCU2" SG_ 1038 BPCM_DTC_Index1 0;
BA_ "GenSigTimeoutTime_BPCM" SG_ 1038 BPCM_DTC_Index1 0;
BA_ "GenSigTimeoutTime_PPIM" SG_ 1038 BPCM_DTC_Index1 0;
BA_ "GenSigTimeoutTime_SGW" SG_ 1038 BPCM_CalibrationVN 0;
BA_ "GenSigTimeoutTime_IDCM" SG_ 1038 BPCM_CalibrationVN 0;
BA_ "GenSigTimeoutTime_EVCU2" SG_ 1038 BPCM_CalibrationVN 0;
BA_ "GenSigTimeoutTime_BPCM" SG_ 1038 BPCM_CalibrationVN 0;
BA_ "GenSigTimeoutTime_PPIM" SG_ 1038 BPCM_CalibrationVN 0;
BA_ "GenSigTimeoutTime_SGW" SG_ 1038 BPCM_CalibrationID 0;
BA_ "GenSigTimeoutTime_IDCM" SG_ 1038 BPCM_CalibrationID 0;
BA_ "GenSigTimeoutTime_EVCU2" SG_ 1038 BPCM_CalibrationID 0;
BA_ "GenSigTimeoutTime_BPCM" SG_ 1038 BPCM_CalibrationID 0;
BA_ "GenSigStartValue" SG_ 1038 BPCM_CalibrationID 63;
BA_ "GenSigTimeoutTime_PPIM" SG_ 1038 BPCM_CalibrationID 0;
BA_ "GenSigTimeoutTime_SGW" SG_ 1038 BPCM_Odometer 0;
BA_ "GenSigTimeoutTime_IDCM" SG_ 1038 BPCM_Odometer 0;
BA_ "GenSigTimeoutTime_EVCU2" SG_ 1038 BPCM_Odometer 0;
BA_ "GenSigTimeoutTime_BPCM" SG_ 1038 BPCM_Odometer 0;
BA_ "GenSigTimeoutTime_PPIM" SG_ 1038 BPCM_Odometer 0;
BA_ "GenSigTimeoutTime_SGW" SG_ 1852 HVBatCellVoltage_Cell192 0;
BA_ "GenSigTimeoutTime_IDCM" SG_ 1852 HVBatCellVoltage_Cell192 0;
BA_ "GenSigTimeoutTime_EVCU2" SG_ 1852 HVBatCellVoltage_Cell192 0;
BA_ "GenSigTimeoutTime_BPCM" SG_ 1852 HVBatCellVoltage_Cell192 0;
BA_ "GenSigTimeoutTime_SGW" SG_ 1852 HVBatCellVoltage_Cell191 0;
BA_ "GenSigTimeoutTime_IDCM" SG_ 1852 HVBatCellVoltage_Cell191 0;
BA_ "GenSigTimeoutTime_EVCU2" SG_ 1852 HVBatCellVoltage_Cell191 0;
BA_ "GenSigTimeoutTime_BPCM" SG_ 1852 HVBatCellVoltage_Cell191 0;
BA_ "GenSigTimeoutTime_BPCM" SG_ 1852 HVBatCellVoltage_Cell190 0;
BA_ "GenSigTimeoutTime_SGW" SG_ 1852 HVBatCellVoltage_Cell190 0;
BA_ "GenSigTimeoutTime_IDCM" SG_ 1852 HVBatCellVoltage_Cell190 0;
BA_ "GenSigTimeoutTime_EVCU2" SG_ 1852 HVBatCellVoltage_Cell190 0;
BA_ "GenSigTimeoutTime_IDCM" SG_ 1852 HVBatCellVoltage_Cell216 0;
BA_ "GenSigTimeoutTime_EVCU2" SG_ 1852 HVBatCellVoltage_Cell216 0;
BA_ "GenSigTimeoutTime_BPCM" SG_ 1852 HVBatCellVoltage_Cell216 0;
BA_ "GenSigTimeoutTime_SGW" SG_ 1852 HVBatCellVoltage_Cell215 0;
BA_ "GenSigTimeoutTime_IDCM" SG_ 1852 HVBatCellVoltage_Cell215 0;
BA_ "GenSigTimeoutTime_EVCU2" SG_ 1852 HVBatCellVoltage_Cell215 0;
BA_ "GenSigTimeoutTime_BPCM" SG_ 1852 HVBatCellVoltage_Cell215 0;
BA_ "GenSigTimeoutTime_SGW" SG_ 1852 HVBatCellVoltage_Cell214 0;
BA_ "GenSigTimeoutTime_IDCM" SG_ 1852 HVBatCellVoltage_Cell214 0;
BA_ "GenSigTimeoutTime_EVCU2" SG_ 1852 HVBatCellVoltage_Cell214 0;
BA_ "GenSigTimeoutTime_BPCM" SG_ 1852 HVBatCellVoltage_Cell214 0;
BA_ "GenSigTimeoutTime_SGW" SG_ 1852 HVBatCellVoltage_Cell213 0;
BA_ "GenSigTimeoutTime_IDCM" SG_ 1852 HVBatCellVoltage_Cell213 0;
BA_ "GenSigTimeoutTime_EVCU2" SG_ 1852 HVBatCellVoltage_Cell213 0;
BA_ "GenSigTimeoutTime_BPCM" SG_ 1852 HVBatCellVoltage_Cell213 0;
BA_ "GenSigTimeoutTime_SGW" SG_ 1852 HVBatCellVoltage_Cell212 0;
BA_ "GenSigTimeoutTime_IDCM" SG_ 1852 HVBatCellVoltage_Cell212 0;
BA_ "GenSigTimeoutTime_EVCU2" SG_ 1852 HVBatCellVoltage_Cell212 0;
BA_ "GenSigTimeoutTime_BPCM" SG_ 1852 HVBatCellVoltage_Cell212 0;
BA_ "GenSigTimeoutTime_SGW" SG_ 1852 HVBatCellVoltage_Cell211 0;
BA_ "GenSigTimeoutTime_IDCM" SG_ 1852 HVBatCellVoltage_Cell211 0;
BA_ "GenSigTimeoutTime_EVCU2" SG_ 1852 HVBatCellVoltage_Cell211 0;
BA_ "GenSigTimeoutTime_BPCM" SG_ 1852 HVBatCellVoltage_Cell211 0;
BA_ "GenSigTimeoutTime_SGW" SG_ 1852 HVBatCellVoltage_Cell210 0;
BA_ "GenSigTimeoutTime_IDCM" SG_ 1852 HVBatCellVoltage_Cell210 0;
BA_ "GenSigTimeoutTime_EVCU2" SG_ 1852 HVBatCellVoltage_Cell210 0;
BA_ "GenSigTimeoutTime_BPCM" SG_ 1852 HVBatCellVoltage_Cell210 0;
BA_ "GenSigTimeoutTime_SGW" SG_ 1852 HVBatCellVoltage_Cell209 0;
BA_ "GenSigTimeoutTime_IDCM" SG_ 1852 HVBatCellVoltage_Cell209 0;
BA_ "GenSigTimeoutTime_EVCU2" SG_ 1852 HVBatCellVoltage_Cell209 0;
BA_ "GenSigTimeoutTime_BPCM" SG_ 1852 HVBatCellVoltage_Cell209 0;
BA_ "GenSigTimeoutTime_SGW" SG_ 1852 HVBatCellVoltage_Cell208 0;
BA_ "GenSigTimeoutTime_IDCM" SG_ 1852 HVBatCellVoltage_Cell208 0;
BA_ "GenSigTimeoutTime_EVCU2" SG_ 1852 HVBatCellVoltage_Cell208 0;
BA_ "GenSigTimeoutTime_BPCM" SG_ 1852 HVBatCellVoltage_Cell208 0;
BA_ "GenSigTimeoutTime_SGW" SG_ 1852 HVBatCellVoltage_Cell207 0;
BA_ "GenSigTimeoutTime_IDCM" SG_ 1852 HVBatCellVoltage_Cell207 0;
BA_ "GenSigTimeoutTime_EVCU2" SG_ 1852 HVBatCellVoltage_Cell207 0;
BA_ "GenSigTimeoutTime_BPCM" SG_ 1852 HVBatCellVoltage_Cell207 0;
BA_ "GenSigTimeoutTime_SGW" SG_ 1852 HVBatCellVoltage_Cell206 0;
BA_ "GenSigTimeoutTime_IDCM" SG_ 1852 HVBatCellVoltage_Cell206 0;
BA_ "GenSigTimeoutTime_EVCU2" SG_ 1852 HVBatCellVoltage_Cell206 0;
BA_ "GenSigTimeoutTime_BPCM" SG_ 1852 HVBatCellVoltage_Cell206 0;
BA_ "GenSigTimeoutTime_SGW" SG_ 1852 HVBatCellVoltage_Cell205 0;
BA_ "GenSigTimeoutTime_IDCM" SG_ 1852 HVBatCellVoltage_Cell205 0;
BA_ "GenSigTimeoutTime_EVCU2" SG_ 1852 HVBatCellVoltage_Cell205 0;
BA_ "GenSigTimeoutTime_BPCM" SG_ 1852 HVBatCellVoltage_Cell205 0;
BA_ "GenSigTimeoutTime_SGW" SG_ 1852 HVBatCellVoltage_Cell204 0;
BA_ "GenSigTimeoutTime_IDCM" SG_ 1852 HVBatCellVoltage_Cell204 0;
BA_ "GenSigTimeoutTime_EVCU2" SG_ 1852 HVBatCellVoltage_Cell204 0;
BA_ "GenSigTimeoutTime_BPCM" SG_ 1852 HVBatCellVoltage_Cell204 0;
BA_ "GenSigTimeoutTime_SGW" SG_ 1852 HVBatCellVoltage_Cell203 0;
BA_ "GenSigTimeoutTime_IDCM" SG_ 1852 HVBatCellVoltage_Cell203 0;
BA_ "GenSigTimeoutTime_EVCU2" SG_ 1852 HVBatCellVoltage_Cell203 0;
BA_ "GenSigTimeoutTime_BPCM" SG_ 1852 HVBatCellVoltage_Cell203 0;
BA_ "GenSigTimeoutTime_SGW" SG_ 1852 HVBatCellVoltage_Cell202 0;
BA_ "GenSigTimeoutTime_IDCM" SG_ 1852 HVBatCellVoltage_Cell202 0;
BA_ "GenSigTimeoutTime_EVCU2" SG_ 1852 HVBatCellVoltage_Cell202 0;
BA_ "GenSigTimeoutTime_BPCM" SG_ 1852 HVBatCellVoltage_Cell202 0;
BA_ "GenSigTimeoutTime_SGW" SG_ 1852 HVBatCellVoltage_Cell201 0;
BA_ "GenSigTimeoutTime_IDCM" SG_ 1852 HVBatCellVoltage_Cell201 0;
BA_ "GenSigTimeoutTime_EVCU2" SG_ 1852 HVBatCellVoltage_Cell201 0;
BA_ "GenSigTimeoutTime_BPCM" SG_ 1852 HVBatCellVoltage_Cell201 0;
BA_ "GenSigTimeoutTime_SGW" SG_ 1852 HVBatCellVoltage_Cell200 0;
BA_ "GenSigTimeoutTime_IDCM" SG_ 1852 HVBatCellVoltage_Cell200 0;
BA_ "GenSigTimeoutTime_EVCU2" SG_ 1852 HVBatCellVoltage_Cell200 0;
BA_ "GenSigTimeoutTime_BPCM" SG_ 1852 HVBatCellVoltage_Cell200 0;
BA_ "GenSigTimeoutTime_SGW" SG_ 1852 HVBatCellVoltage_Cell198 0;
BA_ "GenSigTimeoutTime_IDCM" SG_ 1852 HVBatCellVoltage_Cell198 0;
BA_ "GenSigTimeoutTime_EVCU2" SG_ 1852 HVBatCellVoltage_Cell198 0;
BA_ "GenSigTimeoutTime_BPCM" SG_ 1852 HVBatCellVoltage_Cell198 0;
BA_ "GenSigTimeoutTime_SGW" SG_ 1852 HVBatCellVoltage_Cell197 0;
BA_ "GenSigTimeoutTime_IDCM" SG_ 1852 HVBatCellVoltage_Cell197 0;
BA_ "GenSigTimeoutTime_EVCU2" SG_ 1852 HVBatCellVoltage_Cell197 0;
BA_ "GenSigTimeoutTime_BPCM" SG_ 1852 HVBatCellVoltage_Cell197 0;
BA_ "GenSigTimeoutTime_SGW" SG_ 1852 HVBatCellVoltage_Cell196 0;
BA_ "GenSigTimeoutTime_IDCM" SG_ 1852 HVBatCellVoltage_Cell196 0;
BA_ "GenSigTimeoutTime_EVCU2" SG_ 1852 HVBatCellVoltage_Cell196 0;
BA_ "GenSigTimeoutTime_BPCM" SG_ 1852 HVBatCellVoltage_Cell196 0;
BA_ "GenSigTimeoutTime_SGW" SG_ 1852 HVBatCellVoltage_Cell195 0;
BA_ "GenSigTimeoutTime_IDCM" SG_ 1852 HVBatCellVoltage_Cell195 0;
BA_ "GenSigTimeoutTime_EVCU2" SG_ 1852 HVBatCellVoltage_Cell195 0;
BA_ "GenSigTimeoutTime_BPCM" SG_ 1852 HVBatCellVoltage_Cell195 0;
BA_ "GenSigTimeoutTime_SGW" SG_ 1852 HVBatCellVoltage_Cell194 0;
BA_ "GenSigTimeoutTime_IDCM" SG_ 1852 HVBatCellVoltage_Cell194 0;
BA_ "GenSigTimeoutTime_EVCU2" SG_ 1852 HVBatCellVoltage_Cell194 0;
BA_ "GenSigTimeoutTime_BPCM" SG_ 1852 HVBatCellVoltage_Cell194 0;
BA_ "GenSigTimeoutTime_SGW" SG_ 1852 HVBatCellVoltage_Cell193 0;
BA_ "GenSigTimeoutTime_IDCM" SG_ 1852 HVBatCellVoltage_Cell193 0;
BA_ "GenSigTimeoutTime_EVCU2" SG_ 1852 HVBatCellVoltage_Cell193 0;
BA_ "GenSigTimeoutTime_BPCM" SG_ 1852 HVBatCellVoltage_Cell193 0;
BA_ "GenSigTimeoutTime_SGW" SG_ 1851 HVBatCellVoltage_Cell189 0;
BA_ "GenSigTimeoutTime_IDCM" SG_ 1851 HVBatCellVoltage_Cell189 0;
BA_ "GenSigTimeoutTime_EVCU2" SG_ 1851 HVBatCellVoltage_Cell189 0;
BA_ "GenSigTimeoutTime_BPCM" SG_ 1851 HVBatCellVoltage_Cell189 0;
BA_ "GenSigTimeoutTime_SGW" SG_ 1851 HVBatCellVoltage_Cell188 0;
BA_ "GenSigTimeoutTime_IDCM" SG_ 1851 HVBatCellVoltage_Cell188 0;
BA_ "GenSigTimeoutTime_EVCU2" SG_ 1851 HVBatCellVoltage_Cell188 0;
BA_ "GenSigTimeoutTime_BPCM" SG_ 1851 HVBatCellVoltage_Cell188 0;
BA_ "GenSigTimeoutTime_SGW" SG_ 1851 HVBatCellVoltage_Cell187 0;
BA_ "GenSigTimeoutTime_IDCM" SG_ 1851 HVBatCellVoltage_Cell187 0;
BA_ "GenSigTimeoutTime_EVCU2" SG_ 1851 HVBatCellVoltage_Cell187 0;
BA_ "GenSigTimeoutTime_BPCM" SG_ 1851 HVBatCellVoltage_Cell187 0;
BA_ "GenSigTimeoutTime_SGW" SG_ 1851 HVBatCellVoltage_Cell186 0;
BA_ "GenSigTimeoutTime_IDCM" SG_ 1851 HVBatCellVoltage_Cell186 0;
BA_ "GenSigTimeoutTime_EVCU2" SG_ 1851 HVBatCellVoltage_Cell186 0;
BA_ "GenSigTimeoutTime_BPCM" SG_ 1851 HVBatCellVoltage_Cell186 0;
BA_ "GenSigTimeoutTime_SGW" SG_ 1851 HVBatCellVoltage_Cell185 0;
BA_ "GenSigTimeoutTime_IDCM" SG_ 1851 HVBatCellVoltage_Cell185 0;
BA_ "GenSigTimeoutTime_EVCU2" SG_ 1851 HVBatCellVoltage_Cell185 0;
BA_ "GenSigTimeoutTime_BPCM" SG_ 1851 HVBatCellVoltage_Cell185 0;
BA_ "GenSigTimeoutTime_SGW" SG_ 1851 HVBatCellVoltage_Cell184 0;
BA_ "GenSigTimeoutTime_IDCM" SG_ 1851 HVBatCellVoltage_Cell184 0;
BA_ "GenSigTimeoutTime_EVCU2" SG_ 1851 HVBatCellVoltage_Cell184 0;
BA_ "GenSigTimeoutTime_BPCM" SG_ 1851 HVBatCellVoltage_Cell184 0;
BA_ "GenSigTimeoutTime_IDCM" SG_ 1851 HVBatCellVoltage_Cell183 0;
BA_ "GenSigTimeoutTime_EVCU2" SG_ 1851 HVBatCellVoltage_Cell183 0;
BA_ "GenSigTimeoutTime_BPCM" SG_ 1851 HVBatCellVoltage_Cell183 0;
BA_ "GenSigTimeoutTime_IDCM" SG_ 1851 HVBatCellVoltage_Cell182 0;
BA_ "GenSigTimeoutTime_EVCU2" SG_ 1851 HVBatCellVoltage_Cell182 0;
BA_ "GenSigTimeoutTime_BPCM" SG_ 1851 HVBatCellVoltage_Cell182 0;
BA_ "GenSigTimeoutTime_IDCM" SG_ 1851 HVBatCellVoltage_Cell181 0;
BA_ "GenSigTimeoutTime_EVCU2" SG_ 1851 HVBatCellVoltage_Cell181 0;
BA_ "GenSigTimeoutTime_BPCM" SG_ 1851 HVBatCellVoltage_Cell181 0;
BA_ "GenSigTimeoutTime_IDCM" SG_ 1851 HVBatCellVoltage_Cell180 0;
BA_ "GenSigTimeoutTime_EVCU2" SG_ 1851 HVBatCellVoltage_Cell180 0;
BA_ "GenSigTimeoutTime_BPCM" SG_ 1851 HVBatCellVoltage_Cell180 0;
BA_ "GenSigTimeoutTime_IDCM" SG_ 1851 HVBatCellVoltage_Cell179 0;
BA_ "GenSigTimeoutTime_EVCU2" SG_ 1851 HVBatCellVoltage_Cell179 0;
BA_ "GenSigTimeoutTime_BPCM" SG_ 1851 HVBatCellVoltage_Cell179 0;
BA_ "GenSigTimeoutTime_IDCM" SG_ 1851 HVBatCellVoltage_Cell178 0;
BA_ "GenSigTimeoutTime_EVCU2" SG_ 1851 HVBatCellVoltage_Cell178 0;
BA_ "GenSigTimeoutTime_BPCM" SG_ 1851 HVBatCellVoltage_Cell178 0;
BA_ "GenSigTimeoutTime_IDCM" SG_ 1851 HVBatCellVoltage_Cell177 0;
BA_ "GenSigTimeoutTime_EVCU2" SG_ 1851 HVBatCellVoltage_Cell177 0;
BA_ "GenSigTimeoutTime_BPCM" SG_ 1851 HVBatCellVoltage_Cell177 0;
BA_ "GenSigTimeoutTime_IDCM" SG_ 1851 HVBatCellVoltage_Cell176 0;
BA_ "GenSigTimeoutTime_EVCU2" SG_ 1851 HVBatCellVoltage_Cell176 0;
BA_ "GenSigTimeoutTime_BPCM" SG_ 1851 HVBatCellVoltage_Cell176 0;
BA_ "GenSigTimeoutTime_IDCM" SG_ 1851 HVBatCellVoltage_Cell175 0;
BA_ "GenSigTimeoutTime_EVCU2" SG_ 1851 HVBatCellVoltage_Cell175 0;
BA_ "GenSigTimeoutTime_BPCM" SG_ 1851 HVBatCellVoltage_Cell175 0;
BA_ "GenSigTimeoutTime_IDCM" SG_ 1851 HVBatCellVoltage_Cell174 0;
BA_ "GenSigTimeoutTime_EVCU2" SG_ 1851 HVBatCellVoltage_Cell174 0;
BA_ "GenSigTimeoutTime_BPCM" SG_ 1851 HVBatCellVoltage_Cell174 0;
BA_ "GenSigTimeoutTime_EVCU2" SG_ 1851 HVBatCellVoltage_Cell173 0;
BA_ "GenSigTimeoutTime_BPCM" SG_ 1851 HVBatCellVoltage_Cell173 0;
BA_ "GenSigTimeoutTime_IDCM" SG_ 1851 HVBatCellVoltage_Cell173 0;
BA_ "GenSigTimeoutTime_IDCM" SG_ 1851 HVBatCellVoltage_Cell172 0;
BA_ "GenSigTimeoutTime_EVCU2" SG_ 1851 HVBatCellVoltage_Cell172 0;
BA_ "GenSigTimeoutTime_BPCM" SG_ 1851 HVBatCellVoltage_Cell172 0;
BA_ "GenSigTimeoutTime_IDCM" SG_ 1851 HVBatCellVoltage_Cell171 0;
BA_ "GenSigTimeoutTime_EVCU2" SG_ 1851 HVBatCellVoltage_Cell171 0;
BA_ "GenSigTimeoutTime_BPCM" SG_ 1851 HVBatCellVoltage_Cell171 0;
BA_ "GenSigTimeoutTime_IDCM" SG_ 1851 HVBatCellVoltage_Cell170 0;
BA_ "GenSigTimeoutTime_EVCU2" SG_ 1851 HVBatCellVoltage_Cell170 0;
BA_ "GenSigTimeoutTime_BPCM" SG_ 1851 HVBatCellVoltage_Cell170 0;
BA_ "GenSigTimeoutTime_IDCM" SG_ 1851 HVBatCellVoltage_Cell169 0;
BA_ "GenSigTimeoutTime_EVCU2" SG_ 1851 HVBatCellVoltage_Cell169 0;
BA_ "GenSigTimeoutTime_BPCM" SG_ 1851 HVBatCellVoltage_Cell169 0;
BA_ "GenSigTimeoutTime_IDCM" SG_ 1851 HVBatCellVoltage_Cell168 0;
BA_ "GenSigTimeoutTime_EVCU2" SG_ 1851 HVBatCellVoltage_Cell168 0;
BA_ "GenSigTimeoutTime_BPCM" SG_ 1851 HVBatCellVoltage_Cell168 0;
BA_ "GenSigTimeoutTime_IDCM" SG_ 1851 HVBatCellVoltage_Cell167 0;
BA_ "GenSigTimeoutTime_EVCU2" SG_ 1851 HVBatCellVoltage_Cell167 0;
BA_ "GenSigTimeoutTime_BPCM" SG_ 1851 HVBatCellVoltage_Cell167 0;
BA_ "GenSigTimeoutTime_IDCM" SG_ 1851 HVBatCellVoltage_Cell166 0;
BA_ "GenSigTimeoutTime_EVCU2" SG_ 1851 HVBatCellVoltage_Cell166 0;
BA_ "GenSigTimeoutTime_BPCM" SG_ 1851 HVBatCellVoltage_Cell166 0;
BA_ "GenSigTimeoutTime_IDCM" SG_ 1851 HVBatCellVoltage_Cell165 0;
BA_ "GenSigTimeoutTime_EVCU2" SG_ 1851 HVBatCellVoltage_Cell165 0;
BA_ "GenSigTimeoutTime_BPCM" SG_ 1851 HVBatCellVoltage_Cell165 0;
BA_ "GenSigTimeoutTime_IDCM" SG_ 1851 HVBatCellVoltage_Cell164 0;
BA_ "GenSigTimeoutTime_EVCU2" SG_ 1851 HVBatCellVoltage_Cell164 0;
BA_ "GenSigTimeoutTime_BPCM" SG_ 1851 HVBatCellVoltage_Cell164 0;
BA_ "GenSigTimeoutTime_IDCM" SG_ 1851 HVBatCellVoltage_Cell163 0;
BA_ "GenSigTimeoutTime_EVCU2" SG_ 1851 HVBatCellVoltage_Cell163 0;
BA_ "GenSigTimeoutTime_BPCM" SG_ 1851 HVBatCellVoltage_Cell163 0;
BA_ "GenSigTimeoutTime_IDCM" SG_ 1850 HVBatCellVoltage_Cell162 0;
BA_ "GenSigTimeoutTime_EVCU2" SG_ 1850 HVBatCellVoltage_Cell162 0;
BA_ "GenSigTimeoutTime_BPCM" SG_ 1850 HVBatCellVoltage_Cell162 0;
BA_ "GenSigTimeoutTime_IDCM" SG_ 1850 HVBatCellVoltage_Cell161 0;
BA_ "GenSigTimeoutTime_EVCU2" SG_ 1850 HVBatCellVoltage_Cell161 0;
BA_ "GenSigTimeoutTime_BPCM" SG_ 1850 HVBatCellVoltage_Cell161 0;
BA_ "GenSigTimeoutTime_IDCM" SG_ 1850 HVBatCellVoltage_Cell160 0;
BA_ "GenSigTimeoutTime_EVCU2" SG_ 1850 HVBatCellVoltage_Cell160 0;
BA_ "GenSigTimeoutTime_BPCM" SG_ 1850 HVBatCellVoltage_Cell160 0;
BA_ "GenSigTimeoutTime_IDCM" SG_ 1850 HVBatCellVoltage_Cell159 0;
BA_ "GenSigTimeoutTime_EVCU2" SG_ 1850 HVBatCellVoltage_Cell159 0;
BA_ "GenSigTimeoutTime_BPCM" SG_ 1850 HVBatCellVoltage_Cell159 0;
BA_ "GenSigTimeoutTime_IDCM" SG_ 1850 HVBatCellVoltage_Cell158 0;
BA_ "GenSigTimeoutTime_EVCU2" SG_ 1850 HVBatCellVoltage_Cell158 0;
BA_ "GenSigTimeoutTime_BPCM" SG_ 1850 HVBatCellVoltage_Cell158 0;
BA_ "GenSigTimeoutTime_IDCM" SG_ 1850 HVBatCellVoltage_Cell157 0;
BA_ "GenSigTimeoutTime_EVCU2" SG_ 1850 HVBatCellVoltage_Cell157 0;
BA_ "GenSigTimeoutTime_BPCM" SG_ 1850 HVBatCellVoltage_Cell157 0;
BA_ "GenSigTimeoutTime_IDCM" SG_ 1850 HVBatCellVoltage_Cell156 0;
BA_ "GenSigTimeoutTime_EVCU2" SG_ 1850 HVBatCellVoltage_Cell156 0;
BA_ "GenSigTimeoutTime_BPCM" SG_ 1850 HVBatCellVoltage_Cell156 0;
BA_ "GenSigTimeoutTime_IDCM" SG_ 1850 HVBatCellVoltage_Cell155 0;
BA_ "GenSigTimeoutTime_EVCU2" SG_ 1850 HVBatCellVoltage_Cell155 0;
BA_ "GenSigTimeoutTime_BPCM" SG_ 1850 HVBatCellVoltage_Cell155 0;
BA_ "GenSigTimeoutTime_IDCM" SG_ 1850 HVBatCellVoltage_Cell154 0;
BA_ "GenSigTimeoutTime_EVCU2" SG_ 1850 HVBatCellVoltage_Cell154 0;
BA_ "GenSigTimeoutTime_BPCM" SG_ 1850 HVBatCellVoltage_Cell154 0;
BA_ "GenSigTimeoutTime_IDCM" SG_ 1850 HVBatCellVoltage_Cell153 0;
BA_ "GenSigTimeoutTime_EVCU2" SG_ 1850 HVBatCellVoltage_Cell153 0;
BA_ "GenSigTimeoutTime_BPCM" SG_ 1850 HVBatCellVoltage_Cell153 0;
BA_ "GenSigTimeoutTime_IDCM" SG_ 1850 HVBatCellVoltage_Cell152 0;
BA_ "GenSigTimeoutTime_EVCU2" SG_ 1850 HVBatCellVoltage_Cell152 0;
BA_ "GenSigTimeoutTime_BPCM" SG_ 1850 HVBatCellVoltage_Cell152 0;
BA_ "GenSigTimeoutTime_IDCM" SG_ 1850 HVBatCellVoltage_Cell151 0;
BA_ "GenSigTimeoutTime_EVCU2" SG_ 1850 HVBatCellVoltage_Cell151 0;
BA_ "GenSigTimeoutTime_BPCM" SG_ 1850 HVBatCellVoltage_Cell151 0;
BA_ "GenSigTimeoutTime_IDCM" SG_ 1850 HVBatCellVoltage_Cell150 0;
BA_ "GenSigTimeoutTime_EVCU2" SG_ 1850 HVBatCellVoltage_Cell150 0;
BA_ "GenSigTimeoutTime_BPCM" SG_ 1850 HVBatCellVoltage_Cell150 0;
BA_ "GenSigTimeoutTime_IDCM" SG_ 1850 HVBatCellVoltage_Cell149 0;
BA_ "GenSigTimeoutTime_EVCU2" SG_ 1850 HVBatCellVoltage_Cell149 0;
BA_ "GenSigTimeoutTime_BPCM" SG_ 1850 HVBatCellVoltage_Cell149 0;
BA_ "GenSigTimeoutTime_IDCM" SG_ 1850 HVBatCellVoltage_Cell148 0;
BA_ "GenSigTimeoutTime_EVCU2" SG_ 1850 HVBatCellVoltage_Cell148 0;
BA_ "GenSigTimeoutTime_BPCM" SG_ 1850 HVBatCellVoltage_Cell148 0;
BA_ "GenSigTimeoutTime_IDCM" SG_ 1850 HVBatCellVoltage_Cell147 0;
BA_ "GenSigTimeoutTime_EVCU2" SG_ 1850 HVBatCellVoltage_Cell147 0;
BA_ "GenSigTimeoutTime_BPCM" SG_ 1850 HVBatCellVoltage_Cell147 0;
BA_ "GenSigTimeoutTime_IDCM" SG_ 1850 HVBatCellVoltage_Cell146 0;
BA_ "GenSigTimeoutTime_EVCU2" SG_ 1850 HVBatCellVoltage_Cell146 0;
BA_ "GenSigTimeoutTime_BPCM" SG_ 1850 HVBatCellVoltage_Cell146 0;
BA_ "GenSigTimeoutTime_IDCM" SG_ 1850 HVBatCellVoltage_Cell145 0;
BA_ "GenSigTimeoutTime_EVCU2" SG_ 1850 HVBatCellVoltage_Cell145 0;
BA_ "GenSigTimeoutTime_BPCM" SG_ 1850 HVBatCellVoltage_Cell145 0;
BA_ "GenSigTimeoutTime_IDCM" SG_ 1850 HVBatCellVoltage_Cell144 0;
BA_ "GenSigTimeoutTime_EVCU2" SG_ 1850 HVBatCellVoltage_Cell144 0;
BA_ "GenSigTimeoutTime_BPCM" SG_ 1850 HVBatCellVoltage_Cell144 0;
BA_ "GenSigTimeoutTime_IDCM" SG_ 1850 HVBatCellVoltage_Cell143 0;
BA_ "GenSigTimeoutTime_EVCU2" SG_ 1850 HVBatCellVoltage_Cell143 0;
BA_ "GenSigTimeoutTime_BPCM" SG_ 1850 HVBatCellVoltage_Cell143 0;
BA_ "GenSigTimeoutTime_IDCM" SG_ 1850 HVBatCellVoltage_Cell142 0;
BA_ "GenSigTimeoutTime_EVCU2" SG_ 1850 HVBatCellVoltage_Cell142 0;
BA_ "GenSigTimeoutTime_BPCM" SG_ 1850 HVBatCellVoltage_Cell142 0;
BA_ "GenSigTimeoutTime_IDCM" SG_ 1850 HVBatCellVoltage_Cell141 0;
BA_ "GenSigTimeoutTime_EVCU2" SG_ 1850 HVBatCellVoltage_Cell141 0;
BA_ "GenSigTimeoutTime_BPCM" SG_ 1850 HVBatCellVoltage_Cell141 0;
BA_ "GenSigTimeoutTime_IDCM" SG_ 1850 HVBatCellVoltage_Cell140 0;
BA_ "GenSigTimeoutTime_EVCU2" SG_ 1850 HVBatCellVoltage_Cell140 0;
BA_ "GenSigTimeoutTime_BPCM" SG_ 1850 HVBatCellVoltage_Cell140 0;
BA_ "GenSigTimeoutTime_IDCM" SG_ 1850 HVBatCellVoltage_Cell139 0;
BA_ "GenSigTimeoutTime_EVCU2" SG_ 1850 HVBatCellVoltage_Cell139 0;
BA_ "GenSigTimeoutTime_BPCM" SG_ 1850 HVBatCellVoltage_Cell139 0;
BA_ "GenSigTimeoutTime_IDCM" SG_ 1850 HVBatCellVoltage_Cell138 0;
BA_ "GenSigTimeoutTime_EVCU2" SG_ 1850 HVBatCellVoltage_Cell138 0;
BA_ "GenSigTimeoutTime_BPCM" SG_ 1850 HVBatCellVoltage_Cell138 0;
BA_ "GenSigTimeoutTime_IDCM" SG_ 1850 HVBatCellVoltage_Cell137 0;
BA_ "GenSigTimeoutTime_EVCU2" SG_ 1850 HVBatCellVoltage_Cell137 0;
BA_ "GenSigTimeoutTime_BPCM" SG_ 1850 HVBatCellVoltage_Cell137 0;
BA_ "GenSigTimeoutTime_IDCM" SG_ 1850 HVBatCellVoltage_Cell136 0;
BA_ "GenSigTimeoutTime_EVCU2" SG_ 1850 HVBatCellVoltage_Cell136 0;
BA_ "GenSigTimeoutTime_BPCM" SG_ 1850 HVBatCellVoltage_Cell136 0;
BA_ "GenSigTimeoutTime_IDCM" SG_ 1849 HVBatCellVoltage_Cell135 0;
BA_ "GenSigTimeoutTime_EVCU2" SG_ 1849 HVBatCellVoltage_Cell135 0;
BA_ "GenSigTimeoutTime_BPCM" SG_ 1849 HVBatCellVoltage_Cell135 0;
BA_ "GenSigTimeoutTime_IDCM" SG_ 1849 HVBatCellVoltage_Cell134 0;
BA_ "GenSigTimeoutTime_EVCU2" SG_ 1849 HVBatCellVoltage_Cell134 0;
BA_ "GenSigTimeoutTime_BPCM" SG_ 1849 HVBatCellVoltage_Cell134 0;
BA_ "GenSigTimeoutTime_IDCM" SG_ 1849 HVBatCellVoltage_Cell133 0;
BA_ "GenSigTimeoutTime_EVCU2" SG_ 1849 HVBatCellVoltage_Cell133 0;
BA_ "GenSigTimeoutTime_BPCM" SG_ 1849 HVBatCellVoltage_Cell133 0;
BA_ "GenSigTimeoutTime_IDCM" SG_ 1849 HVBatCellVoltage_Cell132 0;
BA_ "GenSigTimeoutTime_EVCU2" SG_ 1849 HVBatCellVoltage_Cell132 0;
BA_ "GenSigTimeoutTime_BPCM" SG_ 1849 HVBatCellVoltage_Cell132 0;
BA_ "GenSigTimeoutTime_IDCM" SG_ 1849 HVBatCellVoltage_Cell131 0;
BA_ "GenSigTimeoutTime_EVCU2" SG_ 1849 HVBatCellVoltage_Cell131 0;
BA_ "GenSigTimeoutTime_BPCM" SG_ 1849 HVBatCellVoltage_Cell131 0;
BA_ "GenSigTimeoutTime_IDCM" SG_ 1849 HVBatCellVoltage_Cell130 0;
BA_ "GenSigTimeoutTime_EVCU2" SG_ 1849 HVBatCellVoltage_Cell130 0;
BA_ "GenSigTimeoutTime_BPCM" SG_ 1849 HVBatCellVoltage_Cell130 0;
BA_ "GenSigTimeoutTime_IDCM" SG_ 1849 HVBatCellVoltage_Cell129 0;
BA_ "GenSigTimeoutTime_EVCU2" SG_ 1849 HVBatCellVoltage_Cell129 0;
BA_ "GenSigTimeoutTime_BPCM" SG_ 1849 HVBatCellVoltage_Cell129 0;
BA_ "GenSigTimeoutTime_IDCM" SG_ 1849 HVBatCellVoltage_Cell128 0;
BA_ "GenSigTimeoutTime_EVCU2" SG_ 1849 HVBatCellVoltage_Cell128 0;
BA_ "GenSigTimeoutTime_BPCM" SG_ 1849 HVBatCellVoltage_Cell128 0;
BA_ "GenSigTimeoutTime_IDCM" SG_ 1849 HVBatCellVoltage_Cell127 0;
BA_ "GenSigTimeoutTime_EVCU2" SG_ 1849 HVBatCellVoltage_Cell127 0;
BA_ "GenSigTimeoutTime_BPCM" SG_ 1849 HVBatCellVoltage_Cell127 0;
BA_ "GenSigTimeoutTime_IDCM" SG_ 1849 HVBatCellVoltage_Cell126 0;
BA_ "GenSigTimeoutTime_EVCU2" SG_ 1849 HVBatCellVoltage_Cell126 0;
BA_ "GenSigTimeoutTime_BPCM" SG_ 1849 HVBatCellVoltage_Cell126 0;
BA_ "GenSigTimeoutTime_IDCM" SG_ 1849 HVBatCellVoltage_Cell125 0;
BA_ "GenSigTimeoutTime_EVCU2" SG_ 1849 HVBatCellVoltage_Cell125 0;
BA_ "GenSigTimeoutTime_BPCM" SG_ 1849 HVBatCellVoltage_Cell125 0;
BA_ "GenSigTimeoutTime_IDCM" SG_ 1849 HVBatCellVoltage_Cell124 0;
BA_ "GenSigTimeoutTime_EVCU2" SG_ 1849 HVBatCellVoltage_Cell124 0;
BA_ "GenSigTimeoutTime_BPCM" SG_ 1849 HVBatCellVoltage_Cell124 0;
BA_ "GenSigTimeoutTime_IDCM" SG_ 1849 HVBatCellVoltage_Cell123 0;
BA_ "GenSigTimeoutTime_EVCU2" SG_ 1849 HVBatCellVoltage_Cell123 0;
BA_ "GenSigTimeoutTime_BPCM" SG_ 1849 HVBatCellVoltage_Cell123 0;
BA_ "GenSigTimeoutTime_IDCM" SG_ 1849 HVBatCellVoltage_Cell122 0;
BA_ "GenSigTimeoutTime_EVCU2" SG_ 1849 HVBatCellVoltage_Cell122 0;
BA_ "GenSigTimeoutTime_BPCM" SG_ 1849 HVBatCellVoltage_Cell122 0;
BA_ "GenSigTimeoutTime_IDCM" SG_ 1849 HVBatCellVoltage_Cell121 0;
BA_ "GenSigTimeoutTime_EVCU2" SG_ 1849 HVBatCellVoltage_Cell121 0;
BA_ "GenSigTimeoutTime_BPCM" SG_ 1849 HVBatCellVoltage_Cell121 0;
BA_ "GenSigTimeoutTime_IDCM" SG_ 1849 HVBatCellVoltage_Cell120 0;
BA_ "GenSigTimeoutTime_EVCU2" SG_ 1849 HVBatCellVoltage_Cell120 0;
BA_ "GenSigTimeoutTime_BPCM" SG_ 1849 HVBatCellVoltage_Cell120 0;
BA_ "GenSigTimeoutTime_IDCM" SG_ 1849 HVBatCellVoltage_Cell119 0;
BA_ "GenSigTimeoutTime_EVCU2" SG_ 1849 HVBatCellVoltage_Cell119 0;
BA_ "GenSigTimeoutTime_BPCM" SG_ 1849 HVBatCellVoltage_Cell119 0;
BA_ "GenSigTimeoutTime_IDCM" SG_ 1849 HVBatCellVoltage_Cell118 0;
BA_ "GenSigTimeoutTime_EVCU2" SG_ 1849 HVBatCellVoltage_Cell118 0;
BA_ "GenSigTimeoutTime_BPCM" SG_ 1849 HVBatCellVoltage_Cell118 0;
BA_ "GenSigTimeoutTime_IDCM" SG_ 1849 HVBatCellVoltage_Cell117 0;
BA_ "GenSigTimeoutTime_EVCU2" SG_ 1849 HVBatCellVoltage_Cell117 0;
BA_ "GenSigTimeoutTime_BPCM" SG_ 1849 HVBatCellVoltage_Cell117 0;
BA_ "GenSigTimeoutTime_IDCM" SG_ 1849 HVBatCellVoltage_Cell116 0;
BA_ "GenSigTimeoutTime_EVCU2" SG_ 1849 HVBatCellVoltage_Cell116 0;
BA_ "GenSigTimeoutTime_BPCM" SG_ 1849 HVBatCellVoltage_Cell116 0;
BA_ "GenSigTimeoutTime_IDCM" SG_ 1849 HVBatCellVoltage_Cell115 0;
BA_ "GenSigTimeoutTime_EVCU2" SG_ 1849 HVBatCellVoltage_Cell115 0;
BA_ "GenSigTimeoutTime_BPCM" SG_ 1849 HVBatCellVoltage_Cell115 0;
BA_ "GenSigTimeoutTime_IDCM" SG_ 1849 HVBatCellVoltage_Cell114 0;
BA_ "GenSigTimeoutTime_EVCU2" SG_ 1849 HVBatCellVoltage_Cell114 0;
BA_ "GenSigTimeoutTime_BPCM" SG_ 1849 HVBatCellVoltage_Cell114 0;
BA_ "GenSigTimeoutTime_IDCM" SG_ 1849 HVBatCellVoltage_Cell113 0;
BA_ "GenSigTimeoutTime_EVCU2" SG_ 1849 HVBatCellVoltage_Cell113 0;
BA_ "GenSigTimeoutTime_BPCM" SG_ 1849 HVBatCellVoltage_Cell113 0;
BA_ "GenSigTimeoutTime_IDCM" SG_ 1849 HVBatCellVoltage_Cell112 0;
BA_ "GenSigTimeoutTime_EVCU2" SG_ 1849 HVBatCellVoltage_Cell112 0;
BA_ "GenSigTimeoutTime_BPCM" SG_ 1849 HVBatCellVoltage_Cell112 0;
BA_ "GenSigTimeoutTime_IDCM" SG_ 1849 HVBatCellVoltage_Cell111 0;
BA_ "GenSigTimeoutTime_EVCU2" SG_ 1849 HVBatCellVoltage_Cell111 0;
BA_ "GenSigTimeoutTime_BPCM" SG_ 1849 HVBatCellVoltage_Cell111 0;
BA_ "GenSigTimeoutTime_IDCM" SG_ 1849 HVBatCellVoltage_Cell110 0;
BA_ "GenSigTimeoutTime_EVCU2" SG_ 1849 HVBatCellVoltage_Cell110 0;
BA_ "GenSigTimeoutTime_BPCM" SG_ 1849 HVBatCellVoltage_Cell110 0;
BA_ "GenSigTimeoutTime_IDCM" SG_ 1849 HVBatCellVoltage_Cell109 0;
BA_ "GenSigTimeoutTime_EVCU2" SG_ 1849 HVBatCellVoltage_Cell109 0;
BA_ "GenSigTimeoutTime_BPCM" SG_ 1849 HVBatCellVoltage_Cell109 0;
BA_ "GenSigTimeoutTime_SGW" SG_ 502 VDCM_OBCDischCurrentLim 0;
BA_ "GenSigTimeoutTime_EVCU2" SG_ 502 VDCM_OBCDischCurrentLim 0;
BA_ "GenSigTimeoutTime_BPCM" SG_ 502 VDCM_OBCDischCurrentLim 0;
BA_ "GenSigStartValue" SG_ 502 VDCM_OBCDischCurrentLim 815;
BA_ "GenSigTimeoutTime_PPIM" SG_ 502 VDCM_OBCDischCurrentLim 0;
BA_ "GenSigTimeoutTime_HCP" SG_ 502 VDCM_OBCDischCurrentLim 0;
BA_ "GenSigTimeoutTime_SGW" SG_ 502 VDCM_BattBulkSOC 0;
BA_ "GenSigTimeoutTime_EVCU2" SG_ 502 VDCM_BattBulkSOC 0;
BA_ "GenSigTimeoutTime_BPCM" SG_ 502 VDCM_BattBulkSOC 0;
BA_ "GenSigTimeoutTime_PPIM" SG_ 502 VDCM_BattBulkSOC 0;
BA_ "GenSigTimeoutTime_HCP" SG_ 502 VDCM_BattBulkSOC 0;
BA_ "GenSigTimeoutTime_SGW" SG_ 502 HVCMS_ServiceScope 0;
BA_ "GenSigTimeoutTime_EVCU2" SG_ 502 HVCMS_ServiceScope 0;
BA_ "GenSigTimeoutTime_BPCM" SG_ 502 HVCMS_ServiceScope 0;
BA_ "GenSigTimeoutTime_PPIM" SG_ 502 HVCMS_ServiceScope 0;
BA_ "GenSigTimeoutTime_HCP" SG_ 502 HVCMS_ServiceScope 0;
BA_ "GenSigTimeoutTime_SGW" SG_ 502 HVCMS_ReadyToChargeState 0;
BA_ "GenSigTimeoutTime_EVCU2" SG_ 502 HVCMS_ReadyToChargeState 0;
BA_ "GenSigTimeoutTime_BPCM" SG_ 502 HVCMS_ReadyToChargeState 0;
BA_ "GenSigTimeoutTime_PPIM" SG_ 502 HVCMS_ReadyToChargeState 0;
BA_ "GenSigTimeoutTime_HCP" SG_ 502 HVCMS_ReadyToChargeState 0;
BA_ "GenSigTimeoutTime_SGW" SG_ 502 HVCMS_Protocol_Entry3 0;
BA_ "GenSigTimeoutTime_EVCU2" SG_ 502 HVCMS_Protocol_Entry3 0;
BA_ "GenSigTimeoutTime_BPCM" SG_ 502 HVCMS_Protocol_Entry3 0;
BA_ "GenSigTimeoutTime_PPIM" SG_ 502 HVCMS_Protocol_Entry3 0;
BA_ "GenSigTimeoutTime_HCP" SG_ 502 HVCMS_Protocol_Entry3 0;
BA_ "GenSigTimeoutTime_SGW" SG_ 502 HVCMS_Protocol_Entry2 0;
BA_ "GenSigTimeoutTime_EVCU2" SG_ 502 HVCMS_Protocol_Entry2 0;
BA_ "GenSigTimeoutTime_BPCM" SG_ 502 HVCMS_Protocol_Entry2 0;
BA_ "GenSigTimeoutTime_PPIM" SG_ 502 HVCMS_Protocol_Entry2 0;
BA_ "GenSigTimeoutTime_HCP" SG_ 502 HVCMS_Protocol_Entry2 0;
BA_ "GenSigTimeoutTime_SGW" SG_ 502 HVCMS_Protocol_Entry1 0;
BA_ "GenSigTimeoutTime_EVCU2" SG_ 502 HVCMS_Protocol_Entry1 0;
BA_ "GenSigTimeoutTime_BPCM" SG_ 502 HVCMS_Protocol_Entry1 0;
BA_ "GenSigTimeoutTime_PPIM" SG_ 502 HVCMS_Protocol_Entry1 0;
BA_ "GenSigTimeoutTime_HCP" SG_ 502 HVCMS_Protocol_Entry1 0;
BA_ "GenSigTimeoutTime_SGW" SG_ 502 HVCMS_EVTargetVoltage 0;
BA_ "GenSigTimeoutTime_EVCU2" SG_ 502 HVCMS_EVTargetVoltage 0;
BA_ "GenSigTimeoutTime_BPCM" SG_ 502 HVCMS_EVTargetVoltage 0;
BA_ "GenSigTimeoutTime_PPIM" SG_ 502 HVCMS_EVTargetVoltage 0;
BA_ "GenSigTimeoutTime_HCP" SG_ 502 HVCMS_EVTargetVoltage 0;
BA_ "GenSigTimeoutTime_SGW" SG_ 502 HVCMS_EVTargetCurrent 0;
BA_ "GenSigTimeoutTime_EVCU2" SG_ 502 HVCMS_EVTargetCurrent 0;
BA_ "GenSigTimeoutTime_BPCM" SG_ 502 HVCMS_EVTargetCurrent 0;
BA_ "GenSigTimeoutTime_PPIM" SG_ 502 HVCMS_EVTargetCurrent 0;
BA_ "GenSigTimeoutTime_HCP" SG_ 502 HVCMS_EVTargetCurrent 0;
BA_ "GenSigTimeoutTime_SGW" SG_ 502 HVCMS_EVRESSConditioning 0;
BA_ "GenSigTimeoutTime_EVCU2" SG_ 502 HVCMS_EVRESSConditioning 0;
BA_ "GenSigTimeoutTime_BPCM" SG_ 502 HVCMS_EVRESSConditioning 0;
BA_ "GenSigTimeoutTime_PPIM" SG_ 502 HVCMS_EVRESSConditioning 0;
BA_ "GenSigTimeoutTime_HCP" SG_ 502 HVCMS_EVRESSConditioning 0;
BA_ "GenSigTimeoutTime_SGW" SG_ 502 HVCMS_EVRESS_SOC 0;
BA_ "GenSigTimeoutTime_EVCU2" SG_ 502 HVCMS_EVRESS_SOC 0;
BA_ "GenSigTimeoutTime_BPCM" SG_ 502 HVCMS_EVRESS_SOC 0;
BA_ "GenSigTimeoutTime_PPIM" SG_ 502 HVCMS_EVRESS_SOC 0;
BA_ "GenSigTimeoutTime_HCP" SG_ 502 HVCMS_EVRESS_SOC 0;
BA_ "GenSigTimeoutTime_SGW" SG_ 502 HVCMS_EVReady 0;
BA_ "GenSigTimeoutTime_EVCU2" SG_ 502 HVCMS_EVReady 0;
BA_ "GenSigTimeoutTime_BPCM" SG_ 502 HVCMS_EVReady 0;
BA_ "GenSigTimeoutTime_PPIM" SG_ 502 HVCMS_EVReady 0;
BA_ "GenSigTimeoutTime_HCP" SG_ 502 HVCMS_EVReady 0;
BA_ "GenSigTimeoutTime_SGW" SG_ 502 HVCMS_EVMax_V_Limit 0;
BA_ "GenSigTimeoutTime_EVCU2" SG_ 502 HVCMS_EVMax_V_Limit 0;
BA_ "GenSigTimeoutTime_BPCM" SG_ 502 HVCMS_EVMax_V_Limit 0;
BA_ "GenSigTimeoutTime_PPIM" SG_ 502 HVCMS_EVMax_V_Limit 0;
BA_ "GenSigTimeoutTime_HCP" SG_ 502 HVCMS_EVMax_V_Limit 0;
BA_ "GenSigTimeoutTime_SGW" SG_ 502 HVCMS_EVMax_P_Limit 0;
BA_ "GenSigTimeoutTime_EVCU2" SG_ 502 HVCMS_EVMax_P_Limit 0;
BA_ "GenSigTimeoutTime_BPCM" SG_ 502 HVCMS_EVMax_P_Limit 0;
BA_ "GenSigTimeoutTime_PPIM" SG_ 502 HVCMS_EVMax_P_Limit 0;
BA_ "GenSigTimeoutTime_HCP" SG_ 502 HVCMS_EVMax_P_Limit 0;
BA_ "GenSigTimeoutTime_SGW" SG_ 502 HVCMS_EVMax_I_Limit 0;
BA_ "GenSigTimeoutTime_EVCU2" SG_ 502 HVCMS_EVMax_I_Limit 0;
BA_ "GenSigTimeoutTime_BPCM" SG_ 502 HVCMS_EVMax_I_Limit 0;
BA_ "GenSigTimeoutTime_PPIM" SG_ 502 HVCMS_EVMax_I_Limit 0;
BA_ "GenSigTimeoutTime_HCP" SG_ 502 HVCMS_EVMax_I_Limit 0;
BA_ "GenSigTimeoutTime_SGW" SG_ 502 HVCMS_EVEnergyCapacity 0;
BA_ "GenSigTimeoutTime_EVCU2" SG_ 502 HVCMS_EVEnergyCapacity 0;
BA_ "GenSigTimeoutTime_BPCM" SG_ 502 HVCMS_EVEnergyCapacity 0;
BA_ "GenSigTimeoutTime_PPIM" SG_ 502 HVCMS_EVEnergyCapacity 0;
BA_ "GenSigTimeoutTime_HCP" SG_ 502 HVCMS_EVEnergyCapacity 0;
BA_ "GenSigTimeoutTime_SGW" SG_ 502 HVCMS_ChargingComplete 0;
BA_ "GenSigTimeoutTime_EVCU2" SG_ 502 HVCMS_ChargingComplete 0;
BA_ "GenSigTimeoutTime_BPCM" SG_ 502 HVCMS_ChargingComplete 0;
BA_ "GenSigTimeoutTime_PPIM" SG_ 502 HVCMS_ChargingComplete 0;
BA_ "GenSigTimeoutTime_HCP" SG_ 502 HVCMS_ChargingComplete 0;
BA_ "GenSigTimeoutTime_SGW" SG_ 502 HVCMS_BulkChargingComplete 0;
BA_ "GenSigTimeoutTime_EVCU2" SG_ 502 HVCMS_BulkChargingComplete 0;
BA_ "GenSigTimeoutTime_BPCM" SG_ 502 HVCMS_BulkChargingComplete 0;
BA_ "GenSigTimeoutTime_PPIM" SG_ 502 HVCMS_BulkChargingComplete 0;
BA_ "GenSigTimeoutTime_HCP" SG_ 502 HVCMS_BulkChargingComplete 0;
BA_ "GenSigTimeoutTime_PPIM" SG_ 502 VDCM_TypeCNegotiationSts 0;
BA_ "GenSigTimeoutTime_HCP" SG_ 502 VDCM_TypeCNegotiationSts 0;
BA_ "GenSigTimeoutTime_SGW" SG_ 502 VDCM_TypeCNegotiationSts 0;
BA_ "GenSigTimeoutTime_EVCU2" SG_ 502 VDCM_TypeCNegotiationSts 0;
BA_ "GenSigTimeoutTime_BPCM" SG_ 502 VDCM_TypeCNegotiationSts 0;
BA_ "GenSigTimeoutTime_PPIM" SG_ 502 VDCM_GenChallenge 0;
BA_ "GenSigTimeoutTime_HCP" SG_ 502 VDCM_GenChallenge 0;
BA_ "GenSigTimeoutTime_SGW" SG_ 502 VDCM_GenChallenge 0;
BA_ "GenSigTimeoutTime_EVCU2" SG_ 502 VDCM_GenChallenge 0;
BA_ "GenSigTimeoutTime_BPCM" SG_ 502 VDCM_GenChallenge 0;
BA_ "GenSigTimeoutTime_PPIM" SG_ 502 VDCM_ContractAuthenticationID 0;
BA_ "GenSigTimeoutTime_HCP" SG_ 502 VDCM_ContractAuthenticationID 0;
BA_ "GenSigTimeoutTime_SGW" SG_ 502 VDCM_ContractAuthenticationID 0;
BA_ "GenSigTimeoutTime_EVCU2" SG_ 502 VDCM_ContractAuthenticationID 0;
BA_ "GenSigTimeoutTime_BPCM" SG_ 502 VDCM_ContractAuthenticationID 0;
BA_ "GenSigTimeoutTime_PPIM" SG_ 502 HVCMS_EVEnergyRequest 0;
BA_ "GenSigTimeoutTime_HCP" SG_ 502 HVCMS_EVEnergyRequest 0;
BA_ "GenSigTimeoutTime_SGW" SG_ 502 HVCMS_EVEnergyRequest 0;
BA_ "GenSigTimeoutTime_EVCU2" SG_ 502 HVCMS_EVEnergyRequest 0;
BA_ "GenSigTimeoutTime_BPCM" SG_ 502 HVCMS_EVEnergyRequest 0;
BA_ "GenSigStartValue" SG_ 502 HVCMS_EVEnergyRequest 131071;
BA_ "GenSigTimeoutTime_PPIM" SG_ 502 OBCM_OutVoltageSyncTgt 0;
BA_ "GenSigTimeoutTime_HCP" SG_ 502 OBCM_OutVoltageSyncTgt 0;
BA_ "GenSigTimeoutTime_SGW" SG_ 502 OBCM_OutVoltageSyncTgt 0;
BA_ "GenSigTimeoutTime_EVCU2" SG_ 502 OBCM_OutVoltageSyncTgt 0;
BA_ "GenSigTimeoutTime_BPCM" SG_ 502 OBCM_OutVoltageSyncTgt 0;
BA_ "GenSigTimeoutTime_PPIM" SG_ 502 HVCMS_ServiceCategory 0;
BA_ "GenSigTimeoutTime_HCP" SG_ 502 HVCMS_ServiceCategory 0;
BA_ "GenSigTimeoutTime_SGW" SG_ 502 HVCMS_ServiceCategory 0;
BA_ "GenSigTimeoutTime_EVCU2" SG_ 502 HVCMS_ServiceCategory 0;
BA_ "GenSigTimeoutTime_BPCM" SG_ 502 HVCMS_ServiceCategory 0;
BA_ "GenSigTimeoutTime_SGW" SG_ 502 HVCMS_SelectedServiceId 0;
BA_ "GenSigTimeoutTime_EVCU2" SG_ 502 HVCMS_SelectedServiceId 0;
BA_ "GenSigTimeoutTime_BPCM" SG_ 502 HVCMS_SelectedServiceId 0;
BA_ "GenSigTimeoutTime_PPIM" SG_ 502 HVCMS_SelectedServiceId 0;
BA_ "GenSigTimeoutTime_HCP" SG_ 502 HVCMS_SelectedServiceId 0;
BA_ "GenSigTimeoutTime_SGW" SG_ 502 HVCMS_SelectedPaymentOptn 0;
BA_ "GenSigTimeoutTime_EVCU2" SG_ 502 HVCMS_SelectedPaymentOptn 0;
BA_ "GenSigTimeoutTime_BPCM" SG_ 502 HVCMS_SelectedPaymentOptn 0;
BA_ "GenSigTimeoutTime_PPIM" SG_ 502 HVCMS_SelectedPaymentOptn 0;
BA_ "GenSigTimeoutTime_HCP" SG_ 502 HVCMS_SelectedPaymentOptn 0;
BA_ "GenSigTimeoutTime_SGW" SG_ 502 HVCMS_SelectedEnergyTransferType 0;
BA_ "GenSigTimeoutTime_EVCU2" SG_ 502 HVCMS_SelectedEnergyTransferType 0;
BA_ "GenSigTimeoutTime_BPCM" SG_ 502 HVCMS_SelectedEnergyTransferType 0;
BA_ "GenSigTimeoutTime_PPIM" SG_ 502 HVCMS_SelectedEnergyTransferType 0;
BA_ "GenSigTimeoutTime_HCP" SG_ 502 HVCMS_SelectedEnergyTransferType 0;
BA_ "GenSigTimeoutTime_SGW" SG_ 502 HVCMS_RemaningTimeToFullSOC 0;
BA_ "GenSigTimeoutTime_EVCU2" SG_ 502 HVCMS_RemaningTimeToFullSOC 0;
BA_ "GenSigTimeoutTime_BPCM" SG_ 502 HVCMS_RemaningTimeToFullSOC 0;
BA_ "GenSigTimeoutTime_PPIM" SG_ 502 HVCMS_RemaningTimeToFullSOC 0;
BA_ "GenSigTimeoutTime_HCP" SG_ 502 HVCMS_RemaningTimeToFullSOC 0;
BA_ "GenSigTimeoutTime_SGW" SG_ 502 HVCMS_RemaningTimeToBulkSOC 0;
BA_ "GenSigTimeoutTime_EVCU2" SG_ 502 HVCMS_RemaningTimeToBulkSOC 0;
BA_ "GenSigTimeoutTime_BPCM" SG_ 502 HVCMS_RemaningTimeToBulkSOC 0;
BA_ "GenSigTimeoutTime_PPIM" SG_ 502 HVCMS_RemaningTimeToBulkSOC 0;
BA_ "GenSigTimeoutTime_HCP" SG_ 502 HVCMS_RemaningTimeToBulkSOC 0;
BA_ "GenSigTimeoutTime_BPCM" SG_ 502 HVCMS_EVErrorCode 0;
BA_ "GenSigTimeoutTime_PPIM" SG_ 502 HVCMS_EVErrorCode 0;
BA_ "GenSigTimeoutTime_HCP" SG_ 502 HVCMS_EVErrorCode 0;
BA_ "GenSigTimeoutTime_SGW" SG_ 502 HVCMS_EVErrorCode 0;
BA_ "GenSigTimeoutTime_EVCU2" SG_ 502 HVCMS_EVErrorCode 0;
BA_ "GenSigTimeoutTime_SGW" SG_ 242 MC_PF1 0;
BA_ "GenSigTimeoutTime_IDCM" SG_ 242 MC_PF1 0;
BA_ "GenSigTimeoutTime_EVCU2" SG_ 242 MC_PF1 0;
BA_ "GenSigTimeoutTime_SGW" SG_ 242 CRC_PF1 0;
BA_ "GenSigTimeoutTime_IDCM" SG_ 242 CRC_PF1 0;
BA_ "GenSigTimeoutTime_EVCU2" SG_ 242 CRC_PF1 0;
BA_ "GenSigTimeoutTime_SGW" SG_ 242 MCPA_DC_Current 0;
BA_ "GenSigTimeoutTime_IDCM" SG_ 242 MCPA_DC_Current 0;
BA_ "GenSigTimeoutTime_EVCU2" SG_ 242 MCPA_DC_Current 0;
BA_ "GenSigStartValue" SG_ 242 MCPA_DC_Current 16384;
BA_ "GenSigTimeoutTime_SGW" SG_ 498 HVCMS_EVSEPresentVoltage 0;
BA_ "GenSigTimeoutTime_IDCM" SG_ 498 HVCMS_EVSEPresentVoltage 0;
BA_ "GenSigTimeoutTime_BPCM" SG_ 498 HVCMS_EVSEPresentVoltage 0;
BA_ "GenSigTimeoutTime_PPIM" SG_ 498 HVCMS_EVSEPresentVoltage 0;
BA_ "GenSigTimeoutTime_HCP" SG_ 498 HVCMS_EVSEPresentVoltage 0;
BA_ "GenSigTimeoutTime_SGW" SG_ 498 HVCMS_EVSEPeakCurrentRipple 0;
BA_ "GenSigTimeoutTime_IDCM" SG_ 498 HVCMS_EVSEPeakCurrentRipple 0;
BA_ "GenSigTimeoutTime_BPCM" SG_ 498 HVCMS_EVSEPeakCurrentRipple 0;
BA_ "GenSigStartValue" SG_ 498 HVCMS_EVSEPeakCurrentRipple 500;
BA_ "GenSigTimeoutTime_PPIM" SG_ 498 HVCMS_EVSEPeakCurrentRipple 0;
BA_ "GenSigTimeoutTime_HCP" SG_ 498 HVCMS_EVSEPeakCurrentRipple 0;
BA_ "GenSigTimeoutTime_SGW" SG_ 498 HVCMS_EVSEMinCurrentLimit 0;
BA_ "GenSigTimeoutTime_IDCM" SG_ 498 HVCMS_EVSEMinCurrentLimit 0;
BA_ "GenSigTimeoutTime_BPCM" SG_ 498 HVCMS_EVSEMinCurrentLimit 0;
BA_ "GenSigTimeoutTime_PPIM" SG_ 498 HVCMS_EVSEMinCurrentLimit 0;
BA_ "GenSigTimeoutTime_HCP" SG_ 498 HVCMS_EVSEMinCurrentLimit 0;
BA_ "GenSigTimeoutTime_SGW" SG_ 498 HVCMS_EVSEMaxPowerLimit 0;
BA_ "GenSigTimeoutTime_IDCM" SG_ 498 HVCMS_EVSEMaxPowerLimit 0;
BA_ "GenSigTimeoutTime_BPCM" SG_ 498 HVCMS_EVSEMaxPowerLimit 0;
BA_ "GenSigTimeoutTime_PPIM" SG_ 498 HVCMS_EVSEMaxPowerLimit 0;
BA_ "GenSigTimeoutTime_HCP" SG_ 498 HVCMS_EVSEMaxPowerLimit 0;
BA_ "GenSigTimeoutTime_SGW" SG_ 498 HVCMS_EVSEMaxCurrentLimit 0;
BA_ "GenSigTimeoutTime_IDCM" SG_ 498 HVCMS_EVSEMaxCurrentLimit 0;
BA_ "GenSigTimeoutTime_BPCM" SG_ 498 HVCMS_EVSEMaxCurrentLimit 0;
BA_ "GenSigTimeoutTime_PPIM" SG_ 498 HVCMS_EVSEMaxCurrentLimit 0;
BA_ "GenSigTimeoutTime_HCP" SG_ 498 HVCMS_EVSEMaxCurrentLimit 0;
BA_ "GenSigTimeoutTime_SGW" SG_ 498 HVCMS_EVSECurrRegulationTol 0;
BA_ "GenSigTimeoutTime_IDCM" SG_ 498 HVCMS_EVSECurrRegulationTol 0;
BA_ "GenSigTimeoutTime_BPCM" SG_ 498 HVCMS_EVSECurrRegulationTol 0;
BA_ "GenSigStartValue" SG_ 498 HVCMS_EVSECurrRegulationTol 500;
BA_ "GenSigTimeoutTime_PPIM" SG_ 498 HVCMS_EVSECurrRegulationTol 0;
BA_ "GenSigTimeoutTime_HCP" SG_ 498 HVCMS_EVSECurrRegulationTol 0;
BA_ "GenSigTimeoutTime_PPIM" SG_ 498 HVCMS_EnergyToBeDelivered 0;
BA_ "GenSigTimeoutTime_HCP" SG_ 498 HVCMS_EnergyToBeDelivered 0;
BA_ "GenSigTimeoutTime_SGW" SG_ 498 HVCMS_EnergyToBeDelivered 0;
BA_ "GenSigTimeoutTime_IDCM" SG_ 498 HVCMS_EnergyToBeDelivered 0;
BA_ "GenSigTimeoutTime_BPCM" SG_ 498 HVCMS_EnergyToBeDelivered 0;
BA_ "GenSigTimeoutTime_PPIM" SG_ 498 EVSE_IsolationSts 0;
BA_ "GenSigTimeoutTime_HCP" SG_ 498 EVSE_IsolationSts 0;
BA_ "GenSigTimeoutTime_SGW" SG_ 498 EVSE_IsolationSts 0;
BA_ "GenSigTimeoutTime_IDCM" SG_ 498 EVSE_IsolationSts 0;
BA_ "GenSigTimeoutTime_BPCM" SG_ 498 EVSE_IsolationSts 0;
BA_ "GenSigTimeoutTime_PPIM" SG_ 498 EVSE_Accepted_Protocol 0;
BA_ "GenSigTimeoutTime_HCP" SG_ 498 EVSE_Accepted_Protocol 0;
BA_ "GenSigTimeoutTime_SGW" SG_ 498 EVSE_Accepted_Protocol 0;
BA_ "GenSigTimeoutTime_IDCM" SG_ 498 EVSE_Accepted_Protocol 0;
BA_ "GenSigTimeoutTime_BPCM" SG_ 498 EVSE_Accepted_Protocol 0;
BA_ "GenSigTimeoutTime_PPIM" SG_ 498 DC_TimeOut 0;
BA_ "GenSigTimeoutTime_HCP" SG_ 498 DC_TimeOut 0;
BA_ "GenSigTimeoutTime_SGW" SG_ 498 DC_TimeOut 0;
BA_ "GenSigTimeoutTime_IDCM" SG_ 498 DC_TimeOut 0;
BA_ "GenSigTimeoutTime_BPCM" SG_ 498 DC_TimeOut 0;
BA_ "GenSigTimeoutTime_PPIM" SG_ 498 DC_Isolation_Disable_Cmd 0;
BA_ "GenSigTimeoutTime_HCP" SG_ 498 DC_Isolation_Disable_Cmd 0;
BA_ "GenSigTimeoutTime_SGW" SG_ 498 DC_Isolation_Disable_Cmd 0;
BA_ "GenSigTimeoutTime_IDCM" SG_ 498 DC_Isolation_Disable_Cmd 0;
BA_ "GenSigTimeoutTime_BPCM" SG_ 498 DC_Isolation_Disable_Cmd 0;
BA_ "GenSigTimeoutTime_PPIM" SG_ 498 OBCM_PLCTypeSts 0;
BA_ "GenSigTimeoutTime_HCP" SG_ 498 OBCM_PLCTypeSts 0;
BA_ "GenSigTimeoutTime_SGW" SG_ 498 OBCM_PLCTypeSts 0;
BA_ "GenSigTimeoutTime_IDCM" SG_ 498 OBCM_PLCTypeSts 0;
BA_ "GenSigTimeoutTime_BPCM" SG_ 498 OBCM_PLCTypeSts 0;
BA_ "GenSigTimeoutTime_SGW" SG_ 498 HVCMS_EVSEVoltageLimitAchieved 0;
BA_ "GenSigTimeoutTime_IDCM" SG_ 498 HVCMS_EVSEVoltageLimitAchieved 0;
BA_ "GenSigTimeoutTime_BPCM" SG_ 498 HVCMS_EVSEVoltageLimitAchieved 0;
BA_ "GenSigStartValue" SG_ 498 HVCMS_EVSEVoltageLimitAchieved 2;
BA_ "GenSigTimeoutTime_PPIM" SG_ 498 HVCMS_EVSEVoltageLimitAchieved 0;
BA_ "GenSigTimeoutTime_HCP" SG_ 498 HVCMS_EVSEVoltageLimitAchieved 0;
BA_ "GenSigTimeoutTime_PPIM" SG_ 498 HVCMS_EVSEPowerLimitAchieved 0;
BA_ "GenSigTimeoutTime_HCP" SG_ 498 HVCMS_EVSEPowerLimitAchieved 0;
BA_ "GenSigTimeoutTime_SGW" SG_ 498 HVCMS_EVSEPowerLimitAchieved 0;
BA_ "GenSigTimeoutTime_IDCM" SG_ 498 HVCMS_EVSEPowerLimitAchieved 0;
BA_ "GenSigTimeoutTime_BPCM" SG_ 498 HVCMS_EVSEPowerLimitAchieved 0;
BA_ "GenSigStartValue" SG_ 498 HVCMS_EVSEPowerLimitAchieved 2;
BA_ "GenSigTimeoutTime_SGW" SG_ 498 HVCMS_EVSEMinimumVoltageLimit 0;
BA_ "GenSigTimeoutTime_IDCM" SG_ 498 HVCMS_EVSEMinimumVoltageLimit 0;
BA_ "GenSigTimeoutTime_BPCM" SG_ 498 HVCMS_EVSEMinimumVoltageLimit 0;
BA_ "GenSigTimeoutTime_PPIM" SG_ 498 HVCMS_EVSEMinimumVoltageLimit 0;
BA_ "GenSigTimeoutTime_HCP" SG_ 498 HVCMS_EVSEMinimumVoltageLimit 0;
BA_ "GenSigTimeoutTime_SGW" SG_ 498 HVCMS_EVSEMaximumVoltageLimit 0;
BA_ "GenSigTimeoutTime_IDCM" SG_ 498 HVCMS_EVSEMaximumVoltageLimit 0;
BA_ "GenSigTimeoutTime_BPCM" SG_ 498 HVCMS_EVSEMaximumVoltageLimit 0;
BA_ "GenSigTimeoutTime_PPIM" SG_ 498 HVCMS_EVSEMaximumVoltageLimit 0;
BA_ "GenSigTimeoutTime_HCP" SG_ 498 HVCMS_EVSEMaximumVoltageLimit 0;
BA_ "GenSigTimeoutTime_SGW" SG_ 498 HVCMS_EVSECurrentLimitAchieved 0;
BA_ "GenSigTimeoutTime_IDCM" SG_ 498 HVCMS_EVSECurrentLimitAchieved 0;
BA_ "GenSigTimeoutTime_BPCM" SG_ 498 HVCMS_EVSECurrentLimitAchieved 0;
BA_ "GenSigStartValue" SG_ 498 HVCMS_EVSECurrentLimitAchieved 2;
BA_ "GenSigTimeoutTime_PPIM" SG_ 498 HVCMS_EVSECurrentLimitAchieved 0;
BA_ "GenSigTimeoutTime_HCP" SG_ 498 HVCMS_EVSECurrentLimitAchieved 0;
BA_ "GenSigTimeoutTime_SGW" SG_ 498 HVCMS_EVSEPresentCurrent 0;
BA_ "GenSigTimeoutTime_IDCM" SG_ 498 HVCMS_EVSEPresentCurrent 0;
BA_ "GenSigTimeoutTime_BPCM" SG_ 498 HVCMS_EVSEPresentCurrent 0;
BA_ "GenSigTimeoutTime_PPIM" SG_ 498 HVCMS_EVSEPresentCurrent 0;
BA_ "GenSigTimeoutTime_HCP" SG_ 498 HVCMS_EVSEPresentCurrent 0;
BA_ "GenSigTimeoutTime_SGW" SG_ 498 EVSE_OfferedEnergyTransferType 0;
BA_ "GenSigTimeoutTime_IDCM" SG_ 498 EVSE_OfferedEnergyTransferType 0;
BA_ "GenSigTimeoutTime_BPCM" SG_ 498 EVSE_OfferedEnergyTransferType 0;
BA_ "GenSigTimeoutTime_PPIM" SG_ 498 EVSE_OfferedEnergyTransferType 0;
BA_ "GenSigTimeoutTime_HCP" SG_ 498 EVSE_OfferedEnergyTransferType 0;
BA_ "GenSigTimeoutTime_SGW" SG_ 498 HVCMS_TxMessageStat 0;
BA_ "GenSigTimeoutTime_IDCM" SG_ 498 HVCMS_TxMessageStat 0;
BA_ "GenSigTimeoutTime_BPCM" SG_ 498 HVCMS_TxMessageStat 0;
BA_ "GenSigTimeoutTime_PPIM" SG_ 498 HVCMS_TxMessageStat 0;
BA_ "GenSigTimeoutTime_HCP" SG_ 498 HVCMS_TxMessageStat 0;
BA_ "GenSigTimeoutTime_SGW" SG_ 498 HVCMS_ResponseCode 0;
BA_ "GenSigTimeoutTime_IDCM" SG_ 498 HVCMS_ResponseCode 0;
BA_ "GenSigTimeoutTime_BPCM" SG_ 498 HVCMS_ResponseCode 0;
BA_ "GenSigTimeoutTime_PPIM" SG_ 498 HVCMS_ResponseCode 0;
BA_ "GenSigTimeoutTime_HCP" SG_ 498 HVCMS_ResponseCode 0;
BA_ "GenSigTimeoutTime_SGW" SG_ 498 HVCMS_EVSEProcessing 0;
BA_ "GenSigTimeoutTime_IDCM" SG_ 498 HVCMS_EVSEProcessing 0;
BA_ "GenSigTimeoutTime_BPCM" SG_ 498 HVCMS_EVSEProcessing 0;
BA_ "GenSigTimeoutTime_PPIM" SG_ 498 HVCMS_EVSEProcessing 0;
BA_ "GenSigTimeoutTime_HCP" SG_ 498 HVCMS_EVSEProcessing 0;
BA_ "GenSigTimeoutTime_SGW" SG_ 498 EVSE_FreeService 0;
BA_ "GenSigTimeoutTime_IDCM" SG_ 498 EVSE_FreeService 0;
BA_ "GenSigTimeoutTime_BPCM" SG_ 498 EVSE_FreeService 0;
BA_ "GenSigTimeoutTime_PPIM" SG_ 498 EVSE_FreeService 0;
BA_ "GenSigTimeoutTime_HCP" SG_ 498 EVSE_FreeService 0;
BA_ "GenSigTimeoutTime_SGW" SG_ 498 TxMessageResponse 0;
BA_ "GenSigTimeoutTime_IDCM" SG_ 498 TxMessageResponse 0;
BA_ "GenSigTimeoutTime_BPCM" SG_ 498 TxMessageResponse 0;
BA_ "GenSigTimeoutTime_PPIM" SG_ 498 TxMessageResponse 0;
BA_ "GenSigTimeoutTime_HCP" SG_ 498 TxMessageResponse 0;
BA_ "GenSigTimeoutTime_SGW" SG_ 498 HVCMS_EVSEStatusCode 0;
BA_ "GenSigTimeoutTime_IDCM" SG_ 498 HVCMS_EVSEStatusCode 0;
BA_ "GenSigTimeoutTime_BPCM" SG_ 498 HVCMS_EVSEStatusCode 0;
BA_ "GenSigStartValue" SG_ 498 HVCMS_EVSEStatusCode 15;
BA_ "GenSigTimeoutTime_PPIM" SG_ 498 HVCMS_EVSEStatusCode 0;
BA_ "GenSigTimeoutTime_HCP" SG_ 498 HVCMS_EVSEStatusCode 0;
BA_ "GenSigTimeoutTime_SGW" SG_ 498 EVSE_ServiceId 0;
BA_ "GenSigTimeoutTime_IDCM" SG_ 498 EVSE_ServiceId 0;
BA_ "GenSigTimeoutTime_BPCM" SG_ 498 EVSE_ServiceId 0;
BA_ "GenSigTimeoutTime_PPIM" SG_ 498 EVSE_ServiceId 0;
BA_ "GenSigTimeoutTime_HCP" SG_ 498 EVSE_ServiceId 0;
BA_ "GenSigTimeoutTime_SGW" SG_ 498 EVSE_OfferedService 0;
BA_ "GenSigTimeoutTime_IDCM" SG_ 498 EVSE_OfferedService 0;
BA_ "GenSigTimeoutTime_BPCM" SG_ 498 EVSE_OfferedService 0;
BA_ "GenSigTimeoutTime_PPIM" SG_ 498 EVSE_OfferedService 0;
BA_ "GenSigTimeoutTime_HCP" SG_ 498 EVSE_OfferedService 0;
BA_ "GenSigTimeoutTime_SGW" SG_ 498 EVSE_OfferedPaymentOptn 0;
BA_ "GenSigTimeoutTime_IDCM" SG_ 498 EVSE_OfferedPaymentOptn 0;
BA_ "GenSigTimeoutTime_BPCM" SG_ 498 EVSE_OfferedPaymentOptn 0;
BA_ "GenSigTimeoutTime_PPIM" SG_ 498 EVSE_OfferedPaymentOptn 0;
BA_ "GenSigTimeoutTime_HCP" SG_ 498 EVSE_OfferedPaymentOptn 0;
BA_ "GenSigTimeoutTime_SGW" SG_ 498 MC_OBCM_VDCM 0;
BA_ "GenSigTimeoutTime_IDCM" SG_ 498 MC_OBCM_VDCM 0;
BA_ "GenSigTimeoutTime_BPCM" SG_ 498 MC_OBCM_VDCM 0;
BA_ "GenSigTimeoutTime_PPIM" SG_ 498 MC_OBCM_VDCM 0;
BA_ "GenSigTimeoutTime_HCP" SG_ 498 MC_OBCM_VDCM 0;
BA_ "GenSigTimeoutTime_SGW" SG_ 498 EVSE_Supported_ISO1 0;
BA_ "GenSigTimeoutTime_IDCM" SG_ 498 EVSE_Supported_ISO1 0;
BA_ "GenSigTimeoutTime_BPCM" SG_ 498 EVSE_Supported_ISO1 0;
BA_ "GenSigTimeoutTime_PPIM" SG_ 498 EVSE_Supported_ISO1 0;
BA_ "GenSigTimeoutTime_HCP" SG_ 498 EVSE_Supported_ISO1 0;
BA_ "GenSigTimeoutTime_SGW" SG_ 498 EVSE_Supported_DIN 0;
BA_ "GenSigTimeoutTime_IDCM" SG_ 498 EVSE_Supported_DIN 0;
BA_ "GenSigTimeoutTime_BPCM" SG_ 498 EVSE_Supported_DIN 0;
BA_ "GenSigTimeoutTime_PPIM" SG_ 498 EVSE_Supported_DIN 0;
BA_ "GenSigTimeoutTime_HCP" SG_ 498 EVSE_Supported_DIN 0;
BA_ "GenSigTimeoutTime_SGW" SG_ 498 CRC_OBCM_VDCM 0;
BA_ "GenSigTimeoutTime_IDCM" SG_ 498 CRC_OBCM_VDCM 0;
BA_ "GenSigTimeoutTime_BPCM" SG_ 498 CRC_OBCM_VDCM 0;
BA_ "GenSigTimeoutTime_PPIM" SG_ 498 CRC_OBCM_VDCM 0;
BA_ "GenSigTimeoutTime_HCP" SG_ 498 CRC_OBCM_VDCM 0;
BA_ "GenSigTimeoutTime_SGW" SG_ 498 EVSE_Supported_SAE 0;
BA_ "GenSigTimeoutTime_IDCM" SG_ 498 EVSE_Supported_SAE 0;
BA_ "GenSigTimeoutTime_BPCM" SG_ 498 EVSE_Supported_SAE 0;
BA_ "GenSigTimeoutTime_PPIM" SG_ 498 EVSE_Supported_SAE 0;
BA_ "GenSigTimeoutTime_HCP" SG_ 498 EVSE_Supported_SAE 0;
BA_ "GenSigTimeoutTime_SGW" SG_ 498 EVSE_Service2_Certificate 0;
BA_ "GenSigTimeoutTime_IDCM" SG_ 498 EVSE_Service2_Certificate 0;
BA_ "GenSigTimeoutTime_BPCM" SG_ 498 EVSE_Service2_Certificate 0;
BA_ "GenSigTimeoutTime_PPIM" SG_ 498 EVSE_Service2_Certificate 0;
BA_ "GenSigTimeoutTime_HCP" SG_ 498 EVSE_Service2_Certificate 0;
BA_ "GenSigTimeoutTime_SGW" SG_ 498 EVSE_OfferedPaymentEIM 0;
BA_ "GenSigTimeoutTime_IDCM" SG_ 498 EVSE_OfferedPaymentEIM 0;
BA_ "GenSigTimeoutTime_BPCM" SG_ 498 EVSE_OfferedPaymentEIM 0;
BA_ "GenSigTimeoutTime_PPIM" SG_ 498 EVSE_OfferedPaymentEIM 0;
BA_ "GenSigTimeoutTime_HCP" SG_ 498 EVSE_OfferedPaymentEIM 0;
BA_ "GenSigTimeoutTime_SGW" SG_ 498 EVSE_OfferedPaymentContract 0;
BA_ "GenSigTimeoutTime_IDCM" SG_ 498 EVSE_OfferedPaymentContract 0;
BA_ "GenSigTimeoutTime_BPCM" SG_ 498 EVSE_OfferedPaymentContract 0;
BA_ "GenSigTimeoutTime_PPIM" SG_ 498 EVSE_OfferedPaymentContract 0;
BA_ "GenSigTimeoutTime_HCP" SG_ 498 EVSE_OfferedPaymentContract 0;
BA_ "GenSigTimeoutTime_SGW" SG_ 498 EVSE_Notification 0;
BA_ "GenSigTimeoutTime_IDCM" SG_ 498 EVSE_Notification 0;
BA_ "GenSigTimeoutTime_BPCM" SG_ 498 EVSE_Notification 0;
BA_ "GenSigTimeoutTime_PPIM" SG_ 498 EVSE_Notification 0;
BA_ "GenSigTimeoutTime_HCP" SG_ 498 EVSE_Notification 0;
BA_ "GenSigTimeoutTime_SGW" SG_ 2564682261 N_PDU_18DDF215 0;
BA_ "GenSigTimeoutTime_IDCM" SG_ 2564682261 N_PDU_18DDF215 0;
BA_ "GenSigTimeoutTime_EVCU2" SG_ 2564682261 N_PDU_18DDF215 0;
BA_ "GenSigTimeoutTime_BPCM" SG_ 2564682261 N_PDU_18DDF215 0;
BA_ "GenSigTimeoutTime_PPIM" SG_ 2564682261 N_PDU_18DDF215 0;
BA_ "GenSigTimeoutTime_HCP" SG_ 2564682261 N_PDU_18DDF215 0;
BA_ "GenSigTimeoutTime_SGW" SG_ 2564682260 N_PDU_18DDF214 0;
BA_ "GenSigTimeoutTime_IDCM" SG_ 2564682260 N_PDU_18DDF214 0;
BA_ "GenSigTimeoutTime_EVCU2" SG_ 2564682260 N_PDU_18DDF214 0;
BA_ "GenSigTimeoutTime_BPCM" SG_ 2564682260 N_PDU_18DDF214 0;
BA_ "GenSigTimeoutTime_PPIM" SG_ 2564682260 N_PDU_18DDF214 0;
BA_ "GenSigTimeoutTime_HCP" SG_ 2564682260 N_PDU_18DDF214 0;
BA_ "GenSigTimeoutTime_SGW" SG_ 2564485396 N_PDU_18DAF114 0;
BA_ "GenSigTimeoutTime_IDCM" SG_ 2564485396 N_PDU_18DAF114 0;
BA_ "GenSigTimeoutTime_EVCU2" SG_ 2564485396 N_PDU_18DAF114 0;
BA_ "GenSigTimeoutTime_BPCM" SG_ 2564485396 N_PDU_18DAF114 0;
BA_ "GenSigTimeoutTime_SGW" SG_ 2564485653 N_PDU_18DAF215 0;
BA_ "GenSigTimeoutTime_IDCM" SG_ 2564485653 N_PDU_18DAF215 0;
BA_ "GenSigTimeoutTime_EVCU2" SG_ 2564485653 N_PDU_18DAF215 0;
BA_ "GenSigTimeoutTime_BPCM" SG_ 2564485653 N_PDU_18DAF215 0;
BA_ "GenSigTimeoutTime_PPIM" SG_ 2564485653 N_PDU_18DAF215 0;
BA_ "GenSigTimeoutTime_HCP" SG_ 2564485653 N_PDU_18DAF215 0;
BA_ "GenSigTimeoutTime_SGW" SG_ 2564485652 N_PDU_18DAF214 0;
BA_ "GenSigTimeoutTime_IDCM" SG_ 2564485652 N_PDU_18DAF214 0;
BA_ "GenSigTimeoutTime_EVCU2" SG_ 2564485652 N_PDU_18DAF214 0;
BA_ "GenSigTimeoutTime_BPCM" SG_ 2564485652 N_PDU_18DAF214 0;
BA_ "GenSigTimeoutTime_PPIM" SG_ 2564485652 N_PDU_18DAF214 0;
BA_ "GenSigTimeoutTime_HCP" SG_ 2564485652 N_PDU_18DAF214 0;
BA_ "GenSigTimeoutTime_SGW" SG_ 2564429297 N_PDU_18DA15F1 0;
BA_ "GenSigTimeoutTime_IDCM" SG_ 2564429297 N_PDU_18DA15F1 0;
BA_ "GenSigTimeoutTime_EVCU2" SG_ 2564429297 N_PDU_18DA15F1 0;
BA_ "GenSigTimeoutTime_BPCM" SG_ 2564429297 N_PDU_18DA15F1 0;
BA_ "GenSigTimeoutTime_SGW" SG_ 2564429041 N_PDU_18DA14F1 0;
BA_ "GenSigTimeoutTime_IDCM" SG_ 2564429041 N_PDU_18DA14F1 0;
BA_ "GenSigTimeoutTime_EVCU2" SG_ 2564429041 N_PDU_18DA14F1 0;
BA_ "GenSigTimeoutTime_BPCM" SG_ 2564429041 N_PDU_18DA14F1 0;
BA_ "GenSigTimeoutTime_SGW" SG_ 2564429298 N_PDU_18DA15F2 0;
BA_ "GenSigTimeoutTime_IDCM" SG_ 2564429298 N_PDU_18DA15F2 0;
BA_ "GenSigTimeoutTime_EVCU2" SG_ 2564429298 N_PDU_18DA15F2 0;
BA_ "GenSigTimeoutTime_BPCM" SG_ 2564429298 N_PDU_18DA15F2 0;
BA_ "GenSigTimeoutTime_PPIM" SG_ 2564429298 N_PDU_18DA15F2 0;
BA_ "GenSigTimeoutTime_HCP" SG_ 2564429298 N_PDU_18DA15F2 0;
BA_ "GenSigTimeoutTime_SGW" SG_ 2564429042 N_PDU_18DA14F2 0;
BA_ "GenSigTimeoutTime_IDCM" SG_ 2564429042 N_PDU_18DA14F2 0;
BA_ "GenSigTimeoutTime_EVCU2" SG_ 2564429042 N_PDU_18DA14F2 0;
BA_ "GenSigTimeoutTime_BPCM" SG_ 2564429042 N_PDU_18DA14F2 0;
BA_ "GenSigTimeoutTime_PPIM" SG_ 2564429042 N_PDU_18DA14F2 0;
BA_ "GenSigTimeoutTime_HCP" SG_ 2564429042 N_PDU_18DA14F2 0;
BA_ "GenSigTimeoutTime_IDCM" SG_ 244 BMS_HV_InternalVoltage 0;
BA_ "GenSigTimeoutTime_EVCU2" SG_ 244 BMS_HV_InternalVoltage 0;
BA_ "GenSigTimeoutTime_BPCM" SG_ 244 BMS_HV_InternalVoltage 0;
BA_ "GenSigTimeoutTime_IDCM" SG_ 244 BMS_HV_Current 0;
BA_ "GenSigTimeoutTime_EVCU2" SG_ 244 BMS_HV_Current 0;
BA_ "GenSigTimeoutTime_BPCM" SG_ 244 BMS_HV_Current 0;
BA_ "GenSigTimeoutTime_IDCM" SG_ 244 BMS_HV_Battery_GFD_Sts 0;
BA_ "GenSigTimeoutTime_EVCU2" SG_ 244 BMS_HV_Battery_GFD_Sts 0;
BA_ "GenSigTimeoutTime_BPCM" SG_ 244 BMS_HV_Battery_GFD_Sts 0;
BA_ "GenSigTimeoutTime_IDCM" SG_ 244 BMS_HV_Temperature_Min 0;
BA_ "GenSigTimeoutTime_EVCU2" SG_ 244 BMS_HV_Temperature_Min 0;
BA_ "GenSigTimeoutTime_BPCM" SG_ 244 BMS_HV_Temperature_Min 0;
BA_ "GenSigTimeoutTime_IDCM" SG_ 244 BMS_HV_Temperature_Max 0;
BA_ "GenSigTimeoutTime_EVCU2" SG_ 244 BMS_HV_Temperature_Max 0;
BA_ "GenSigTimeoutTime_BPCM" SG_ 244 BMS_HV_Temperature_Max 0;
BA_ "GenSigTimeoutTime_SGW" SG_ 244 ImpactHardwireV 0;
BA_ "GenSigTimeoutTime_IDCM" SG_ 244 ImpactHardwireV 0;
BA_ "GenSigTimeoutTime_BPCM" SG_ 244 ImpactHardwireV 0;
BA_ "GenSigTimeoutTime_PPIM" SG_ 244 ImpactHardwireV 0;
BA_ "GenSigTimeoutTime_HCP" SG_ 244 ImpactHardwireV 0;
BA_ "GenSigTimeoutTime_SGW" SG_ 244 ImpactHardwire 0;
BA_ "GenSigTimeoutTime_IDCM" SG_ 244 ImpactHardwire 0;
BA_ "GenSigTimeoutTime_BPCM" SG_ 244 ImpactHardwire 0;
BA_ "GenSigTimeoutTime_PPIM" SG_ 244 ImpactHardwire 0;
BA_ "GenSigTimeoutTime_HCP" SG_ 244 ImpactHardwire 0;
VAL_ 1579 HVBatteryVoltage_MinCal 511 "SNA" ;
VAL_ 1579 HVBatteryVoltage_MaxCal 511 "SNA" ;
VAL_ 1579 HVBatteryCurrent_MaxCal 255 "SNA" ;
VAL_ 1579 ChargeSystemFaultReason 0 "No_Failure" 1 "Failure1" 2 "Failure2" 3 "Failure3" 4 "Failure4" 5 "Failure5" 6 "Failure6" 7 "Failure7" 8 "Failure8" 9 "Failure9" 10 "Failure10" 11 "Failure11" 12 "Failure12" 13 "Failure13" 14 "Failure14" 15 "Failure15" 16 "Failure16" 17 "Failure17" 18 "Failure18" 19 "Failure19" 20 "Failure20" 21 "Failure21" 22 "Failure22" 23 "Failure23" 24 "Failure24" 25 "Failure25" 26 "Failure26" 27 "Failure27" 28 "Failure28" 29 "Failure29" 30 "Failure30" 31 "Failure31" 32 "Failure32" 33 "Failure33" 34 "Failure34" 35 "Failure35" 36 "Failure36" 37 "Failure37" 38 "Failure38" 39 "Failure39" 40 "Failure40" 41 "Failure41" 42 "Failure42" 43 "Failure43" 44 "Failure44" 45 "Failure45" 46 "Failure46" 47 "Failure47" 48 "Failure48" 49 "Failure49" 50 "Failure50" 51 "Failure51" 52 "Failure52" 53 "Failure53" 54 "Failure54" 55 "Failure55" 56 "Failure56" 57 "Failure57" 58 "Failure58" 59 "Failure59" 60 "Failure60" 61 "Failure61" 62 "Failure62" 63 "Failure63" 64 "Failure64" 65 "Failure65" 66 "Failure66" 67 "Failure67" 68 "Failure68" 69 "Failure69" 70 "Failure70" 71 "Failure71" 72 "Failure72" 73 "Failure73" 74 "Failure74" 75 "Failure75" 76 "Failure76" 77 "Failure77" 78 "Failure78" 79 "Failure79" 80 "Failure80" 81 "Failure81" 82 "Failure82" 83 "Failure83" 84 "Failure84" 85 "Failure85" 86 "Failure86" 87 "Failure87" 88 "Failure88" 89 "Failure89" 90 "Failure90" 91 "Failure91" 92 "Failure92" 93 "Failure93" 94 "Failure94" 95 "Failure95" 96 "Failure96" 97 "Failure97" 98 "Failure98" 99 "Failure99" 100 "Failure100" 101 "Failure101" 102 "Failure102" 103 "Failure103" 104 "Failure104" 105 "Failure105" 106 "Failure106" 107 "Failure107" 108 "Failure108" 109 "Failure109" 110 "Failure110" 111 "Failure111" 112 "Failure112" 113 "Failure113" 114 "Failure114" 115 "Failure115" 116 "Failure116" 117 "Failure117" 118 "Failure118" 119 "Failure119" 120 "Failure120" 121 "Failure121" 122 "Failure122" 123 "Failure123" 124 "Failure124" 125 "Failure125" 126 "Failure126" 127 "Failure127" 128 "Failure128" 129 "Failure129" 130 "Failure130" 131 "Failure131" 132 "Failure132" 133 "Failure133" 134 "Failure134" 135 "Failure135" 136 "Failure136" 137 "Failure137" 138 "Failure138" 139 "Failure139" 140 "Failure140" 141 "Failure141" 142 "Failure142" 143 "Failure143" 144 "Failure144" 145 "Failure145" 146 "Failure146" 147 "Failure147" 148 "Failure148" 149 "Failure149" 150 "Failure150" 151 "Failure151" 152 "Failure152" 153 "Failure153" 154 "Failure154" 155 "Failure155" 156 "Failure156" 157 "Failure157" 158 "Failure158" 159 "Failure159" 160 "Failure160" 161 "Failure161" 162 "Failure162" 163 "Failure163" 164 "Failure164" 165 "Failure165" 166 "Failure166" 167 "Failure167" 168 "Failure168" 169 "Failure169" 170 "Failure170" 171 "Failure171" 172 "Failure172" 173 "Failure173" 174 "Failure174" 175 "Failure175" 176 "Failure176" 177 "Failure177" 178 "Failure178" 179 "Failure179" 180 "Failure180" 181 "Failure181" 182 "Failure182" 183 "Failure183" 184 "Failure184" 185 "Failure185" 186 "Failure186" 187 "Failure187" 188 "Failure188" 189 "Failure189" 190 "Failure190" 191 "Failure191" 192 "Failure192" 193 "Failure193" 194 "Failure194" 195 "Failure195" 196 "Failure196" 197 "Failure197" 198 "Failure198" 199 "Failure199" 200 "Failure200" 201 "Failure201" 202 "Failure202" 203 "Failure203" 204 "Failure204" 205 "Failure205" 206 "Failure206" 207 "Failure207" 208 "Failure208" 209 "Failure209" 210 "Failure210" 211 "Failure211" 212 "Failure212" 213 "Failure213" 214 "Failure214" 215 "Failure215" 216 "Failure216" 217 "Failure217" 218 "Failure218" 219 "Failure219" 220 "Failure220" 221 "Failure221" 222 "Failure222" 223 "Failure223" 224 "Failure224" 225 "Failure225" 226 "Failure226" 227 "Failure227" 228 "Failure228" 229 "Failure229" 230 "Failure230" 231 "Failure231" 232 "Failure232" 233 "Failure233" 234 "Failure234" 235 "Failure235" 236 "Failure236" 237 "Failure237" 238 "Failure238" 239 "Failure239" 240 "Failure240" 241 "Failure241" 242 "Failure242" 243 "Failure243" 244 "Failure244" 245 "Failure245" 246 "Failure246" 247 "Failure247" 248 "Failure248" 249 "Failure249" 250 "Failure250" 251 "Failure251" 252 "Failure252" 253 "Failure253" 254 "Failure254" 255 "SNA" ;
VAL_ 1579 ACCurrent_MaxCal 511 "SNA" ;
VAL_ 1579 ChargingLevel 0 "Default_NoLevel" 1 "Level_1_AC" 2 "Level_2_AC" 3 "Level_3_AC" 4 "Level_1_DC" 5 "Level_2_DC" 6 "PlugInNotDet" 7 "PPI_1_No_Drive" 8 "PPI_2_OK_Drive" 15 "SNA" ;
VAL_ 1579 OBCM_PLUG_STS 0 "NOT_PLUG_IN" 1 "PLUG_IN" ;
VAL_ 1579 VDCM_UDCChrgr 65535 "SNA" ;
VAL_ 1579 VDCM_IDCChrgr 65535 "SNA" ;
VAL_ 1579 ChargeSystemSts 0 "NotCharging" 1 "Charging" 2 "ChargeInterrupted" 3 "ChargeComplete" 4 "ChargeError" 7 "SNA" ;
VAL_ 1579 ChargeSystemFault 0 "No_Fail" 1 "Fail" ;
VAL_ 478 LVDC_VoltageSetpoint 255 "SNA" ;
VAL_ 478 LVDC_SystemVoltageAct 511 "SNA" ;
VAL_ 478 LVDC_CurrentSetpoint 511 "SNA" ;
VAL_ 478 HVInverterVoltage_Rational 511 "SNA" ;
VAL_ 478 HVDC_VoltageSetpoint 511 "SNA" ;
VAL_ 478 HVDC_CurrentSetpoint 255 "SNA" ;
VAL_ 478 EchargeSOCRange_ePT 127 "SNA" ;
VAL_ 478 OBC_ModeRequest 0 "IDLE" 1 "HEATER" 2 "CHARGE" 3 "AC_PNL" 4 "AC_GRD_Sync" 5 "AC_GRD_Synth" 7 "SNA" ;
VAL_ 478 OBC_ControlMethod 0 "CURRENT" 1 "VOLTAGE" 2 "POWER" 3 "SNA" ;
VAL_ 478 MainHV_ContactorCommand 0 "OPN" 1 "CLS" 2 "IMPCT_OPN" 3 "FAST_OPN" 7 "INV" ;
VAL_ 478 J1772_CloseS2 0 "OPN" 1 "CLS" ;
VAL_ 478 HVInverterVoltage_RationalV 0 "Valid" 1 "Not_Valid" ;
VAL_ 478 HVBatCoolantLevelLow 0 "FALSE" 1 "TRUE" 3 "SNA" ;
VAL_ 478 DCDC_OperationModeEnable 0 "Default" 1 "Buck_CV" 2 "Buck_CC" 3 "Buck_CP" 4 "Buck_Special" 5 "Boost" 6 "Precharge" 7 "Discharge" 8 "Off" 15 "SNA" ;
VAL_ 478 ClearLegislatedDiagInfo 0 "FALSE" 1 "TRUE" ;
VAL_ 478 OBC_OperativeModeReq 0 "IDLE" 1 "HEATER" 2 "CHARGE" 3 "Discharge" 4 "AC_GRD_Sync" 5 "AC_GRD_Synth" 6 "CHARGE_INTERRUPTED" 7 "NOT_CHARGING" 15 "SNA" ;
VAL_ 478 HV_Volt_Min_Thrsh 2047 "SNA" ;
VAL_ 478 HV_Volt_Max_Thrsh 2047 "SNA" ;
VAL_ 478 DC_Curr_Max_Thrsh 1023 "SNA" ;
VAL_ 478 ChargeEnable 0 "Charge_Not_Enabled" 1 "Charge_Enabled" 3 "SNA" ;
VAL_ 478 AC_Curr_Min_Thrsh 1023 "SNA" ;
VAL_ 478 AC_Curr_Max_Thrsh 1023 "SNA" ;
VAL_ 478 VDCM_StsWldgReq 0 "No_WeldingCheck_Req" 1 "WeldingCheck_Req" ;
VAL_ 478 VDCM_SessnStopReq 0 "No_SessStop_Req" 1 "SessStop_Req" ;
VAL_ 478 VDCM_StsSWWldgReq 0 "No_SWWeldingCheck_Req" 1 "SWWeldingCheck_Req" ;
VAL_ 1578 OBC_IdleTimeSec 65535 "SNA" ;
VAL_ 1578 OBC_IdleTimeMin 65535 "SNA" ;
VAL_ 1578 OBC_ChargeTimeSec 65535 "SNA" ;
VAL_ 1578 OBC_ChargeTimeMin 65535 "SNA" ;
VAL_ 1578 Charging_WHr 65535 "SNA" ;
VAL_ 1578 OnboardChargerReady 0 "WU_FLT" 1 "OFF" 2 "ON" 3 "SNA" ;
VAL_ 1578 OnboardChargerMode 0 "IDLE" 1 "HEATER" 2 "CHARGE" 3 "Discharge" 4 "AC_GRD" 5 "UTC" 6 "STOP" 7 "FORCED_SHUTDOWN" 8 "CHARGE_INTERRUPTED" 9 "NOT_CHARGING" ;
VAL_ 1578 OBC_WakeReason 0 "NOT_DETECTED" 1 "Master_WU" 2 "EVSE_PlugIn" 3 "Pilot_PWM" 4 "Prox_in" 5 "EVSE_UnPlug" 6 "s3_open" 7 "BPCM_WU" ;
VAL_ 1578 OBC_GenericFailSts 0 "Fail_Not_Present" 1 "Fail_Present" ;
VAL_ 1578 OBC_FaultReason 0 "No_Fault" 1 "COMM_FAULT" 2 "EVSE_InputCirFault" 3 "Batt_12vFault" 4 "OBCM_LV_Fault" 5 "OBCM_HV_Fault" 6 "Extern_Dev_Fault" 7 "WakeupCircuitFault" 8 "Impact" 9 "DischargeFault" 127 "SNA" ;
VAL_ 1578 OBC_ChargingFaultSts 0 "No_Performed" 1 "No_Fault" 2 "OBCM_ECU_HW_Error" 3 "OBCM_Modules_Error" 4 "Gnd_Fault" 5 "Temperature_Error" 6 "OverCurrent_Error" 7 "OverVoltage_Error" ;
VAL_ 1578 ACplug_PwrMax 65535 "SNA" ;
VAL_ 1578 OBCM_PrechargeSts 0 "Not_Requested" 1 "Ongoing" 2 "Completed" 3 "Fail" ;
VAL_ 1578 ChrgFailSts 0 "No_Fault" 1 "Flt_charging_allowed" 2 "Flt_charging_inhibited" 3 "Flt_charging_terminated" 4 "Flt_AC_failure_DC_chg_allwd" 7 "SNA" ;
VAL_ 1372 OBC_Temp4 255 "SNA" ;
VAL_ 1372 OBC_Temp3 255 "SNA" ;
VAL_ 1372 OBC_Temp2 255 "SNA" ;
VAL_ 1372 OBC_Temp1 255 "SNA" ;
VAL_ 2654339170 GenericFailSts_FD03_HCP 0 "No_Fail_Present" 1 "Fail_Present" ;
VAL_ 2654339170 EOL_FD03_HCP 0 "No_EOL_Programming" 1 "EOL_Programming" ;
VAL_ 2654339170 CurrentFailSts_FD03_HCP 0 "No_Fail_Present" 1 "Fail_Present" ;
VAL_ 2654339170 WakeupSource_FD03_HCP 0 "No_Wakeup" ;
VAL_ 2654339170 PreviousCanNMState_FD03_HCP 0 "Uninitialized State" 1 "Bus-Sleep State" 2 "Prepare-Bus State" 3 "Ready-Sleep State" 4 "Normal Operation State" 5 "Repeat Message State" 6 "Synchronize State" 7 "Offline State" ;
VAL_ 2654339170 DES_FD03_HCP 0 "Error_Active_state" 1 "Error_passive_warning_state" 2 "Bus_off_state" 3 "Not_used" ;
VAL_ 2654339170 CurrentCanNMState_FD03_HCP 0 "Uninitialized State" 1 "Bus-Sleep State" 2 "Prepare-Bus State" 3 "Ready-Sleep State" 4 "Normal Operation State" 5 "Repeat Message State" 6 "Synchronize State" 7 "Offline State" ;
VAL_ 1460 FOTA_Status 0 "No FOTA Event" 1 "Downloading Package from Backend" 2 "Passing Images to Big Target ECUs" 3 "Waiting for HMI Acceptance" 4 "Installing FOTA Updated" 5 "Successful FOTA Update" 6 "FOTA Failure Rollback Successful" 7 "FOTA Failure Complete" 8 "Build Vehicle Library" 9 "Check Campaign Availability" 10 "Check Download Conditions" 11 "Validate Vehicle Package" 12 "Double Check Manifest" 13 "Initiate Authenticated Diagnostic session" 14 "Ready_State" 15 "Rollback" ;
VAL_ 1374 HVBatPackVoltage_MaxAllowedV 0 "Valid" 1 "Not_Valid" ;
VAL_ 1374 HVBatCellVoltage_MinAllowedV 0 "Valid" 1 "Not_Valid" ;
VAL_ 1374 HVBatCellVoltage_MinAllowed 4095 "SNA" ;
VAL_ 1374 HVBatCellVoltage_MaxAllowedV 0 "Valid" 1 "Not_Valid" ;
VAL_ 1374 HVBatCellVoltage_MaxAllowed 4095 "SNA" ;
VAL_ 1374 HVBatCellVoltage_LowThreshold 8191 "SNA" ;
VAL_ 1374 HVBatCellVoltage_HighThreshold 8191 "SNA" ;
VAL_ 1374 HVBatCapacity_AmpHrV 0 "Valid" 1 "Not_Valid" ;
VAL_ 1374 HVBatCapacity_AmpHr 2047 "SNA" ;
VAL_ 1374 HVBatRemainingAhCapacity 2047 "SNA" ;
VAL_ 1374 HVBatDischargeAmpHrs 16777215 "SNA" ;
VAL_ 1374 HVBatChargeAmpHrs 16777215 "SNA" ;
VAL_ 1374 BSGPackVoltage_MaxAllowed 127 "SNA" ;
VAL_ 1038 Precharge_Closed 0 "FALSE" 1 "TRUE" ;
VAL_ 1038 Positive_Main_Closed 0 "FALSE" 1 "TRUE" ;
VAL_ 1038 Negative_Main_Closed 0 "FALSE" 1 "TRUE" ;
VAL_ 1038 HBCO_TempSensorRationality 0 "FALSE" 1 "TRUE" ;
VAL_ 1038 HBCO_Sensor_Fault 0 "FALSE" 1 "TRUE" ;
VAL_ 1038 HBCO_PackUndertemp 0 "FALSE" 1 "TRUE" ;
VAL_ 1038 HBCO_PackOvertemp 0 "FALSE" 1 "TRUE" ;
VAL_ 1038 HBCO_OverCurrent 0 "FALSE" 1 "TRUE" ;
VAL_ 1038 HBCO_Micro_Failure 0 "FALSE" 1 "TRUE" ;
VAL_ 1038 HBCO_Main_Fuse_Failure 0 "FALSE" 1 "TRUE" ;
VAL_ 1038 HBCO_Isolation_Fault 0 "FALSE" 1 "TRUE" ;
VAL_ 1038 HBCO_Internal_CommFault 0 "FALSE" 1 "TRUE" ;
VAL_ 1038 HBCO_Impact_Detected 0 "FALSE" 1 "TRUE" ;
VAL_ 1038 HBCO_HVIL_Failure 0 "FALSE" 1 "TRUE" ;
VAL_ 1038 HBCO_External_CommFault 0 "FALSE" 1 "TRUE" ;
VAL_ 1038 HBCO_CellUndervoltage 0 "FALSE" 1 "TRUE" ;
VAL_ 1038 HBCO_CellOvervoltage 0 "FALSE" 1 "TRUE" ;
VAL_ 1038 HBCO_12V_Low 0 "FALSE" 1 "TRUE" ;
VAL_ 1038 HBCO_12V_High 0 "FALSE" 1 "TRUE" ;
VAL_ 1038 HBCNC_TempSensorRationality 0 "FALSE" 1 "TRUE" ;
VAL_ 1038 HBCNC_SOH_Failure 0 "FALSE" 1 "TRUE" ;
VAL_ 1038 HBCNC_Sensor_Failure 0 "FALSE" 1 "TRUE" ;
VAL_ 1038 HBCNC_Precharge_Failure 0 "FALSE" 1 "TRUE" ;
VAL_ 1038 HBCNC_PackUndervoltage 0 "FALSE" 1 "TRUE" ;
VAL_ 1038 HBCNC_PackUndertemp 0 "FALSE" 1 "TRUE" ;
VAL_ 1038 HBCNC_PackOvervoltage 0 "FALSE" 1 "TRUE" ;
VAL_ 1038 HBCNC_PackOvertemp 0 "FALSE" 1 "TRUE" ;
VAL_ 1038 HBCNC_Micro_Failure 0 "FALSE" 1 "TRUE" ;
VAL_ 1038 HBCNC_Main_Fuse_Failure 0 "FALSE" 1 "TRUE" ;
VAL_ 1038 HBCNC_Isolation_Fault 0 "FALSE" 1 "TRUE" ;
VAL_ 1038 HBCNC_Internal_CommFault 0 "FALSE" 1 "TRUE" ;
VAL_ 1038 HBCNC_Impact_Detected 0 "FALSE" 1 "TRUE" ;
VAL_ 1038 HBCNC_External_CommFault 0 "FALSE" 1 "TRUE" ;
VAL_ 1038 HBCNC_EEPROM_Fault 0 "FALSE" 1 "TRUE" ;
VAL_ 1038 HBCNC_Contactors_Welded 0 "FALSE" 1 "TRUE" ;
VAL_ 1038 HBCNC_CellUndervoltage 0 "FALSE" 1 "TRUE" ;
VAL_ 1038 HBCNC_CellOvervoltage 0 "FALSE" 1 "TRUE" ;
VAL_ 1038 HBCNC_12V_Low 0 "FALSE" 1 "TRUE" ;
VAL_ 1038 HBCNC_12V_High 0 "FALSE" 1 "TRUE" ;
VAL_ 1038 BPCM_DTC_Status6 0 "Not_Supported" 1 "Critically_Disabled" 2 "No_Status" 3 "Diag_Passed" 4 "Diag_Failed" 5 "Reset_DTC" 6 "Unused" 7 "SNA" ;
VAL_ 1038 BPCM_DTC_Status5 0 "Not_Supported" 1 "Critically_Disabled" 2 "No_Status" 3 "Diag_Passed" 4 "Diag_Failed" 5 "Reset_DTC" 6 "Unused" 7 "SNA" ;
VAL_ 1038 BPCM_DTC_Status4 0 "Not_Supported" 1 "Critically_Disabled" 2 "No_Status" 3 "Diag_Passed" 4 "Diag_Failed" 5 "Reset_DTC" 6 "Unused" 7 "SNA" ;
VAL_ 1038 BPCM_DTC_Status3 0 "Not_Supported" 1 "Critically_Disabled" 2 "No_Status" 3 "Diag_Passed" 4 "Diag_Failed" 5 "Reset_DTC" 6 "Unused" 7 "SNA" ;
VAL_ 1038 BPCM_DTC_Status2 0 "Not_Supported" 1 "Critically_Disabled" 2 "No_Status" 3 "Diag_Passed" 4 "Diag_Failed" 5 "Reset_DTC" 6 "Unused" 7 "SNA" ;
VAL_ 1038 BPCM_DTC_Status1 0 "Not_Supported" 1 "Critically_Disabled" 2 "No_Status" 3 "Diag_Passed" 4 "Diag_Failed" 5 "Reset_DTC" 6 "Unused" 7 "SNA" ;
VAL_ 1038 BPCM_CalibrationID 63 "SNA" ;
VAL_ 1038 BPCM_Odometer 16777215 "SNA" ;
VAL_ 1852 HVBatCellVoltage_Cell192 8191 "SNA" ;
VAL_ 1852 HVBatCellVoltage_Cell191 8191 "SNA" ;
VAL_ 1852 HVBatCellVoltage_Cell190 8191 "SNA" ;
VAL_ 1852 HVBatCellVoltage_Cell216 8191 "SNA" ;
VAL_ 1852 HVBatCellVoltage_Cell215 8191 "SNA" ;
VAL_ 1852 HVBatCellVoltage_Cell214 8191 "SNA" ;
VAL_ 1852 HVBatCellVoltage_Cell213 8191 "SNA" ;
VAL_ 1852 HVBatCellVoltage_Cell212 8191 "SNA" ;
VAL_ 1852 HVBatCellVoltage_Cell211 8191 "SNA" ;
VAL_ 1852 HVBatCellVoltage_Cell210 8191 "SNA" ;
VAL_ 1852 HVBatCellVoltage_Cell209 8191 "SNA" ;
VAL_ 1852 HVBatCellVoltage_Cell208 8191 "SNA" ;
VAL_ 1852 HVBatCellVoltage_Cell207 8191 "SNA" ;
VAL_ 1852 HVBatCellVoltage_Cell206 8191 "SNA" ;
VAL_ 1852 HVBatCellVoltage_Cell205 8191 "SNA" ;
VAL_ 1852 HVBatCellVoltage_Cell204 8191 "SNA" ;
VAL_ 1852 HVBatCellVoltage_Cell203 8191 "SNA" ;
VAL_ 1852 HVBatCellVoltage_Cell202 8191 "SNA" ;
VAL_ 1852 HVBatCellVoltage_Cell201 8191 "SNA" ;
VAL_ 1852 HVBatCellVoltage_Cell200 8191 "SNA" ;
VAL_ 1852 HVBatCellVoltage_Cell198 8191 "SNA" ;
VAL_ 1852 HVBatCellVoltage_Cell197 8191 "SNA" ;
VAL_ 1852 HVBatCellVoltage_Cell196 8191 "SNA" ;
VAL_ 1852 HVBatCellVoltage_Cell195 8191 "SNA" ;
VAL_ 1852 HVBatCellVoltage_Cell194 8191 "SNA" ;
VAL_ 1852 HVBatCellVoltage_Cell193 8191 "SNA" ;
VAL_ 1851 HVBatCellVoltage_Cell189 8191 "SNA" ;
VAL_ 1851 HVBatCellVoltage_Cell188 8191 "SNA" ;
VAL_ 1851 HVBatCellVoltage_Cell187 8191 "SNA" ;
VAL_ 1851 HVBatCellVoltage_Cell186 8191 "SNA" ;
VAL_ 1851 HVBatCellVoltage_Cell185 8191 "SNA" ;
VAL_ 1851 HVBatCellVoltage_Cell184 8191 "SNA" ;
VAL_ 1851 HVBatCellVoltage_Cell183 8191 "SNA" ;
VAL_ 1851 HVBatCellVoltage_Cell182 8191 "SNA" ;
VAL_ 1851 HVBatCellVoltage_Cell181 8191 "SNA" ;
VAL_ 1851 HVBatCellVoltage_Cell180 8191 "SNA" ;
VAL_ 1851 HVBatCellVoltage_Cell179 8191 "SNA" ;
VAL_ 1851 HVBatCellVoltage_Cell178 8191 "SNA" ;
VAL_ 1851 HVBatCellVoltage_Cell177 8191 "SNA" ;
VAL_ 1851 HVBatCellVoltage_Cell176 8191 "SNA" ;
VAL_ 1851 HVBatCellVoltage_Cell175 8191 "SNA" ;
VAL_ 1851 HVBatCellVoltage_Cell174 8191 "SNA" ;
VAL_ 1851 HVBatCellVoltage_Cell173 8191 "SNA" ;
VAL_ 1851 HVBatCellVoltage_Cell172 8191 "SNA" ;
VAL_ 1851 HVBatCellVoltage_Cell171 8191 "SNA" ;
VAL_ 1851 HVBatCellVoltage_Cell170 8191 "SNA" ;
VAL_ 1851 HVBatCellVoltage_Cell169 8191 "SNA" ;
VAL_ 1851 HVBatCellVoltage_Cell168 8191 "SNA" ;
VAL_ 1851 HVBatCellVoltage_Cell167 8191 "SNA" ;
VAL_ 1851 HVBatCellVoltage_Cell166 8191 "SNA" ;
VAL_ 1851 HVBatCellVoltage_Cell165 8191 "SNA" ;
VAL_ 1851 HVBatCellVoltage_Cell164 8191 "SNA" ;
VAL_ 1851 HVBatCellVoltage_Cell163 8191 "SNA" ;
VAL_ 1850 HVBatCellVoltage_Cell162 8191 "SNA" ;
VAL_ 1850 HVBatCellVoltage_Cell161 8191 "SNA" ;
VAL_ 1850 HVBatCellVoltage_Cell160 8191 "SNA" ;
VAL_ 1850 HVBatCellVoltage_Cell159 8191 "SNA" ;
VAL_ 1850 HVBatCellVoltage_Cell158 8191 "SNA" ;
VAL_ 1850 HVBatCellVoltage_Cell157 8191 "SNA" ;
VAL_ 1850 HVBatCellVoltage_Cell156 8191 "SNA" ;
VAL_ 1850 HVBatCellVoltage_Cell155 8191 "SNA" ;
VAL_ 1850 HVBatCellVoltage_Cell154 8191 "SNA" ;
VAL_ 1850 HVBatCellVoltage_Cell153 8191 "SNA" ;
VAL_ 1850 HVBatCellVoltage_Cell152 8191 "SNA" ;
VAL_ 1850 HVBatCellVoltage_Cell151 8191 "SNA" ;
VAL_ 1850 HVBatCellVoltage_Cell150 8191 "SNA" ;
VAL_ 1850 HVBatCellVoltage_Cell149 8191 "SNA" ;
VAL_ 1850 HVBatCellVoltage_Cell148 8191 "SNA" ;
VAL_ 1850 HVBatCellVoltage_Cell147 8191 "SNA" ;
VAL_ 1850 HVBatCellVoltage_Cell146 8191 "SNA" ;
VAL_ 1850 HVBatCellVoltage_Cell145 8191 "SNA" ;
VAL_ 1850 HVBatCellVoltage_Cell144 8191 "SNA" ;
VAL_ 1850 HVBatCellVoltage_Cell143 8191 "SNA" ;
VAL_ 1850 HVBatCellVoltage_Cell142 8191 "SNA" ;
VAL_ 1850 HVBatCellVoltage_Cell141 8191 "SNA" ;
VAL_ 1850 HVBatCellVoltage_Cell140 8191 "SNA" ;
VAL_ 1850 HVBatCellVoltage_Cell139 8191 "SNA" ;
VAL_ 1850 HVBatCellVoltage_Cell138 8191 "SNA" ;
VAL_ 1850 HVBatCellVoltage_Cell137 8191 "SNA" ;
VAL_ 1850 HVBatCellVoltage_Cell136 8191 "SNA" ;
VAL_ 1849 HVBatCellVoltage_Cell135 8191 "SNA" ;
VAL_ 1849 HVBatCellVoltage_Cell134 8191 "SNA" ;
VAL_ 1849 HVBatCellVoltage_Cell133 8191 "SNA" ;
VAL_ 1849 HVBatCellVoltage_Cell132 8191 "SNA" ;
VAL_ 1849 HVBatCellVoltage_Cell131 8191 "SNA" ;
VAL_ 1849 HVBatCellVoltage_Cell130 8191 "SNA" ;
VAL_ 1849 HVBatCellVoltage_Cell129 8191 "SNA" ;
VAL_ 1849 HVBatCellVoltage_Cell128 8191 "SNA" ;
VAL_ 1849 HVBatCellVoltage_Cell127 8191 "SNA" ;
VAL_ 1849 HVBatCellVoltage_Cell126 8191 "SNA" ;
VAL_ 1849 HVBatCellVoltage_Cell125 8191 "SNA" ;
VAL_ 1849 HVBatCellVoltage_Cell124 8191 "SNA" ;
VAL_ 1849 HVBatCellVoltage_Cell123 8191 "SNA" ;
VAL_ 1849 HVBatCellVoltage_Cell122 8191 "SNA" ;
VAL_ 1849 HVBatCellVoltage_Cell121 8191 "SNA" ;
VAL_ 1849 HVBatCellVoltage_Cell120 8191 "SNA" ;
VAL_ 1849 HVBatCellVoltage_Cell119 8191 "SNA" ;
VAL_ 1849 HVBatCellVoltage_Cell118 8191 "SNA" ;
VAL_ 1849 HVBatCellVoltage_Cell117 8191 "SNA" ;
VAL_ 1849 HVBatCellVoltage_Cell116 8191 "SNA" ;
VAL_ 1849 HVBatCellVoltage_Cell115 8191 "SNA" ;
VAL_ 1849 HVBatCellVoltage_Cell114 8191 "SNA" ;
VAL_ 1849 HVBatCellVoltage_Cell113 8191 "SNA" ;
VAL_ 1849 HVBatCellVoltage_Cell112 8191 "SNA" ;
VAL_ 1849 HVBatCellVoltage_Cell111 8191 "SNA" ;
VAL_ 1849 HVBatCellVoltage_Cell110 8191 "SNA" ;
VAL_ 1849 HVBatCellVoltage_Cell109 8191 "SNA" ;
VAL_ 502 HVCMS_ServiceScope 65535 "SNA" ;
VAL_ 502 HVCMS_ReadyToChargeState 0 "Not_Ready" 1 "Ready" ;
VAL_ 502 HVCMS_Protocol_Entry3 65535 "SNA" ;
VAL_ 502 HVCMS_Protocol_Entry2 65535 "SNA" ;
VAL_ 502 HVCMS_Protocol_Entry1 65535 "SNA" ;
VAL_ 502 HVCMS_EVTargetVoltage 16383 "SNA" ;
VAL_ 502 HVCMS_EVTargetCurrent 1023 "SNA" ;
VAL_ 502 HVCMS_EVRESS_SOC 4095 "SNA" ;
VAL_ 502 HVCMS_EVReady 0 "Not_Ready" 1 "Ready" ;
VAL_ 502 HVCMS_EVMax_V_Limit 16383 "SNA" ;
VAL_ 502 HVCMS_EVMax_P_Limit 16777215 "SNA" ;
VAL_ 502 HVCMS_EVMax_I_Limit 1023 "SNA" ;
VAL_ 502 HVCMS_EVEnergyCapacity 131071 "SNA" ;
VAL_ 502 HVCMS_ChargingComplete 0 "Not_Completed" 1 "Completed" ;
VAL_ 502 HVCMS_BulkChargingComplete 0 "Not_Completed" 1 "Completed" ;
VAL_ 502 VDCM_TypeCNegotiationSts 0 "Not_Requested" 1 "Ongoing" 2 "OK" 3 "Not_OK" ;
VAL_ 502 HVCMS_EVEnergyRequest 131071 "SNA" ;
VAL_ 502 OBCM_OutVoltageSyncTgt 1023 "SNA" ;
VAL_ 502 HVCMS_ServiceCategory 0 "No_Service" 1 "EV_charging" 2 "Internet" 3 "VAS" 4 "BPT_Service" 5 "WPT_Service" 6 "ACDC_Service" 7 "Contract_Certificate" 8 "EVSEInformation" 15 "SNA" ;
VAL_ 502 HVCMS_SelectedPaymentOptn 0 "No payment selected" 1 "External Payment" 2 "Contract" 3 "SNA" ;
VAL_ 502 HVCMS_SelectedEnergyTransferType 0 "No_energy_transfer_type" 1 "AC_single_phase_core" 2 "AC_three_phase_core" 3 "DC_core" 4 "DC_Extended" 5 "DC_combo_core" 6 "DC_unique" 15 "SNA" ;
VAL_ 502 HVCMS_RemaningTimeToFullSOC 65535 "SNA" ;
VAL_ 502 HVCMS_RemaningTimeToBulkSOC 65535 "SNA" ;
VAL_ 502 HVCMS_EVErrorCode 0 "No_error" 1 "FAILED_RESSTTemperatureInhibit" 2 "FAILED_EVShiftPosition" 3 "FAILED_ChargerConnectorLockFault" 4 "FAILED_EVRESSMalfunction" 5 "FAILED_ChargingCurrentDifferential" 6 "FAILED_ChargingcurrentvoltageOutOfRange" 7 "Failed_InletHot" 8 "FAILED_ChargingSystemIncompatibility" 15 "SNA" ;
VAL_ 498 HVCMS_EVSEPresentVoltage 16383 "SNA" ;
VAL_ 498 HVCMS_EVSEPeakCurrentRipple 1023 "SNA" ;
VAL_ 498 HVCMS_EVSEMinCurrentLimit 1023 "SNA" ;
VAL_ 498 HVCMS_EVSEMaxPowerLimit 16777215 "SNA" ;
VAL_ 498 HVCMS_EVSEMaxCurrentLimit 1023 "SNA" ;
VAL_ 498 HVCMS_EVSECurrRegulationTol 1023 "SNA" ;
VAL_ 498 HVCMS_EnergyToBeDelivered 131071 "SNA" ;
VAL_ 498 EVSE_IsolationSts 0 "GFD_Not_Performed" 1 "GFD_Ok" 2 "GFD_Fail" 3 "GFD_Invalid" 4 "GFD_Warning" 7 "SNA" ;
VAL_ 498 DC_TimeOut 0 "FALSE" 1 "TRUE" ;
VAL_ 498 DC_Isolation_Disable_Cmd 0 "FALSE" 1 "TRUE" ;
VAL_ 498 OBCM_PLCTypeSts 0 "Not determinated" 1 "Basic signaling communication" 2 "HLC" 7 "SNA" ;
VAL_ 498 HVCMS_EVSEVoltageLimitAchieved 0 "No_limit_ach" 1 "Limit_ach" 2 "Init" 3 "SNA" ;
VAL_ 498 HVCMS_EVSEPowerLimitAchieved 0 "No_limit_ach" 1 "Limit_ach" 2 "Init" 3 "SNA" ;
VAL_ 498 HVCMS_EVSEMinimumVoltageLimit 65535 "SNA" ;
VAL_ 498 HVCMS_EVSEMaximumVoltageLimit 65535 "SNA" ;
VAL_ 498 HVCMS_EVSECurrentLimitAchieved 0 "No_limit_ach" 1 "Limit_ach" 2 "Init" 3 "SNA" ;
VAL_ 498 HVCMS_EVSEPresentCurrent 65535 "SNA" ;
VAL_ 498 EVSE_OfferedEnergyTransferType 0 "NotAvailable" 1 "AC_single_phase_core" 2 "AC_three_phase_core" 3 "DC_core" 4 "DC_extended" 5 "DC_combo_core" 6 "DC_unique" ;
VAL_ 498 HVCMS_TxMessageStat 0 "NoRequest" 1 "SupportedAppProtocolReq" 2 "SessionSetupReq" 3 "ServiceDiscoveryReq" 4 "ServiceDetailReq" 5 "PaymentServiceSelectionReq" 6 "PaymentDetailsReq" 7 "AuthorizationReq" 8 "ChargeParameterDiscoveryReq" 9 "PowerDeliveryReq" 10 "CertificateUpdateReq" 11 "CertificateInstallationReq" 12 "SessionStopReq" 13 "MeteringReceiptReq" 14 "ChargingStatusReq" 15 "CableCheckReq" 16 "PreChargeReq" 17 "CurrentDemandReq" 18 "WeldingDetectionReq" 19 "Contract_AuthenticationReq" 20 "PowerDeliveryReq_Precharge" 21 "PowerDeliveryReq_EnergyTransfer" 22 "DC_BidirectionalControlReq" 23 "PowerDeliveryReq_Renegotiation" 24 "ChargeParameterDiscovery_Reneg" 31 "SNA" ;
VAL_ 498 HVCMS_ResponseCode 0 "OK" 1 "OK_CertificateExpiresSoon" 2 "OK_NewSessionEstablished" 3 "OK_OldSessionJoined" 4 "FAILED" 5 "FAILED_SequenceError" 6 "FAILED_SignatureError" 7 "FAILED_UnknownSession" 8 "FAILED_ServiceIDInvalid" 9 "FAILED_PaymentSelectionInvalid" 10 "FAILED_ServiceSelectionInvalid" 11 "FAILED_CertificateExpired" 12 "FAILED_NoCertificateAvailable" 13 "FAILED_CertChainError" 14 "FAILED_ContractCanceled" 15 "FAILED_ChallengeInvalid" 16 "FAILED_WrongEnergyTransferType" 17 "FAILED_WrongChargeParameter" 18 "FAILED_ChargingProfileInvalid" 19 "FAILED_TariffSelectionInvalid" 20 "FAILED_EVSEPresentVoltageToLow" 21 "FAILED_PowerDeliveryNotApplied" 22 "FAILED_MeteringSignatureNotValid" 23 "OK_SuccessfullNegotiation" 24 "OK_SucceedNegotiatnMinorDeviatn" 25 "Failed_NoNegotiation" 31 "SNA" ;
VAL_ 498 HVCMS_EVSEProcessing 0 "Ongoing" 1 "Finished" ;
VAL_ 498 EVSE_FreeService 0 "Paid_Service" 1 "Free_Service" ;
VAL_ 498 TxMessageResponse 0 "No_V2G_communication_initialized" 1 "SupportedAppProtocolRes" 2 "SessionSetupRes" 3 "ServiceDiscoveryRes" 4 "ServicePaymentSelectionRes" 5 "Contract_AuthenticationRes" 6 "ChargeParameterDiscoveryRes" 7 "CableCheckRes" 8 "Pre_chargeRes" 9 "PowerDeliveryRes_Precharge" 10 "CurrentDemandRes" 11 "PowerDeliveryRes_EnergyTransfer" 12 "WeldingDetectionRes" 13 "SessionStopRes" 14 "DC_BidirectionalControlRes" 15 "ServiceDetailRes" 16 "PaymentDetailsRes" 17 "AuthorizationRes" 18 "CertificateInstallationRes" 19 "CertificateUpdateRes" 20 "MeteringReceiptRes" 21 "PowerDeliveryReq_Renegotiation" 22 "ChargeParameterDiscovery_Reneg" 31 "SNA" ;
VAL_ 498 HVCMS_EVSEStatusCode 0 "Charger_standby not ready" 1 "Charger ready charging" 2 "Charger prepaid limits exceeded" 3 "Charger shutdown" 4 "Utility interrupt event" 5 "Isolation monitoring internal" 6 "Isolation monitoring active" 7 "Charger emergency shutdown" 8 "Reserved" 9 "Reserved" 10 "Reserved" 11 "Reserved" 12 "Reserved" 13 "Charging system incompatibility" 14 "Charger malfunction" 15 "No_Data" ;
VAL_ 498 EVSE_OfferedService 0 "None" 1 "AC_DC_Charging" 2 "Certificate" 3 "InternetAccess" 4 "UseCaseInformation" 5 "Other" ;
VAL_ 498 EVSE_OfferedPaymentOptn 0 "No payment selected" 1 "External Payment" 2 "Contract" 3 "SNA" ;
VAL_ 498 EVSE_Supported_ISO1 0 "FALSE" 1 "TRUE" ;
VAL_ 498 EVSE_Supported_DIN 0 "FALSE" 1 "TRUE" ;
VAL_ 498 EVSE_Supported_SAE 0 "FALSE" 1 "TRUE" ;
VAL_ 498 EVSE_Service2_Certificate 0 "Not_Available" 1 "Available" ;
VAL_ 498 EVSE_OfferedPaymentEIM 0 "FALSE" 1 "TRUE" ;
VAL_ 498 EVSE_OfferedPaymentContract 0 "FALSE" 1 "TRUE" ;
VAL_ 498 EVSE_Notification 0 "None" 1 "StopCharging" 2 "ReNegotiation" ;
VAL_ 244 BMS_HV_Current 32767 "SNA" ;
VAL_ 244 BMS_HV_Battery_GFD_Sts 0 "GFD_Not_Performed" 1 "GFD_OK" 2 "GFD_Fail" 3 "GFD_INVALID_meas_noise" 4 "Disabled" ;
VAL_ 244 BMS_HV_Temperature_Min 2047 "SNA" ;
VAL_ 244 BMS_HV_Temperature_Max 2047 "SNA" ;
VAL_ 244 ImpactHardwireV 0 "Fail_Not_Present" 1 "Fail_Present" ;
VAL_ 244 ImpactHardwire 0 "Not_Actuate" 1 "Actuate" ;
SIG_GROUP_ 1579 HYBRID_CHARGING_STATUS_Pkt 1 : HVBatteryVoltage_MinCal HVBatteryVoltage_MaxCal HVBatteryCurrent_MaxCal ChargeSystemFaultReason ACCurrent_MaxCal ChargingLevel OBCM_PLUG_STS VDCM_UDCChrgr VDCM_IDCChrgr ChargeSystemSts ChargeSystemFault CRC_HYBRID_CHARGING_STATUS MessageCounter_HYBRID_CHARGING_S;
SIG_GROUP_ 478 HYBRID_CHARGING_COMMAND_Pkt 1 : LVDC_VoltageSetpoint LVDC_SystemVoltageAct LVDC_CurrentSetpoint HVInverterVoltage_Rational HVDC_VoltageSetpoint HVDC_CurrentSetpoint EchargeSOCRange_ePT CRC_HYBRID_CHARGING_COMMAND VoltageRequest OBC_ModeRequest OBC_ControlMethod MainHV_ContactorCommand J1772_CloseS2 HVInverterVoltage_RationalV HVBatCoolantLevelLow DCDC_OperationModeEnable ClearLegislatedDiagInfo OBC_OperativeModeReq HV_Volt_Min_Thrsh HV_Volt_Max_Thrsh DC_Curr_Max_Thrsh ChargeEnable AC_Curr_Min_Thrsh AC_Curr_Max_Thrsh CurrentRequest VDCM_StsWldgReq VDCM_SessnStopReq VDCM_StsSWWldgReq MessageCounter_HYBRID_CHARGING_C MaxCurrentAllwd;
SIG_GROUP_ 244 BATTERY_HV_Pkt 1 : BMS_HV_InternalVoltage BMS_HV_Current BMS_HV_Battery_GFD_Sts BMS_HV_Temperature_Min BMS_HV_Temperature_Max ImpactHardwireV ImpactHardwire;
